BU_:  Airbag BAP_Tester ICAS1_Gateway ICAS1_KommunikationsServer LE1 LE2 Motor_BEV Schaltbetaetigung

BU_:  Airbag BAP_Tester ICAS1_Gateway ICAS1_KommunikationsServer LE1 LE2 Motor_BEV Schaltbetaetigung

BO_ 2463978663 VZE_04: 32 ICAS1_Gateway
 SG_ VZE_Anzeigemodus  : 0|2@1+ (1.000000,0.000000) [0.000000|3.000000] "" Vector__XXX
 SG_ VZE_Hinweistext  : 2|3@1+ (1.000000,0.000000) [1.000000|7.000000] "" Motor_BEV
 SG_ VZE_Verkehrszeichen_Einheit  : 8|1@1+ (1.000000,0.000000) [0.000000|1.000000] "" Vector__XXX
 SG_ VZE_Anzeigeunterdrueck_Zeichen_3  : 9|1@1+ (1.000000,0.000000) [0.000000|1.000000] "" Vector__XXX
 SG_ VZE_Anzeigeunterdrueck_Zeichen_2  : 10|1@1+ (1.000000,0.000000) [0.000000|1.000000] "" Vector__XXX
 SG_ VZE_Verkehrszeichen_1  : 11|8@1+ (1.000000,0.000000) [1.000000|255.000000] "" Motor_BEV
 SG_ VZE_Verkehrszeichen_2  : 19|8@1+ (1.000000,0.000000) [1.000000|255.000000] "" Vector__XXX
 SG_ VZE_Verkehrszeichen_3  : 27|8@1+ (1.000000,0.000000) [1.000000|255.000000] "" Vector__XXX
 SG_ VZE_Warnung_Verkehrszeichen_1  : 35|1@1+ (1.000000,0.000000) [0.000000|1.000000] "" Vector__XXX
 SG_ VZE_Warnung_Verkehrszeichen_2  : 36|1@1+ (1.000000,0.000000) [0.000000|1.000000] "" Vector__XXX
 SG_ VZE_Warnung_Verkehrszeichen_3  : 37|1@1+ (1.000000,0.000000) [0.000000|1.000000] "" Vector__XXX
 SG_ VZE_Zusatzschild_1  : 38|4@1+ (1.000000,0.000000) [1.000000|15.000000] "" Vector__XXX
 SG_ VZE_Zusatzschild_2  : 42|4@1+ (1.000000,0.000000) [1.000000|15.000000] "" Vector__XXX
 SG_ VZE_Zusatzschild_3  : 46|4@1+ (1.000000,0.000000) [1.000000|15.000000] "" Vector__XXX
 SG_ VZE_Anzeigeunterdrueck_Zeichen_1  : 50|1@1+ (1.000000,0.000000) [0.000000|1.000000] "" Vector__XXX
 SG_ VZE_Zeichen_01_KameraWied  : 51|1@1+ (1.000000,0.000000) [0.000000|1.000000] "" Motor_BEV
 SG_ VZE_Zeichen_02_KameraWied  : 52|1@1+ (1.000000,0.000000) [0.000000|1.000000] "" Vector__XXX
 SG_ VZE_Zeichen_03_KameraWied  : 53|1@1+ (1.000000,0.000000) [0.000000|1.000000] "" Vector__XXX
 SG_ VZE_Zeichen_01_Kamera  : 54|1@1+ (1.000000,0.000000) [0.000000|1.000000] "" Motor_BEV
 SG_ VZE_Zeichen_01_Karte  : 55|1@1+ (1.000000,0.000000) [0.000000|1.000000] "" Vector__XXX
 SG_ VZE_Zeichen_01_Gesetz  : 56|1@1+ (1.000000,0.000000) [0.000000|1.000000] "" Vector__XXX
 SG_ VZE_Zeichen_02_Kamera  : 57|1@1+ (1.000000,0.000000) [0.000000|1.000000] "" Vector__XXX
 SG_ VZE_Zeichen_02_Karte  : 58|1@1+ (1.000000,0.000000) [0.000000|1.000000] "" Vector__XXX
 SG_ VZE_Zeichen_02_Gesetz  : 59|1@1+ (1.000000,0.000000) [0.000000|1.000000] "" Vector__XXX
 SG_ VZE_Zeichen_03_Kamera  : 60|1@1+ (1.000000,0.000000) [0.000000|1.000000] "" Vector__XXX
 SG_ VZE_Zeichen_03_Karte  : 61|1@1+ (1.000000,0.000000) [0.000000|1.000000] "" Vector__XXX
 SG_ VZE_Zeichen_03_Gesetz  : 62|1@1+ (1.000000,0.000000) [0.000000|1.000000] "" Vector__XXX
 SG_ VZE_Gong  : 63|1@1+ (1.000000,0.000000) [0.000000|1.000000] "" Vector__XXX
 SG_ VZE_Anzeigeunterdrueck_Zeichen_5  : 72|1@1+ (1.000000,0.000000) [0.000000|1.000000] "" Vector__XXX
 SG_ VZE_Zeichen_05_KameraWied  : 73|1@1+ (1.000000,0.000000) [0.000000|1.000000] "" Vector__XXX
 SG_ VZE_Zeichen_05_Kamera  : 74|1@1+ (1.000000,0.000000) [0.000000|1.000000] "" Vector__XXX
 SG_ VZE_Verkehrszeichen_4  : 75|8@1+ (1.000000,0.000000) [1.000000|255.000000] "" Motor_BEV
 SG_ VZE_Verkehrszeichen_5  : 83|8@1+ (1.000000,0.000000) [1.000000|255.000000] "" Motor_BEV
 SG_ VZE_Anhaenger_Vmax  : 91|4@1+ (10.000000,10.000000) [10.000000|140.000000] "Unit_KiloMeterPerHour" Vector__XXX
 SG_ VZE_Zeichen_04_Gesetz  : 95|1@1+ (1.000000,0.000000) [0.000000|1.000000] "" Vector__XXX
 SG_ VZE_Zeichen_04_Kamera  : 96|1@1+ (1.000000,0.000000) [0.000000|1.000000] "" Vector__XXX
 SG_ VZE_Zeichen_04_KameraWied  : 97|1@1+ (1.000000,0.000000) [0.000000|1.000000] "" Vector__XXX
 SG_ VZE_Zeichen_04_Karte  : 98|1@1+ (1.000000,0.000000) [0.000000|1.000000] "" Vector__XXX
 SG_ VZE_Warnung_Verkehrszeichen_4  : 99|1@1+ (1.000000,0.000000) [0.000000|1.000000] "" Vector__XXX
 SG_ VZE_Warnung_Verkehrszeichen_5  : 100|1@1+ (1.000000,0.000000) [0.000000|1.000000] "" Vector__XXX
 SG_ VZE_Zeichen_05_Gesetz  : 101|1@1+ (1.000000,0.000000) [0.000000|1.000000] "" Vector__XXX
 SG_ VZE_Zusatzschild_4  : 102|4@1+ (1.000000,0.000000) [1.000000|15.000000] "" Vector__XXX
 SG_ VZE_Zusatzschild_5  : 106|4@1+ (1.000000,0.000000) [1.000000|15.000000] "" Vector__XXX
 SG_ VZE_Baustelle  : 110|2@1+ (1.000000,0.000000) [0.000000|3.000000] "" Vector__XXX
 SG_ VZE_Zeichen_05_Karte  : 112|1@1+ (1.000000,0.000000) [0.000000|1.000000] "" Vector__XXX
 SG_ VZE_Zeichen_05_Entfernung  : 113|7@1+ (1.000000,0.000000) [1.000000|127.000000] "Unit_Meter" Motor_BEV
 SG_ VZE_Zeichen_05_Entfernung_StdA  : 120|7@1+ (1.000000,0.000000) [1.000000|127.000000] "Unit_Meter" Motor_BEV
 SG_ VZE_Anzeigeunterdrueck_Zeichen_4  : 127|1@1+ (1.000000,0.000000) [0.000000|1.000000] "" Vector__XXX
 SG_ VZE_Verkehrszeichen_6  : 128|8@1+ (1.000000,0.000000) [1.000000|255.000000] "Unit_None" Motor_BEV
 SG_ VZE_Zusatzschild_6  : 136|4@1+ (1.000000,0.000000) [1.000000|15.000000] "" Vector__XXX
 SG_ VZE_Zeichen_06_Entfernung  : 140|7@1+ (1.000000,0.000000) [1.000000|127.000000] "Unit_Meter" Motor_BEV
 SG_ VZE_Zeichen_06_Entfernung_StdA  : 147|7@1+ (1.000000,0.000000) [1.000000|127.000000] "Unit_Meter" Motor_BEV
 SG_ VZE_Umweltinfo_Naesse  : 154|1@1+ (1.000000,0.000000) [0.000000|1.000000] "" Motor_BEV
 SG_ VZE_Umweltinfo_Nebel  : 155|1@1+ (1.000000,0.000000) [0.000000|1.000000] "" Motor_BEV
 SG_ VZE_Umweltinfo_Anhaengerbetrieb  : 156|1@1+ (1.000000,0.000000) [0.000000|1.000000] "" Vector__XXX
 SG_ VZE_Erweiterte_Information  : 157|8@1+ (1.000000,0.000000) [1.000000|255.000000] "Unit_None" Vector__XXX
 SG_ VZE_Tempowarnung_Status  : 165|1@1+ (1.000000,0.000000) [0.000000|1.000000] "" Vector__XXX
 SG_ VZE_Tempowarnung_Einheit  : 166|1@1+ (1.000000,0.000000) [0.000000|1.000000] "" Vector__XXX
 SG_ VZE_Tempowarnung_Offset  : 167|5@1+ (1.000000,0.000000) [1.000000|31.000000] "" Vector__XXX
 SG_ VZE_FoD_Status  : 206|2@1+ (1.000000,0.000000) [0.000000|3.000000] "" Vector__XXX
 SG_ VZE_Anzeige_ZS_1  : 208|4@1+ (1.000000,0.000000) [1.000000|15.000000] "Unit_None" Vector__XXX
 SG_ VZE_Anzeige_ZS_2  : 212|4@1+ (1.000000,0.000000) [1.000000|15.000000] "Unit_None" Vector__XXX
 SG_ VZE_Anzeige_ZS_3  : 216|4@1+ (1.000000,0.000000) [1.000000|15.000000] "Unit_None" Vector__XXX
 SG_ VZE_Hinweistext_03  : 220|4@1+ (1.000000,0.000000) [1.000000|15.000000] "" Vector__XXX
 SG_ VZE_Land  : 224|5@1+ (1.000000,0.000000) [1.000000|31.000000] "" Vector__XXX
 SG_ VZE_Warnung_VZ_1  : 229|1@1+ (1.000000,0.000000) [0.000000|1.000000] "" Vector__XXX
 SG_ VZE_Warnung_VZ_2  : 230|1@1+ (1.000000,0.000000) [0.000000|1.000000] "" Vector__XXX
 SG_ VZE_Warnung_VZ_3  : 231|1@1+ (1.000000,0.000000) [0.000000|1.000000] "" Vector__XXX
 SG_ VZE_Anzeige_VZ_1  : 232|8@1+ (1.000000,0.000000) [1.000000|255.000000] "" Vector__XXX
 SG_ VZE_Anzeige_VZ_2  : 240|8@1+ (1.000000,0.000000) [1.000000|255.000000] "Unit_None" Vector__XXX
 SG_ VZE_Anzeige_VZ_3  : 248|8@1+ (1.000000,0.000000) [1.000000|255.000000] "Unit_None" Vector__XXX

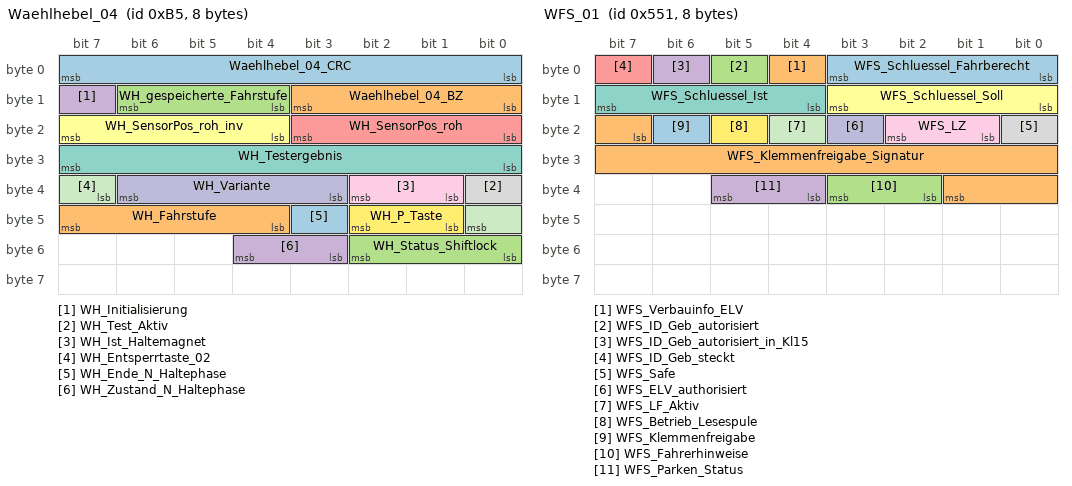
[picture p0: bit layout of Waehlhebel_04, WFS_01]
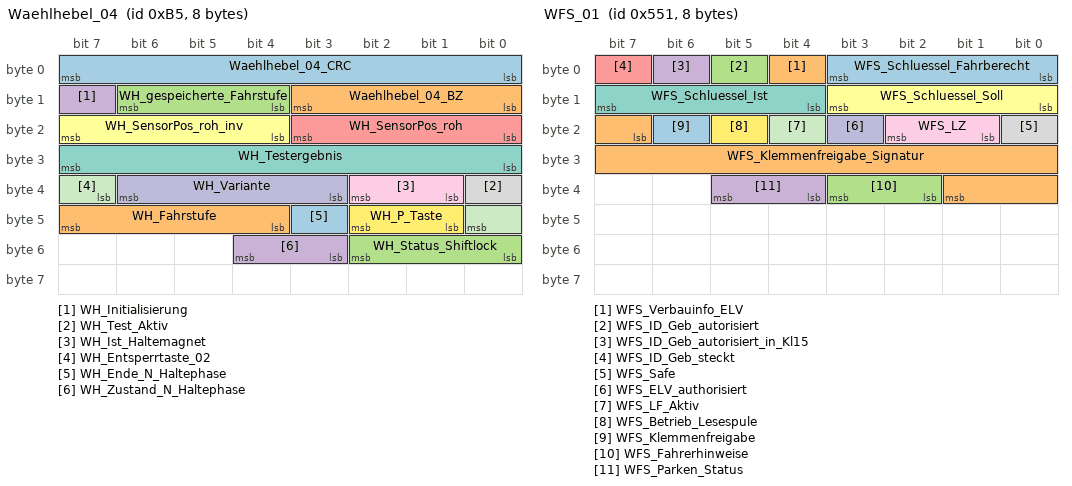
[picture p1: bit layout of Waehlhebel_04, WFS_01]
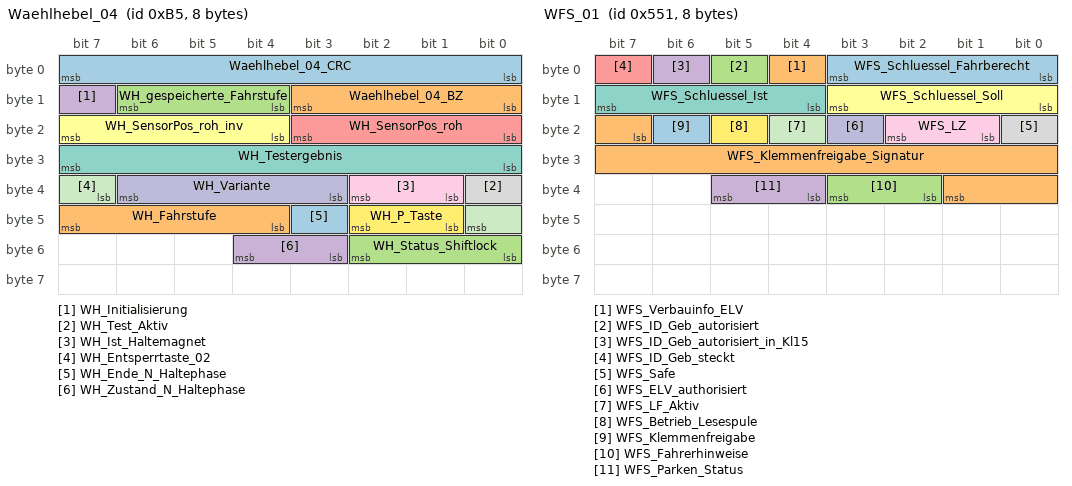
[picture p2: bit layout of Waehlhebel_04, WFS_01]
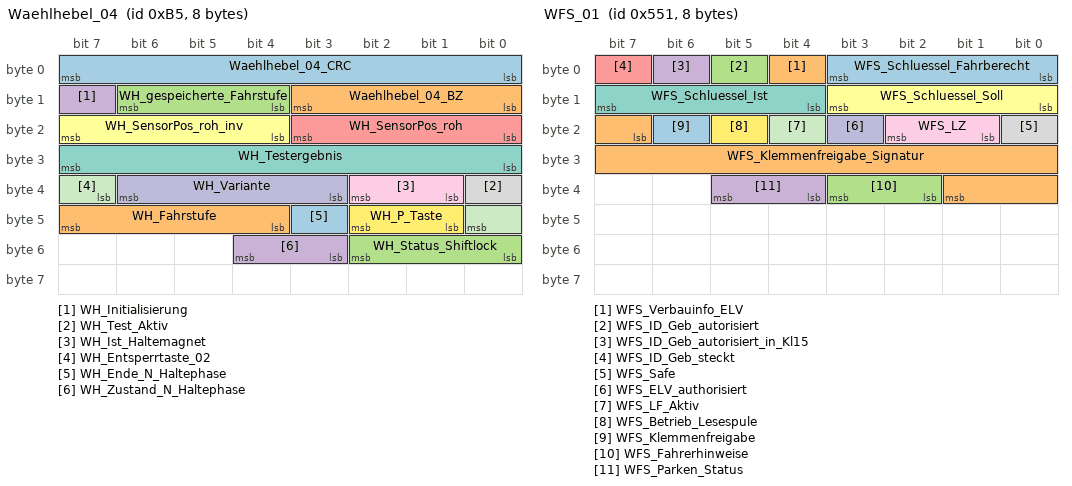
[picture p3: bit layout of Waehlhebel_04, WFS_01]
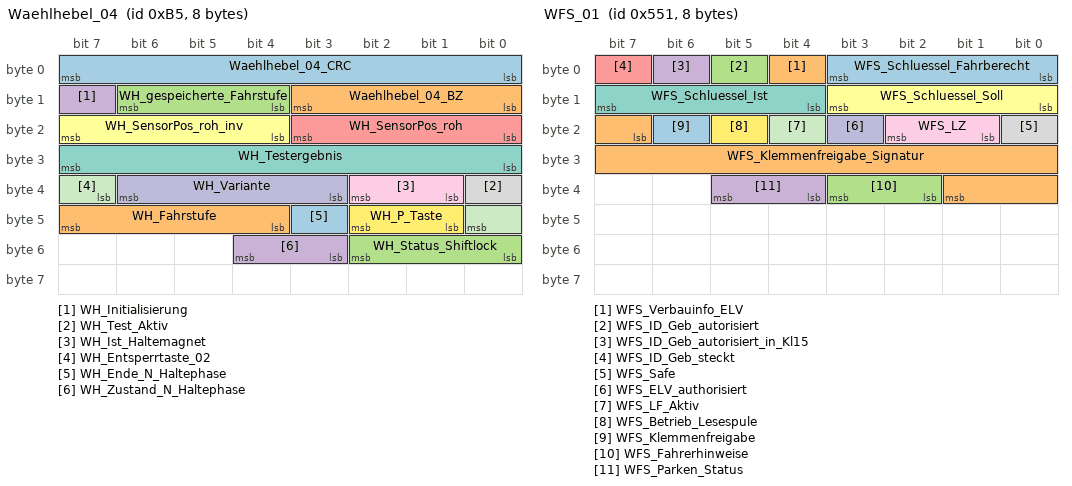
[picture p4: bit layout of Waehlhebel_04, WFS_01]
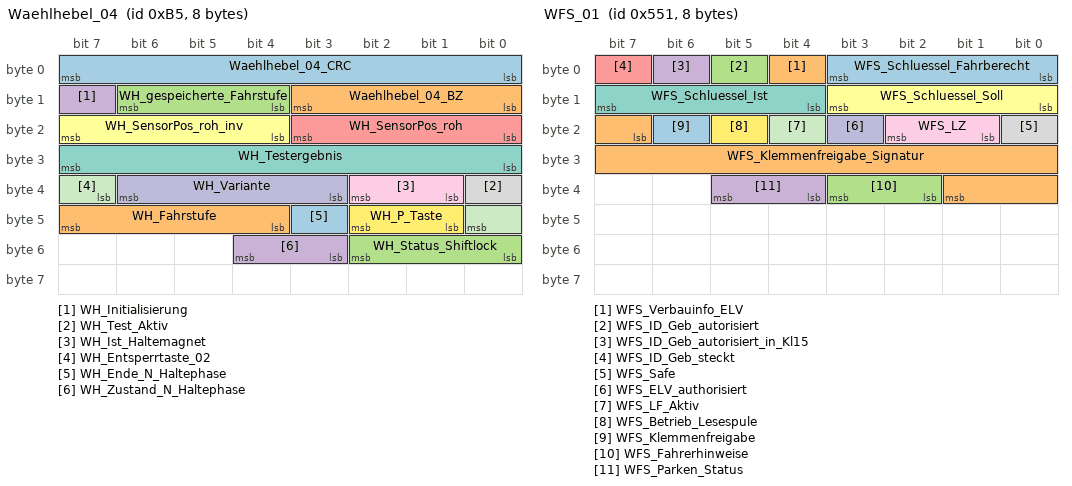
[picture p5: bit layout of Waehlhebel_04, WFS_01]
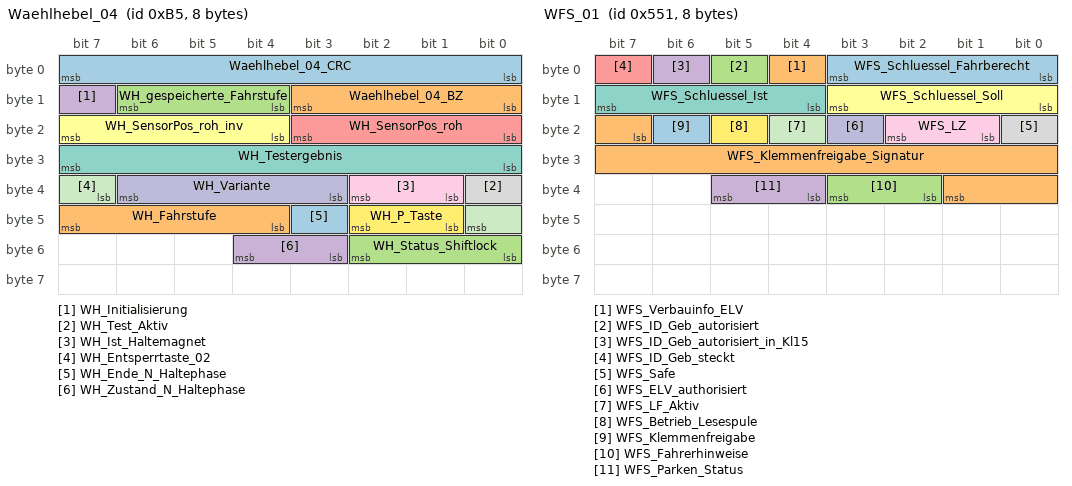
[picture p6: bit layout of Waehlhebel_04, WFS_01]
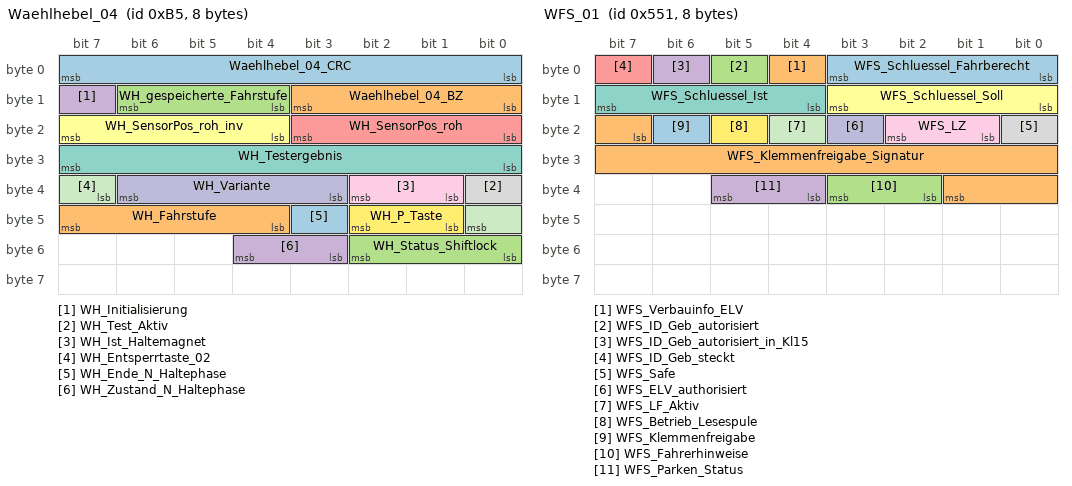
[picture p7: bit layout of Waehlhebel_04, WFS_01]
BO_ 181 Waehlhebel_04: 8 ICAS1_Gateway
 SG_ Waehlhebel_04_CRC  : 0|8@1+ (1.000000,0.000000) [0.000000|255.000000] "" Motor_BEV
 SG_ Waehlhebel_04_BZ  : 8|4@1+ (1.000000,0.000000) [0.000000|15.000000] "" Motor_BEV
 SG_ WH_gespeicherte_Fahrstufe  : 12|3@1+ (1.000000,0.000000) [0.000000|7.000000] "" Vector__XXX
 SG_ WH_Initialisierung  : 15|1@1+ (1.000000,0.000000) [0.000000|1.000000] "" Motor_BEV
 SG_ WH_SensorPos_roh  : 16|4@1+ (1.000000,0.000000) [0.000000|15.000000] "" Motor_BEV
 SG_ WH_SensorPos_roh_inv  : 20|4@1+ (1.000000,0.000000) [0.000000|15.000000] "" Motor_BEV
 SG_ WH_Testergebnis  : 24|8@1+ (1.000000,0.000000) [0.000000|255.000000] "" Vector__XXX
 SG_ WH_Test_Aktiv  : 32|1@1+ (1.000000,0.000000) [0.000000|1.000000] "" Vector__XXX
 SG_ WH_Ist_Haltemagnet  : 33|2@1+ (1.000000,0.000000) [0.000000|3.000000] "" Motor_BEV
 SG_ WH_Variante  : 35|4@1+ (1.000000,0.000000) [0.000000|15.000000] "" Motor_BEV
 SG_ WH_Entsperrtaste_02  : 39|2@1+ (1.000000,0.000000) [0.000000|3.000000] "" Motor_BEV
 SG_ WH_P_Taste  : 41|2@1+ (1.000000,0.000000) [0.000000|3.000000] "" Motor_BEV
 SG_ WH_Ende_N_Haltephase  : 43|1@1+ (1.000000,0.000000) [0.000000|1.000000] "" Vector__XXX
 SG_ WH_Fahrstufe  : 44|4@1+ (1.000000,0.000000) [0.000000|15.000000] "" Motor_BEV
 SG_ WH_Status_Shiftlock  : 48|3@1+ (1.000000,0.000000) [0.000000|7.000000] "" Motor_BEV
 SG_ WH_Zustand_N_Haltephase  : 51|2@1+ (1.000000,0.000000) [0.000000|3.000000] "" Vector__XXX

BO_ 2463978687 Waehlhebel_06: 8 ICAS1_Gateway
 SG_ WH_Fehler_Haltemagnet_Status  : 41|1@1+ (1.000000,0.000000) [0.000000|1.000000] "" Motor_BEV
 SG_ WH_Fehler_CRC_SBM  : 42|1@1+ (1.000000,0.000000) [0.000000|1.000000] "" Motor_BEV
 SG_ WH_Fehler_CRC_SBM_Status  : 43|1@1+ (1.000000,0.000000) [0.000000|1.000000] "" Motor_BEV
 SG_ WH_Fehler_Timeout_SBM  : 44|1@1+ (1.000000,0.000000) [0.000000|1.000000] "" Motor_BEV
 SG_ WH_Fehler_Timeout_SBM_Status  : 45|1@1+ (1.000000,0.000000) [0.000000|1.000000] "" Motor_BEV
 SG_ WH_Fehler_Ueberspannung  : 46|1@1+ (1.000000,0.000000) [0.000000|1.000000] "" Motor_BEV
 SG_ WH_Fehler_Ueberspannung_Status  : 47|1@1+ (1.000000,0.000000) [0.000000|1.000000] "" Motor_BEV
 SG_ WH_Fehler_BZ_SBM  : 48|1@1+ (1.000000,0.000000) [0.000000|1.000000] "" Motor_BEV
 SG_ WH_Fehler_BZ_SBM_Status  : 49|1@1+ (1.000000,0.000000) [0.000000|1.000000] "" Motor_BEV
 SG_ WH_Fehler_Unterspannung  : 50|1@1+ (1.000000,0.000000) [0.000000|1.000000] "" Motor_BEV
 SG_ WH_Fehler_Unterspannung_Status  : 51|1@1+ (1.000000,0.000000) [0.000000|1.000000] "" Motor_BEV
 SG_ WH_Fehler_Ausleuchtung  : 52|1@1+ (1.000000,0.000000) [0.000000|1.000000] "" Motor_BEV
 SG_ WH_Fehler_Ausleuchtung_Status  : 53|1@1+ (1.000000,0.000000) [0.000000|1.000000] "" Motor_BEV
 SG_ WH_Fehler_Entsperrtaste  : 54|1@1+ (1.000000,0.000000) [0.000000|1.000000] "" Motor_BEV
 SG_ WH_Fehler_Entsperrtaste_Status  : 55|1@1+ (1.000000,0.000000) [0.000000|1.000000] "" Motor_BEV
 SG_ WH_Fehler_P_Taste  : 56|1@1+ (1.000000,0.000000) [0.000000|1.000000] "" Motor_BEV
 SG_ WH_Fehler_P_Taste_Status  : 57|1@1+ (1.000000,0.000000) [0.000000|1.000000] "" Motor_BEV
 SG_ WH_Fehler_Sensor_einfach  : 58|1@1+ (1.000000,0.000000) [0.000000|1.000000] "" Motor_BEV
 SG_ WH_Fehler_Sensor_einfach_Status  : 59|1@1+ (1.000000,0.000000) [0.000000|1.000000] "" Motor_BEV
 SG_ WH_Fehler_Sensor_mehrfach  : 60|1@1+ (1.000000,0.000000) [0.000000|1.000000] "" Motor_BEV
 SG_ WH_Fehler_Sensor_mehrfach_Status  : 61|1@1+ (1.000000,0.000000) [0.000000|1.000000] "" Motor_BEV
 SG_ WH_Fehler_Shiftlock  : 62|1@1+ (1.000000,0.000000) [0.000000|1.000000] "" Motor_BEV
 SG_ WH_Fehler_Shiftlock_Status  : 63|1@1+ (1.000000,0.000000) [0.000000|1.000000] "" Motor_BEV

BO_ 916 WBA_03: 8 Motor_BEV
 SG_ WBA_03_CRC  : 0|8@1+ (1.000000,0.000000) [0.000000|255.000000] "" ICAS1_Gateway
 SG_ WBA_03_BZ  : 8|4@1+ (1.000000,0.000000) [0.000000|15.000000] "" ICAS1_Gateway
 SG_ WBA_Fahrstufe_02  : 12|4@1+ (1.000000,0.000000) [0.000000|15.000000] "" ICAS1_Gateway ICAS1_KommunikationsServer
 SG_ WBA_ZielFahrstufe  : 16|4@1+ (1.000000,0.000000) [0.000000|15.000000] "" ICAS1_Gateway
 SG_ WBA_GE_Warnung_02  : 20|4@1+ (1.000000,0.000000) [0.000000|15.000000] "" ICAS1_Gateway
 SG_ WBA_eing_Gang_02  : 24|4@1+ (1.000000,0.000000) [0.000000|15.000000] "" ICAS1_Gateway
 SG_ WBA_GE_Texte  : 28|3@1+ (1.000000,0.000000) [0.000000|7.000000] "" ICAS1_Gateway
 SG_ WBA_Segeln_aktiv  : 31|1@1+ (1.000000,0.000000) [0.000000|1.000000] "" ICAS1_Gateway
 SG_ WBA_Schaltschema_02  : 32|3@1+ (1.000000,0.000000) [0.000000|7.000000] "" ICAS1_Gateway
 SG_ WBA_Schaltschema_FS_inaktiv  : 35|2@1+ (1.000000,0.000000) [0.000000|3.000000] "" ICAS1_Gateway
 SG_ WBA_GE_Zusatzwarnungen  : 37|3@1+ (1.000000,0.000000) [0.000000|7.000000] "" ICAS1_Gateway
 SG_ GE_Sollgang  : 40|4@1+ (1.000000,0.000000) [0.000000|15.000000] "" ICAS1_Gateway
 SG_ GE_Tipschaltempf_verfuegbar  : 44|1@1+ (1.000000,0.000000) [0.000000|1.000000] "" ICAS1_Gateway
 SG_ WBA_GE_Texte_02  : 45|3@1+ (1.000000,0.000000) [0.000000|7.000000] "" ICAS1_Gateway
 SG_ WBA_Schaltschema_Tippgasse  : 48|1@1+ (1.000000,0.000000) [0.000000|1.000000] "" ICAS1_Gateway
 SG_ WBA_Schaltschema_Fahreraktion  : 49|1@1+ (1.000000,0.000000) [0.000000|1.000000] "" ICAS1_Gateway
 SG_ WBA_Schaltschema_FS_vorwaerts  : 50|2@1+ (1.000000,0.000000) [0.000000|3.000000] "" ICAS1_Gateway
 SG_ WBA_Shiftlock_Lampe  : 52|1@1+ (1.000000,0.000000) [0.000000|1.000000] "" ICAS1_Gateway
 SG_ WBA_Anforderung_Akustik  : 53|1@1+ (1.000000,0.000000) [0.000000|1.000000] "" ICAS1_Gateway
 SG_ WBA_Blinken  : 54|1@1+ (1.000000,0.000000) [0.000000|1.000000] "" ICAS1_Gateway
 SG_ GE_Wiederstart_Anz_Std  : 55|1@1+ (1.000000,0.000000) [0.000000|1.000000] "" ICAS1_Gateway
 SG_ GE_Stoppverbot_Anz_01  : 56|1@1+ (1.000000,0.000000) [0.000000|1.000000] "" ICAS1_Gateway
 SG_ GE_Stoppverbot_Anz_02  : 57|1@1+ (1.000000,0.000000) [0.000000|1.000000] "" ICAS1_Gateway
 SG_ GE_Stoppverbot_Anz_03  : 58|1@1+ (1.000000,0.000000) [0.000000|1.000000] "" ICAS1_Gateway
 SG_ GE_Stoppverbot_Anz_04  : 59|1@1+ (1.000000,0.000000) [0.000000|1.000000] "" ICAS1_Gateway
 SG_ GE_Stoppverbot_Anz_05  : 60|1@1+ (1.000000,0.000000) [0.000000|1.000000] "" ICAS1_Gateway
 SG_ GE_Stoppverbot_Anz_06  : 61|1@1+ (1.000000,0.000000) [0.000000|1.000000] "" ICAS1_Gateway
 SG_ GE_Stoppverbot_Anz_07  : 62|1@1+ (1.000000,0.000000) [0.000000|1.000000] "" ICAS1_Gateway
 SG_ GE_Stoppverbot_Anz_Std  : 63|1@1+ (1.000000,0.000000) [0.000000|1.000000] "" ICAS1_Gateway

BO_ 1361 WFS_01: 8 ICAS1_Gateway
 SG_ WFS_Schluessel_Fahrberecht  : 0|4@1+ (1.000000,0.000000) [0.000000|15.000000] "" Vector__XXX
 SG_ WFS_Verbauinfo_ELV  : 4|1@1+ (1.000000,0.000000) [0.000000|1.000000] "" Vector__XXX
 SG_ WFS_ID_Geb_autorisiert  : 5|1@1+ (1.000000,0.000000) [0.000000|1.000000] "" Vector__XXX
 SG_ WFS_ID_Geb_autorisiert_in_Kl15  : 6|1@1+ (1.000000,0.000000) [0.000000|1.000000] "" Vector__XXX
 SG_ WFS_ID_Geb_steckt  : 7|1@1+ (1.000000,0.000000) [0.000000|1.000000] "" Vector__XXX
 SG_ WFS_Schluessel_Soll  : 8|4@1+ (1.000000,0.000000) [0.000000|15.000000] "" Vector__XXX
 SG_ WFS_Schluessel_Ist  : 12|4@1+ (1.000000,0.000000) [0.000000|15.000000] "" Vector__XXX
 SG_ WFS_Safe  : 16|1@1+ (1.000000,0.000000) [0.000000|1.000000] "" Vector__XXX
 SG_ WFS_LZ  : 17|2@1+ (1.000000,0.000000) [0.000000|3.000000] "" Vector__XXX
 SG_ WFS_ELV_authorisiert  : 19|1@1+ (1.000000,0.000000) [0.000000|1.000000] "" Vector__XXX
 SG_ WFS_LF_Aktiv  : 20|1@1+ (1.000000,0.000000) [0.000000|1.000000] "" Vector__XXX
 SG_ WFS_Betrieb_Lesespule  : 21|1@1+ (1.000000,0.000000) [0.000000|1.000000] "" Vector__XXX
 SG_ WFS_Klemmenfreigabe  : 22|1@1+ (1.000000,0.000000) [0.000000|1.000000] "" Motor_BEV
 SG_ WFS_Klemmenfreigabe_Signatur  : 23|11@1+ (1.000000,0.000000) [0.000000|2047.000000] "" Vector__XXX
 SG_ WFS_Fahrerhinweise  : 34|2@1+ (1.000000,0.000000) [0.000000|3.000000] "" Vector__XXX
 SG_ WFS_Parken_Status  : 36|2@1+ (1.000000,0.000000) [0.000000|3.000000] "" Vector__XXX

BO_ 2617028096 XCP_Airbag_CRO_01: 64 Vector__XXX
 SG_ XCP_Airbag_CRO_01_Data  : 0|512@1+ (1.000000,0.000000) [0.000000|13407807929942597099574024998205846127479365820592393377723561443721764030073546976801874298166903427690031858186486050853753882811946569946433649006084096.000000] "" Airbag

BO_ 2617028097 XCP_Airbag_DTO_01: 64 Airbag
 SG_ XCP_Airbag_DTO_01_Data  : 0|512@1+ (1.000000,0.000000) [0.000000|13407807929942597099574024998205846127479365820592393377723561443721764030073546976801874298166903427690031858186486050853753882811946569946433649006084096.000000] "" Vector__XXX

BO_ 2617239040 XCP_EMotor_01_CRO_01: 64 Vector__XXX
 SG_ XCP_EMotor_01_CRO_01_Data  : 0|64@1+ (1.000000,0.000000) [0.000000|18446744073709551616.000000] "" LE1

BO_ 2617239041 XCP_EMotor_01_DTO_01: 64 LE1
 SG_ XCP_EMotor_01_DTO_01_Data  : 0|64@1+ (1.000000,0.000000) [0.000000|18446744073709551616.000000] "" Vector__XXX

BO_ 2617239042 XCP_EMotor_01_DTO_02: 64 LE1
 SG_ XCP_EMotor_01_DTO_02_Data  : 0|64@1+ (1.000000,0.000000) [0.000000|18446744073709551616.000000] "" Vector__XXX

BO_ 2617239043 XCP_EMotor_01_DTO_03: 64 LE1
 SG_ XCP_EMotor_01_DTO_03_Data  : 0|64@1+ (1.000000,0.000000) [0.000000|18446744073709551616.000000] "" Vector__XXX

BO_ 2617239044 XCP_EMotor_01_DTO_04: 64 LE1
 SG_ XCP_EMotor_01_DTO_04_Data  : 0|64@1+ (1.000000,0.000000) [0.000000|18446744073709551616.000000] "" Vector__XXX

BO_ 2617122304 XCP_EMotor_02_CRO_01: 64 Vector__XXX
 SG_ XCP_EMotor_02_CRO_01_Data  : 0|64@1+ (1.000000,0.000000) [0.000000|18446744073709551616.000000] "" LE2

BO_ 2617122305 XCP_EMotor_02_DTO_01: 64 LE2
 SG_ XCP_EMotor_02_DTO_01_Data  : 0|64@1+ (1.000000,0.000000) [0.000000|18446744073709551616.000000] "" Vector__XXX

BO_ 2617122306 XCP_EMotor_02_DTO_02: 64 LE2
 SG_ XCP_EMotor_02_DTO_02_Data  : 0|64@1+ (1.000000,0.000000) [0.000000|18446744073709551616.000000] "" Vector__XXX

BO_ 2617122307 XCP_EMotor_02_DTO_03: 64 LE2
 SG_ XCP_EMotor_02_DTO_03_Data  : 0|64@1+ (1.000000,0.000000) [0.000000|18446744073709551616.000000] "" Vector__XXX

BO_ 2617122308 XCP_EMotor_02_DTO_04: 64 LE2
 SG_ XCP_EMotor_02_DTO_04_Data  : 0|64@1+ (1.000000,0.000000) [0.000000|18446744073709551616.000000] "" Vector__XXX

BO_ 2617226768 XCP_Motor_CRO_01: 64 Vector__XXX
 SG_ XCP_Motor_CRO_01_Data  : 0|64@1+ (1.000000,0.000000) [0.000000|18446744073709551616.000000] "" Motor_BEV

BO_ 2617226769 XCP_Motor_DTO_01: 64 Motor_BEV
 SG_ XCP_Motor_DTO_01_Data  : 0|64@1+ (1.000000,0.000000) [0.000000|18446744073709551616.000000] "" Vector__XXX

BO_ 1411 ZV_02: 8 ICAS1_Gateway
 SG_ ZV_verriegeln_Anf  : 0|1@1+ (1.000000,0.000000) [0.000000|1.000000] "" Vector__XXX
 SG_ ZV_STSG_HFS_Anf  : 1|1@1+ (1.000000,0.000000) [0.000000|1.000000] "" Vector__XXX
 SG_ ZV_STSG_HBFS_Anf  : 2|1@1+ (1.000000,0.000000) [0.000000|1.000000] "" Vector__XXX
 SG_ ZV_Anf_Challenge_Auth  : 3|1@1+ (1.000000,0.000000) [0.000000|1.000000] "" Vector__XXX
 SG_ BCM_FH_Freigabe  : 12|1@1+ (1.000000,0.000000) [0.000000|1.000000] "" Vector__XXX
 SG_ BCM_Komfortfkt_Freigabe  : 13|1@1+ (1.000000,0.000000) [0.000000|1.000000] "" Vector__XXX
 SG_ BCM_HSK_Freigabe  : 14|1@1+ (1.000000,0.000000) [0.000000|1.000000] "" Vector__XXX
 SG_ BCM_Verdeck_Freigabe  : 15|1@1+ (1.000000,0.000000) [0.000000|1.000000] "" Vector__XXX
 SG_ ZV_verriegelt_intern_ist  : 16|1@1+ (1.000000,0.000000) [0.000000|1.000000] "" Vector__XXX
 SG_ ZV_verriegelt_extern_ist  : 17|1@1+ (1.000000,0.000000) [0.000000|1.000000] "" Airbag
 SG_ ZV_verriegelt_intern_soll  : 18|1@1+ (1.000000,0.000000) [0.000000|1.000000] "" Vector__XXX
 SG_ ZV_verriegelt_extern_soll  : 19|1@1+ (1.000000,0.000000) [0.000000|1.000000] "" Airbag
 SG_ ZV_gesafet_extern_ist  : 20|1@1+ (1.000000,0.000000) [0.000000|1.000000] "" Vector__XXX
 SG_ ZV_gesafet_extern_soll  : 21|1@1+ (1.000000,0.000000) [0.000000|1.000000] "" Vector__XXX
 SG_ ZV_Einzeltuerentriegelung  : 22|1@1+ (1.000000,0.000000) [0.000000|1.000000] "" Vector__XXX
 SG_ ZV_Heckeinzelentriegelung  : 23|1@1+ (1.000000,0.000000) [0.000000|1.000000] "" Vector__XXX
 SG_ ZV_FT_offen  : 24|1@1+ (1.000000,0.000000) [0.000000|1.000000] "" Motor_BEV
 SG_ ZV_BT_offen  : 25|1@1+ (1.000000,0.000000) [0.000000|1.000000] "" Motor_BEV
 SG_ ZV_HFS_offen  : 26|1@1+ (1.000000,0.000000) [0.000000|1.000000] "" Motor_BEV
 SG_ ZV_HBFS_offen  : 27|1@1+ (1.000000,0.000000) [0.000000|1.000000] "" Motor_BEV
 SG_ ZV_HD_offen  : 28|1@1+ (1.000000,0.000000) [0.000000|1.000000] "" Motor_BEV
 SG_ ZV_HS_offen  : 29|1@1+ (1.000000,0.000000) [0.000000|1.000000] "" Vector__XXX
 SG_ IRUE_aktiv  : 30|1@1+ (1.000000,0.000000) [0.000000|1.000000] "" Vector__XXX
 SG_ DWA_aktiv  : 31|1@1+ (1.000000,0.000000) [0.000000|1.000000] "" Vector__XXX
 SG_ FFB_HDF_Taste  : 34|1@1+ (1.000000,0.000000) [0.000000|1.000000] "" Vector__XXX
 SG_ FFB_Panik_Taste  : 35|1@1+ (1.000000,0.000000) [0.000000|1.000000] "" Vector__XXX
 SG_ FFB_Auf_Taste  : 36|1@1+ (1.000000,0.000000) [0.000000|1.000000] "" Vector__XXX
 SG_ FFB_Zu_Taste  : 37|1@1+ (1.000000,0.000000) [0.000000|1.000000] "" Vector__XXX
 SG_ FFB_CarFinder  : 38|1@1+ (1.000000,0.000000) [0.000000|1.000000] "" Vector__XXX
 SG_ FFB_Komfortoeffnen  : 39|1@1+ (1.000000,0.000000) [0.000000|1.000000] "" Vector__XXX
 SG_ FFB_Komfortschliessen  : 40|1@1+ (1.000000,0.000000) [0.000000|1.000000] "" Vector__XXX
 SG_ FBS_IDG_in_Reichweite  : 41|1@1+ (1.000000,0.000000) [0.000000|1.000000] "" Vector__XXX
 SG_ ZV_Schluessel_Zugang  : 42|4@1+ (1.000000,0.000000) [0.000000|15.000000] "" Vector__XXX
 SG_ ZV_SafeFunktion_aktiv  : 46|1@1+ (1.000000,0.000000) [0.000000|1.000000] "" Vector__XXX
 SG_ FBS_Warn_Schluessel_Batt  : 47|1@1+ (1.000000,0.000000) [0.000000|1.000000] "" Vector__XXX
 SG_ ZV_Oeffnungsmodus  : 48|2@1+ (1.000000,0.000000) [0.000000|3.000000] "" Vector__XXX
 SG_ ZV_ist_Zustand_verfuegbar  : 54|1@1+ (1.000000,0.000000) [0.000000|1.000000] "" Vector__XXX
 SG_ IRUE_Taster_Fkts_LED  : 55|1@1+ (1.000000,0.000000) [0.000000|1.000000] "" Vector__XXX
 SG_ ZV_Tankklappe_offen  : 56|1@1+ (1.000000,0.000000) [0.000000|1.000000] "" Vector__XXX
 SG_ ZV_Rollo_auf  : 57|1@1+ (1.000000,0.000000) [0.000000|1.000000] "" Vector__XXX
 SG_ ZV_Rollo_zu  : 58|1@1+ (1.000000,0.000000) [0.000000|1.000000] "" Vector__XXX
 SG_ ZV_SAD_auf  : 59|1@1+ (1.000000,0.000000) [0.000000|1.000000] "" Vector__XXX
 SG_ ZV_SAD_zu  : 60|1@1+ (1.000000,0.000000) [0.000000|1.000000] "" Vector__XXX
 SG_ ZV_verriegelt_soll  : 62|2@1+ (1.000000,0.000000) [0.000000|3.000000] "" Vector__XXX

BU_:  Airbag BAP_Tester ICAS1_Gateway ICAS1_KommunikationsServer LE1 LE2 Motor_BEV Schaltbetaetigung

BO_ 2463978663 VZE_04: 32 ICAS1_Gateway
 SG_ VZE_Anzeigemodus  : 0|2@1+ (1.000000,0.000000) [0.000000|3.000000] "" Vector__XXX
 SG_ VZE_Hinweistext  : 2|3@1+ (1.000000,0.000000) [1.000000|7.000000] "" Motor_BEV
 SG_ VZE_Verkehrszeichen_Einheit  : 8|1@1+ (1.000000,0.000000) [0.000000|1.000000] "" Vector__XXX
 SG_ VZE_Anzeigeunterdrueck_Zeichen_3  : 9|1@1+ (1.000000,0.000000) [0.000000|1.000000] "" Vector__XXX
 SG_ VZE_Anzeigeunterdrueck_Zeichen_2  : 10|1@1+ (1.000000,0.000000) [0.000000|1.000000] "" Vector__XXX
 SG_ VZE_Verkehrszeichen_1  : 11|8@1+ (1.000000,0.000000) [1.000000|255.000000] "" Motor_BEV
 SG_ VZE_Verkehrszeichen_2  : 19|8@1+ (1.000000,0.000000) [1.000000|255.000000] "" Vector__XXX
 SG_ VZE_Verkehrszeichen_3  : 27|8@1+ (1.000000,0.000000) [1.000000|255.000000] "" Vector__XXX
 SG_ VZE_Warnung_Verkehrszeichen_1  : 35|1@1+ (1.000000,0.000000) [0.000000|1.000000] "" Vector__XXX
 SG_ VZE_Warnung_Verkehrszeichen_2  : 36|1@1+ (1.000000,0.000000) [0.000000|1.000000] "" Vector__XXX
 SG_ VZE_Warnung_Verkehrszeichen_3  : 37|1@1+ (1.000000,0.000000) [0.000000|1.000000] "" Vector__XXX
 SG_ VZE_Zusatzschild_1  : 38|4@1+ (1.000000,0.000000) [1.000000|15.000000] "" Vector__XXX
 SG_ VZE_Zusatzschild_2  : 42|4@1+ (1.000000,0.000000) [1.000000|15.000000] "" Vector__XXX
 SG_ VZE_Zusatzschild_3  : 46|4@1+ (1.000000,0.000000) [1.000000|15.000000] "" Vector__XXX
 SG_ VZE_Anzeigeunterdrueck_Zeichen_1  : 50|1@1+ (1.000000,0.000000) [0.000000|1.000000] "" Vector__XXX
 SG_ VZE_Zeichen_01_KameraWied  : 51|1@1+ (1.000000,0.000000) [0.000000|1.000000] "" Motor_BEV
 SG_ VZE_Zeichen_02_KameraWied  : 52|1@1+ (1.000000,0.000000) [0.000000|1.000000] "" Vector__XXX
 SG_ VZE_Zeichen_03_KameraWied  : 53|1@1+ (1.000000,0.000000) [0.000000|1.000000] "" Vector__XXX
 SG_ VZE_Zeichen_01_Kamera  : 54|1@1+ (1.000000,0.000000) [0.000000|1.000000] "" Motor_BEV
 SG_ VZE_Zeichen_01_Karte  : 55|1@1+ (1.000000,0.000000) [0.000000|1.000000] "" Vector__XXX
 SG_ VZE_Zeichen_01_Gesetz  : 56|1@1+ (1.000000,0.000000) [0.000000|1.000000] "" Vector__XXX
 SG_ VZE_Zeichen_02_Kamera  : 57|1@1+ (1.000000,0.000000) [0.000000|1.000000] "" Vector__XXX
 SG_ VZE_Zeichen_02_Karte  : 58|1@1+ (1.000000,0.000000) [0.000000|1.000000] "" Vector__XXX
 SG_ VZE_Zeichen_02_Gesetz  : 59|1@1+ (1.000000,0.000000) [0.000000|1.000000] "" Vector__XXX
 SG_ VZE_Zeichen_03_Kamera  : 60|1@1+ (1.000000,0.000000) [0.000000|1.000000] "" Vector__XXX
 SG_ VZE_Zeichen_03_Karte  : 61|1@1+ (1.000000,0.000000) [0.000000|1.000000] "" Vector__XXX
 SG_ VZE_Zeichen_03_Gesetz  : 62|1@1+ (1.000000,0.000000) [0.000000|1.000000] "" Vector__XXX
 SG_ VZE_Gong  : 63|1@1+ (1.000000,0.000000) [0.000000|1.000000] "" Vector__XXX
 SG_ VZE_Anzeigeunterdrueck_Zeichen_5  : 72|1@1+ (1.000000,0.000000) [0.000000|1.000000] "" Vector__XXX
 SG_ VZE_Zeichen_05_KameraWied  : 73|1@1+ (1.000000,0.000000) [0.000000|1.000000] "" Vector__XXX
 SG_ VZE_Zeichen_05_Kamera  : 74|1@1+ (1.000000,0.000000) [0.000000|1.000000] "" Vector__XXX
 SG_ VZE_Verkehrszeichen_4  : 75|8@1+ (1.000000,0.000000) [1.000000|255.000000] "" Motor_BEV
 SG_ VZE_Verkehrszeichen_5  : 83|8@1+ (1.000000,0.000000) [1.000000|255.000000] "" Motor_BEV
 SG_ VZE_Anhaenger_Vmax  : 91|4@1+ (10.000000,10.000000) [10.000000|140.000000] "Unit_KiloMeterPerHour" Vector__XXX
 SG_ VZE_Zeichen_04_Gesetz  : 95|1@1+ (1.000000,0.000000) [0.000000|1.000000] "" Vector__XXX
 SG_ VZE_Zeichen_04_Kamera  : 96|1@1+ (1.000000,0.000000) [0.000000|1.000000] "" Vector__XXX
 SG_ VZE_Zeichen_04_KameraWied  : 97|1@1+ (1.000000,0.000000) [0.000000|1.000000] "" Vector__XXX
 SG_ VZE_Zeichen_04_Karte  : 98|1@1+ (1.000000,0.000000) [0.000000|1.000000] "" Vector__XXX
 SG_ VZE_Warnung_Verkehrszeichen_4  : 99|1@1+ (1.000000,0.000000) [0.000000|1.000000] "" Vector__XXX
 SG_ VZE_Warnung_Verkehrszeichen_5  : 100|1@1+ (1.000000,0.000000) [0.000000|1.000000] "" Vector__XXX
 SG_ VZE_Zeichen_05_Gesetz  : 101|1@1+ (1.000000,0.000000) [0.000000|1.000000] "" Vector__XXX
 SG_ VZE_Zusatzschild_4  : 102|4@1+ (1.000000,0.000000) [1.000000|15.000000] "" Vector__XXX
 SG_ VZE_Zusatzschild_5  : 106|4@1+ (1.000000,0.000000) [1.000000|15.000000] "" Vector__XXX
 SG_ VZE_Baustelle  : 110|2@1+ (1.000000,0.000000) [0.000000|3.000000] "" Vector__XXX
 SG_ VZE_Zeichen_05_Karte  : 112|1@1+ (1.000000,0.000000) [0.000000|1.000000] "" Vector__XXX
 SG_ VZE_Zeichen_05_Entfernung  : 113|7@1+ (1.000000,0.000000) [1.000000|127.000000] "Unit_Meter" Motor_BEV
 SG_ VZE_Zeichen_05_Entfernung_StdA  : 120|7@1+ (1.000000,0.000000) [1.000000|127.000000] "Unit_Meter" Motor_BEV
 SG_ VZE_Anzeigeunterdrueck_Zeichen_4  : 127|1@1+ (1.000000,0.000000) [0.000000|1.000000] "" Vector__XXX
 SG_ VZE_Verkehrszeichen_6  : 128|8@1+ (1.000000,0.000000) [1.000000|255.000000] "Unit_None" Motor_BEV
 SG_ VZE_Zusatzschild_6  : 136|4@1+ (1.000000,0.000000) [1.000000|15.000000] "" Vector__XXX
 SG_ VZE_Zeichen_06_Entfernung  : 140|7@1+ (1.000000,0.000000) [1.000000|127.000000] "Unit_Meter" Motor_BEV
 SG_ VZE_Zeichen_06_Entfernung_StdA  : 147|7@1+ (1.000000,0.000000) [1.000000|127.000000] "Unit_Meter" Motor_BEV
 SG_ VZE_Umweltinfo_Naesse  : 154|1@1+ (1.000000,0.000000) [0.000000|1.000000] "" Motor_BEV
 SG_ VZE_Umweltinfo_Nebel  : 155|1@1+ (1.000000,0.000000) [0.000000|1.000000] "" Motor_BEV
 SG_ VZE_Umweltinfo_Anhaengerbetrieb  : 156|1@1+ (1.000000,0.000000) [0.000000|1.000000] "" Vector__XXX
 SG_ VZE_Erweiterte_Information  : 157|8@1+ (1.000000,0.000000) [1.000000|255.000000] "Unit_None" Vector__XXX
 SG_ VZE_Tempowarnung_Status  : 165|1@1+ (1.000000,0.000000) [0.000000|1.000000] "" Vector__XXX
 SG_ VZE_Tempowarnung_Einheit  : 166|1@1+ (1.000000,0.000000) [0.000000|1.000000] "" Vector__XXX
 SG_ VZE_Tempowarnung_Offset  : 167|5@1+ (1.000000,0.000000) [1.000000|31.000000] "" Vector__XXX
 SG_ VZE_FoD_Status  : 206|2@1+ (1.000000,0.000000) [0.000000|3.000000] "" Vector__XXX
 SG_ VZE_Anzeige_ZS_1  : 208|4@1+ (1.000000,0.000000) [1.000000|15.000000] "Unit_None" Vector__XXX
 SG_ VZE_Anzeige_ZS_2  : 212|4@1+ (1.000000,0.000000) [1.000000|15.000000] "Unit_None" Vector__XXX
 SG_ VZE_Anzeige_ZS_3  : 216|4@1+ (1.000000,0.000000) [1.000000|15.000000] "Unit_None" Vector__XXX
 SG_ VZE_Hinweistext_03  : 220|4@1+ (1.000000,0.000000) [1.000000|15.000000] "" Vector__XXX
 SG_ VZE_Land  : 224|5@1+ (1.000000,0.000000) [1.000000|31.000000] "" Vector__XXX
 SG_ VZE_Warnung_VZ_1  : 229|1@1+ (1.000000,0.000000) [0.000000|1.000000] "" Vector__XXX
 SG_ VZE_Warnung_VZ_2  : 230|1@1+ (1.000000,0.000000) [0.000000|1.000000] "" Vector__XXX
 SG_ VZE_Warnung_VZ_3  : 231|1@1+ (1.000000,0.000000) [0.000000|1.000000] "" Vector__XXX
 SG_ VZE_Anzeige_VZ_1  : 232|8@1+ (1.000000,0.000000) [1.000000|255.000000] "" Vector__XXX
 SG_ VZE_Anzeige_VZ_2  : 240|8@1+ (1.000000,0.000000) [1.000000|255.000000] "Unit_None" Vector__XXX
 SG_ VZE_Anzeige_VZ_3  : 248|8@1+ (1.000000,0.000000) [1.000000|255.000000] "Unit_None" Vector__XXX

BO_ 181 Waehlhebel_04: 8 ICAS1_Gateway
 SG_ Waehlhebel_04_CRC  : 0|8@1+ (1.000000,0.000000) [0.000000|255.000000] "" Motor_BEV
 SG_ Waehlhebel_04_BZ  : 8|4@1+ (1.000000,0.000000) [0.000000|15.000000] "" Motor_BEV
 SG_ WH_gespeicherte_Fahrstufe  : 12|3@1+ (1.000000,0.000000) [0.000000|7.000000] "" Vector__XXX
 SG_ WH_Initialisierung  : 15|1@1+ (1.000000,0.000000) [0.000000|1.000000] "" Motor_BEV
 SG_ WH_SensorPos_roh  : 16|4@1+ (1.000000,0.000000) [0.000000|15.000000] "" Motor_BEV
 SG_ WH_SensorPos_roh_inv  : 20|4@1+ (1.000000,0.000000) [0.000000|15.000000] "" Motor_BEV
 SG_ WH_Testergebnis  : 24|8@1+ (1.000000,0.000000) [0.000000|255.000000] "" Vector__XXX
 SG_ WH_Test_Aktiv  : 32|1@1+ (1.000000,0.000000) [0.000000|1.000000] "" Vector__XXX
 SG_ WH_Ist_Haltemagnet  : 33|2@1+ (1.000000,0.000000) [0.000000|3.000000] "" Motor_BEV
 SG_ WH_Variante  : 35|4@1+ (1.000000,0.000000) [0.000000|15.000000] "" Motor_BEV
 SG_ WH_Entsperrtaste_02  : 39|2@1+ (1.000000,0.000000) [0.000000|3.000000] "" Motor_BEV
 SG_ WH_P_Taste  : 41|2@1+ (1.000000,0.000000) [0.000000|3.000000] "" Motor_BEV
 SG_ WH_Ende_N_Haltephase  : 43|1@1+ (1.000000,0.000000) [0.000000|1.000000] "" Vector__XXX
 SG_ WH_Fahrstufe  : 44|4@1+ (1.000000,0.000000) [0.000000|15.000000] "" Motor_BEV
 SG_ WH_Status_Shiftlock  : 48|3@1+ (1.000000,0.000000) [0.000000|7.000000] "" Motor_BEV
 SG_ WH_Zustand_N_Haltephase  : 51|2@1+ (1.000000,0.000000) [0.000000|3.000000] "" Vector__XXX

BO_ 2463978687 Waehlhebel_06: 8 ICAS1_Gateway
 SG_ WH_Fehler_Haltemagnet_Status  : 41|1@1+ (1.000000,0.000000) [0.000000|1.000000] "" Motor_BEV
 SG_ WH_Fehler_CRC_SBM  : 42|1@1+ (1.000000,0.000000) [0.000000|1.000000] "" Motor_BEV
 SG_ WH_Fehler_CRC_SBM_Status  : 43|1@1+ (1.000000,0.000000) [0.000000|1.000000] "" Motor_BEV
 SG_ WH_Fehler_Timeout_SBM  : 44|1@1+ (1.000000,0.000000) [0.000000|1.000000] "" Motor_BEV
 SG_ WH_Fehler_Timeout_SBM_Status  : 45|1@1+ (1.000000,0.000000) [0.000000|1.000000] "" Motor_BEV
 SG_ WH_Fehler_Ueberspannung  : 46|1@1+ (1.000000,0.000000) [0.000000|1.000000] "" Motor_BEV
 SG_ WH_Fehler_Ueberspannung_Status  : 47|1@1+ (1.000000,0.000000) [0.000000|1.000000] "" Motor_BEV
 SG_ WH_Fehler_BZ_SBM  : 48|1@1+ (1.000000,0.000000) [0.000000|1.000000] "" Motor_BEV
 SG_ WH_Fehler_BZ_SBM_Status  : 49|1@1+ (1.000000,0.000000) [0.000000|1.000000] "" Motor_BEV
 SG_ WH_Fehler_Unterspannung  : 50|1@1+ (1.000000,0.000000) [0.000000|1.000000] "" Motor_BEV
 SG_ WH_Fehler_Unterspannung_Status  : 51|1@1+ (1.000000,0.000000) [0.000000|1.000000] "" Motor_BEV
 SG_ WH_Fehler_Ausleuchtung  : 52|1@1+ (1.000000,0.000000) [0.000000|1.000000] "" Motor_BEV
 SG_ WH_Fehler_Ausleuchtung_Status  : 53|1@1+ (1.000000,0.000000) [0.000000|1.000000] "" Motor_BEV
 SG_ WH_Fehler_Entsperrtaste  : 54|1@1+ (1.000000,0.000000) [0.000000|1.000000] "" Motor_BEV
 SG_ WH_Fehler_Entsperrtaste_Status  : 55|1@1+ (1.000000,0.000000) [0.000000|1.000000] "" Motor_BEV
 SG_ WH_Fehler_P_Taste  : 56|1@1+ (1.000000,0.000000) [0.000000|1.000000] "" Motor_BEV
 SG_ WH_Fehler_P_Taste_Status  : 57|1@1+ (1.000000,0.000000) [0.000000|1.000000] "" Motor_BEV
 SG_ WH_Fehler_Sensor_einfach  : 58|1@1+ (1.000000,0.000000) [0.000000|1.000000] "" Motor_BEV
 SG_ WH_Fehler_Sensor_einfach_Status  : 59|1@1+ (1.000000,0.000000) [0.000000|1.000000] "" Motor_BEV
 SG_ WH_Fehler_Sensor_mehrfach  : 60|1@1+ (1.000000,0.000000) [0.000000|1.000000] "" Motor_BEV
 SG_ WH_Fehler_Sensor_mehrfach_Status  : 61|1@1+ (1.000000,0.000000) [0.000000|1.000000] "" Motor_BEV
 SG_ WH_Fehler_Shiftlock  : 62|1@1+ (1.000000,0.000000) [0.000000|1.000000] "" Motor_BEV
 SG_ WH_Fehler_Shiftlock_Status  : 63|1@1+ (1.000000,0.000000) [0.000000|1.000000] "" Motor_BEV

BO_ 916 WBA_03: 8 Motor_BEV
 SG_ WBA_03_CRC  : 0|8@1+ (1.000000,0.000000) [0.000000|255.000000] "" ICAS1_Gateway
 SG_ WBA_03_BZ  : 8|4@1+ (1.000000,0.000000) [0.000000|15.000000] "" ICAS1_Gateway
 SG_ WBA_Fahrstufe_02  : 12|4@1+ (1.000000,0.000000) [0.000000|15.000000] "" ICAS1_Gateway ICAS1_KommunikationsServer
 SG_ WBA_ZielFahrstufe  : 16|4@1+ (1.000000,0.000000) [0.000000|15.000000] "" ICAS1_Gateway
 SG_ WBA_GE_Warnung_02  : 20|4@1+ (1.000000,0.000000) [0.000000|15.000000] "" ICAS1_Gateway
 SG_ WBA_eing_Gang_02  : 24|4@1+ (1.000000,0.000000) [0.000000|15.000000] "" ICAS1_Gateway
 SG_ WBA_GE_Texte  : 28|3@1+ (1.000000,0.000000) [0.000000|7.000000] "" ICAS1_Gateway
 SG_ WBA_Segeln_aktiv  : 31|1@1+ (1.000000,0.000000) [0.000000|1.000000] "" ICAS1_Gateway
 SG_ WBA_Schaltschema_02  : 32|3@1+ (1.000000,0.000000) [0.000000|7.000000] "" ICAS1_Gateway
 SG_ WBA_Schaltschema_FS_inaktiv  : 35|2@1+ (1.000000,0.000000) [0.000000|3.000000] "" ICAS1_Gateway
 SG_ WBA_GE_Zusatzwarnungen  : 37|3@1+ (1.000000,0.000000) [0.000000|7.000000] "" ICAS1_Gateway
 SG_ GE_Sollgang  : 40|4@1+ (1.000000,0.000000) [0.000000|15.000000] "" ICAS1_Gateway
 SG_ GE_Tipschaltempf_verfuegbar  : 44|1@1+ (1.000000,0.000000) [0.000000|1.000000] "" ICAS1_Gateway
 SG_ WBA_GE_Texte_02  : 45|3@1+ (1.000000,0.000000) [0.000000|7.000000] "" ICAS1_Gateway
 SG_ WBA_Schaltschema_Tippgasse  : 48|1@1+ (1.000000,0.000000) [0.000000|1.000000] "" ICAS1_Gateway
 SG_ WBA_Schaltschema_Fahreraktion  : 49|1@1+ (1.000000,0.000000) [0.000000|1.000000] "" ICAS1_Gateway
 SG_ WBA_Schaltschema_FS_vorwaerts  : 50|2@1+ (1.000000,0.000000) [0.000000|3.000000] "" ICAS1_Gateway
 SG_ WBA_Shiftlock_Lampe  : 52|1@1+ (1.000000,0.000000) [0.000000|1.000000] "" ICAS1_Gateway
 SG_ WBA_Anforderung_Akustik  : 53|1@1+ (1.000000,0.000000) [0.000000|1.000000] "" ICAS1_Gateway
 SG_ WBA_Blinken  : 54|1@1+ (1.000000,0.000000) [0.000000|1.000000] "" ICAS1_Gateway
 SG_ GE_Wiederstart_Anz_Std  : 55|1@1+ (1.000000,0.000000) [0.000000|1.000000] "" ICAS1_Gateway
 SG_ GE_Stoppverbot_Anz_01  : 56|1@1+ (1.000000,0.000000) [0.000000|1.000000] "" ICAS1_Gateway
 SG_ GE_Stoppverbot_Anz_02  : 57|1@1+ (1.000000,0.000000) [0.000000|1.000000] "" ICAS1_Gateway
 SG_ GE_Stoppverbot_Anz_03  : 58|1@1+ (1.000000,0.000000) [0.000000|1.000000] "" ICAS1_Gateway
 SG_ GE_Stoppverbot_Anz_04  : 59|1@1+ (1.000000,0.000000) [0.000000|1.000000] "" ICAS1_Gateway
 SG_ GE_Stoppverbot_Anz_05  : 60|1@1+ (1.000000,0.000000) [0.000000|1.000000] "" ICAS1_Gateway
 SG_ GE_Stoppverbot_Anz_06  : 61|1@1+ (1.000000,0.000000) [0.000000|1.000000] "" ICAS1_Gateway
 SG_ GE_Stoppverbot_Anz_07  : 62|1@1+ (1.000000,0.000000) [0.000000|1.000000] "" ICAS1_Gateway
 SG_ GE_Stoppverbot_Anz_Std  : 63|1@1+ (1.000000,0.000000) [0.000000|1.000000] "" ICAS1_Gateway

BO_ 1361 WFS_01: 8 ICAS1_Gateway
 SG_ WFS_Schluessel_Fahrberecht  : 0|4@1+ (1.000000,0.000000) [0.000000|15.000000] "" Vector__XXX
 SG_ WFS_Verbauinfo_ELV  : 4|1@1+ (1.000000,0.000000) [0.000000|1.000000] "" Vector__XXX
 SG_ WFS_ID_Geb_autorisiert  : 5|1@1+ (1.000000,0.000000) [0.000000|1.000000] "" Vector__XXX
 SG_ WFS_ID_Geb_autorisiert_in_Kl15  : 6|1@1+ (1.000000,0.000000) [0.000000|1.000000] "" Vector__XXX
 SG_ WFS_ID_Geb_steckt  : 7|1@1+ (1.000000,0.000000) [0.000000|1.000000] "" Vector__XXX
 SG_ WFS_Schluessel_Soll  : 8|4@1+ (1.000000,0.000000) [0.000000|15.000000] "" Vector__XXX
 SG_ WFS_Schluessel_Ist  : 12|4@1+ (1.000000,0.000000) [0.000000|15.000000] "" Vector__XXX
 SG_ WFS_Safe  : 16|1@1+ (1.000000,0.000000) [0.000000|1.000000] "" Vector__XXX
 SG_ WFS_LZ  : 17|2@1+ (1.000000,0.000000) [0.000000|3.000000] "" Vector__XXX
 SG_ WFS_ELV_authorisiert  : 19|1@1+ (1.000000,0.000000) [0.000000|1.000000] "" Vector__XXX
 SG_ WFS_LF_Aktiv  : 20|1@1+ (1.000000,0.000000) [0.000000|1.000000] "" Vector__XXX
 SG_ WFS_Betrieb_Lesespule  : 21|1@1+ (1.000000,0.000000) [0.000000|1.000000] "" Vector__XXX
 SG_ WFS_Klemmenfreigabe  : 22|1@1+ (1.000000,0.000000) [0.000000|1.000000] "" Motor_BEV
 SG_ WFS_Klemmenfreigabe_Signatur  : 23|11@1+ (1.000000,0.000000) [0.000000|2047.000000] "" Vector__XXX
 SG_ WFS_Fahrerhinweise  : 34|2@1+ (1.000000,0.000000) [0.000000|3.000000] "" Vector__XXX
 SG_ WFS_Parken_Status  : 36|2@1+ (1.000000,0.000000) [0.000000|3.000000] "" Vector__XXX

BO_ 2617028096 XCP_Airbag_CRO_01: 64 Vector__XXX
 SG_ XCP_Airbag_CRO_01_Data  : 0|512@1+ (1.000000,0.000000) [0.000000|13407807929942597099574024998205846127479365820592393377723561443721764030073546976801874298166903427690031858186486050853753882811946569946433649006084096.000000] "" Airbag

BO_ 2617028097 XCP_Airbag_DTO_01: 64 Airbag
 SG_ XCP_Airbag_DTO_01_Data  : 0|512@1+ (1.000000,0.000000) [0.000000|13407807929942597099574024998205846127479365820592393377723561443721764030073546976801874298166903427690031858186486050853753882811946569946433649006084096.000000] "" Vector__XXX

BO_ 2617239040 XCP_EMotor_01_CRO_01: 64 Vector__XXX
 SG_ XCP_EMotor_01_CRO_01_Data  : 0|64@1+ (1.000000,0.000000) [0.000000|18446744073709551616.000000] "" LE1

BO_ 2617239041 XCP_EMotor_01_DTO_01: 64 LE1
 SG_ XCP_EMotor_01_DTO_01_Data  : 0|64@1+ (1.000000,0.000000) [0.000000|18446744073709551616.000000] "" Vector__XXX

BO_ 2617239042 XCP_EMotor_01_DTO_02: 64 LE1
 SG_ XCP_EMotor_01_DTO_02_Data  : 0|64@1+ (1.000000,0.000000) [0.000000|18446744073709551616.000000] "" Vector__XXX

BO_ 2617239043 XCP_EMotor_01_DTO_03: 64 LE1
 SG_ XCP_EMotor_01_DTO_03_Data  : 0|64@1+ (1.000000,0.000000) [0.000000|18446744073709551616.000000] "" Vector__XXX

BO_ 2617239044 XCP_EMotor_01_DTO_04: 64 LE1
 SG_ XCP_EMotor_01_DTO_04_Data  : 0|64@1+ (1.000000,0.000000) [0.000000|18446744073709551616.000000] "" Vector__XXX

BO_ 2617122304 XCP_EMotor_02_CRO_01: 64 Vector__XXX
 SG_ XCP_EMotor_02_CRO_01_Data  : 0|64@1+ (1.000000,0.000000) [0.000000|18446744073709551616.000000] "" LE2

BO_ 2617122305 XCP_EMotor_02_DTO_01: 64 LE2
 SG_ XCP_EMotor_02_DTO_01_Data  : 0|64@1+ (1.000000,0.000000) [0.000000|18446744073709551616.000000] "" Vector__XXX

BO_ 2617122306 XCP_EMotor_02_DTO_02: 64 LE2
 SG_ XCP_EMotor_02_DTO_02_Data  : 0|64@1+ (1.000000,0.000000) [0.000000|18446744073709551616.000000] "" Vector__XXX

BO_ 2617122307 XCP_EMotor_02_DTO_03: 64 LE2
 SG_ XCP_EMotor_02_DTO_03_Data  : 0|64@1+ (1.000000,0.000000) [0.000000|18446744073709551616.000000] "" Vector__XXX

BO_ 2617122308 XCP_EMotor_02_DTO_04: 64 LE2
 SG_ XCP_EMotor_02_DTO_04_Data  : 0|64@1+ (1.000000,0.000000) [0.000000|18446744073709551616.000000] "" Vector__XXX

BO_ 2617226768 XCP_Motor_CRO_01: 64 Vector__XXX
 SG_ XCP_Motor_CRO_01_Data  : 0|64@1+ (1.000000,0.000000) [0.000000|18446744073709551616.000000] "" Motor_BEV

BO_ 2617226769 XCP_Motor_DTO_01: 64 Motor_BEV
 SG_ XCP_Motor_DTO_01_Data  : 0|64@1+ (1.000000,0.000000) [0.000000|18446744073709551616.000000] "" Vector__XXX

BO_ 1411 ZV_02: 8 ICAS1_Gateway
 SG_ ZV_verriegeln_Anf  : 0|1@1+ (1.000000,0.000000) [0.000000|1.000000] "" Vector__XXX
 SG_ ZV_STSG_HFS_Anf  : 1|1@1+ (1.000000,0.000000) [0.000000|1.000000] "" Vector__XXX
 SG_ ZV_STSG_HBFS_Anf  : 2|1@1+ (1.000000,0.000000) [0.000000|1.000000] "" Vector__XXX
 SG_ ZV_Anf_Challenge_Auth  : 3|1@1+ (1.000000,0.000000) [0.000000|1.000000] "" Vector__XXX
 SG_ BCM_FH_Freigabe  : 12|1@1+ (1.000000,0.000000) [0.000000|1.000000] "" Vector__XXX
 SG_ BCM_Komfortfkt_Freigabe  : 13|1@1+ (1.000000,0.000000) [0.000000|1.000000] "" Vector__XXX
 SG_ BCM_HSK_Freigabe  : 14|1@1+ (1.000000,0.000000) [0.000000|1.000000] "" Vector__XXX
 SG_ BCM_Verdeck_Freigabe  : 15|1@1+ (1.000000,0.000000) [0.000000|1.000000] "" Vector__XXX
 SG_ ZV_verriegelt_intern_ist  : 16|1@1+ (1.000000,0.000000) [0.000000|1.000000] "" Vector__XXX
 SG_ ZV_verriegelt_extern_ist  : 17|1@1+ (1.000000,0.000000) [0.000000|1.000000] "" Airbag
 SG_ ZV_verriegelt_intern_soll  : 18|1@1+ (1.000000,0.000000) [0.000000|1.000000] "" Vector__XXX
 SG_ ZV_verriegelt_extern_soll  : 19|1@1+ (1.000000,0.000000) [0.000000|1.000000] "" Airbag
 SG_ ZV_gesafet_extern_ist  : 20|1@1+ (1.000000,0.000000) [0.000000|1.000000] "" Vector__XXX
 SG_ ZV_gesafet_extern_soll  : 21|1@1+ (1.000000,0.000000) [0.000000|1.000000] "" Vector__XXX
 SG_ ZV_Einzeltuerentriegelung  : 22|1@1+ (1.000000,0.000000) [0.000000|1.000000] "" Vector__XXX
 SG_ ZV_Heckeinzelentriegelung  : 23|1@1+ (1.000000,0.000000) [0.000000|1.000000] "" Vector__XXX
 SG_ ZV_FT_offen  : 24|1@1+ (1.000000,0.000000) [0.000000|1.000000] "" Motor_BEV
 SG_ ZV_BT_offen  : 25|1@1+ (1.000000,0.000000) [0.000000|1.000000] "" Motor_BEV
 SG_ ZV_HFS_offen  : 26|1@1+ (1.000000,0.000000) [0.000000|1.000000] "" Motor_BEV
 SG_ ZV_HBFS_offen  : 27|1@1+ (1.000000,0.000000) [0.000000|1.000000] "" Motor_BEV
 SG_ ZV_HD_offen  : 28|1@1+ (1.000000,0.000000) [0.000000|1.000000] "" Motor_BEV
 SG_ ZV_HS_offen  : 29|1@1+ (1.000000,0.000000) [0.000000|1.000000] "" Vector__XXX
 SG_ IRUE_aktiv  : 30|1@1+ (1.000000,0.000000) [0.000000|1.000000] "" Vector__XXX
 SG_ DWA_aktiv  : 31|1@1+ (1.000000,0.000000) [0.000000|1.000000] "" Vector__XXX
 SG_ FFB_HDF_Taste  : 34|1@1+ (1.000000,0.000000) [0.000000|1.000000] "" Vector__XXX
 SG_ FFB_Panik_Taste  : 35|1@1+ (1.000000,0.000000) [0.000000|1.000000] "" Vector__XXX
 SG_ FFB_Auf_Taste  : 36|1@1+ (1.000000,0.000000) [0.000000|1.000000] "" Vector__XXX
 SG_ FFB_Zu_Taste  : 37|1@1+ (1.000000,0.000000) [0.000000|1.000000] "" Vector__XXX
 SG_ FFB_CarFinder  : 38|1@1+ (1.000000,0.000000) [0.000000|1.000000] "" Vector__XXX
 SG_ FFB_Komfortoeffnen  : 39|1@1+ (1.000000,0.000000) [0.000000|1.000000] "" Vector__XXX
 SG_ FFB_Komfortschliessen  : 40|1@1+ (1.000000,0.000000) [0.000000|1.000000] "" Vector__XXX
 SG_ FBS_IDG_in_Reichweite  : 41|1@1+ (1.000000,0.000000) [0.000000|1.000000] "" Vector__XXX
 SG_ ZV_Schluessel_Zugang  : 42|4@1+ (1.000000,0.000000) [0.000000|15.000000] "" Vector__XXX
 SG_ ZV_SafeFunktion_aktiv  : 46|1@1+ (1.000000,0.000000) [0.000000|1.000000] "" Vector__XXX
 SG_ FBS_Warn_Schluessel_Batt  : 47|1@1+ (1.000000,0.000000) [0.000000|1.000000] "" Vector__XXX
 SG_ ZV_Oeffnungsmodus  : 48|2@1+ (1.000000,0.000000) [0.000000|3.000000] "" Vector__XXX
 SG_ ZV_ist_Zustand_verfuegbar  : 54|1@1+ (1.000000,0.000000) [0.000000|1.000000] "" Vector__XXX
 SG_ IRUE_Taster_Fkts_LED  : 55|1@1+ (1.000000,0.000000) [0.000000|1.000000] "" Vector__XXX
 SG_ ZV_Tankklappe_offen  : 56|1@1+ (1.000000,0.000000) [0.000000|1.000000] "" Vector__XXX
 SG_ ZV_Rollo_auf  : 57|1@1+ (1.000000,0.000000) [0.000000|1.000000] "" Vector__XXX
 SG_ ZV_Rollo_zu  : 58|1@1+ (1.000000,0.000000) [0.000000|1.000000] "" Vector__XXX
 SG_ ZV_SAD_auf  : 59|1@1+ (1.000000,0.000000) [0.000000|1.000000] "" Vector__XXX
 SG_ ZV_SAD_zu  : 60|1@1+ (1.000000,0.000000) [0.000000|1.000000] "" Vector__XXX
 SG_ ZV_verriegelt_soll  : 62|2@1+ (1.000000,0.000000) [0.000000|3.000000] "" Vector__XXX

BU_:  Airbag BAP_Tester ICAS1_Gateway ICAS1_KommunikationsServer LE1 LE2 Motor_BEV Schaltbetaetigung

BO_ 2463978663 VZE_04: 32 ICAS1_Gateway
 SG_ VZE_Anzeigemodus  : 0|2@1+ (1.000000,0.000000) [0.000000|3.000000] "" Vector__XXX
 SG_ VZE_Hinweistext  : 2|3@1+ (1.000000,0.000000) [1.000000|7.000000] "" Motor_BEV
 SG_ VZE_Verkehrszeichen_Einheit  : 8|1@1+ (1.000000,0.000000) [0.000000|1.000000] "" Vector__XXX
 SG_ VZE_Anzeigeunterdrueck_Zeichen_3  : 9|1@1+ (1.000000,0.000000) [0.000000|1.000000] "" Vector__XXX
 SG_ VZE_Anzeigeunterdrueck_Zeichen_2  : 10|1@1+ (1.000000,0.000000) [0.000000|1.000000] "" Vector__XXX
 SG_ VZE_Verkehrszeichen_1  : 11|8@1+ (1.000000,0.000000) [1.000000|255.000000] "" Motor_BEV
 SG_ VZE_Verkehrszeichen_2  : 19|8@1+ (1.000000,0.000000) [1.000000|255.000000] "" Vector__XXX
 SG_ VZE_Verkehrszeichen_3  : 27|8@1+ (1.000000,0.000000) [1.000000|255.000000] "" Vector__XXX
 SG_ VZE_Warnung_Verkehrszeichen_1  : 35|1@1+ (1.000000,0.000000) [0.000000|1.000000] "" Vector__XXX
 SG_ VZE_Warnung_Verkehrszeichen_2  : 36|1@1+ (1.000000,0.000000) [0.000000|1.000000] "" Vector__XXX
 SG_ VZE_Warnung_Verkehrszeichen_3  : 37|1@1+ (1.000000,0.000000) [0.000000|1.000000] "" Vector__XXX
 SG_ VZE_Zusatzschild_1  : 38|4@1+ (1.000000,0.000000) [1.000000|15.000000] "" Vector__XXX
 SG_ VZE_Zusatzschild_2  : 42|4@1+ (1.000000,0.000000) [1.000000|15.000000] "" Vector__XXX
 SG_ VZE_Zusatzschild_3  : 46|4@1+ (1.000000,0.000000) [1.000000|15.000000] "" Vector__XXX
 SG_ VZE_Anzeigeunterdrueck_Zeichen_1  : 50|1@1+ (1.000000,0.000000) [0.000000|1.000000] "" Vector__XXX
 SG_ VZE_Zeichen_01_KameraWied  : 51|1@1+ (1.000000,0.000000) [0.000000|1.000000] "" Motor_BEV
 SG_ VZE_Zeichen_02_KameraWied  : 52|1@1+ (1.000000,0.000000) [0.000000|1.000000] "" Vector__XXX
 SG_ VZE_Zeichen_03_KameraWied  : 53|1@1+ (1.000000,0.000000) [0.000000|1.000000] "" Vector__XXX
 SG_ VZE_Zeichen_01_Kamera  : 54|1@1+ (1.000000,0.000000) [0.000000|1.000000] "" Motor_BEV
 SG_ VZE_Zeichen_01_Karte  : 55|1@1+ (1.000000,0.000000) [0.000000|1.000000] "" Vector__XXX
 SG_ VZE_Zeichen_01_Gesetz  : 56|1@1+ (1.000000,0.000000) [0.000000|1.000000] "" Vector__XXX
 SG_ VZE_Zeichen_02_Kamera  : 57|1@1+ (1.000000,0.000000) [0.000000|1.000000] "" Vector__XXX
 SG_ VZE_Zeichen_02_Karte  : 58|1@1+ (1.000000,0.000000) [0.000000|1.000000] "" Vector__XXX
 SG_ VZE_Zeichen_02_Gesetz  : 59|1@1+ (1.000000,0.000000) [0.000000|1.000000] "" Vector__XXX
 SG_ VZE_Zeichen_03_Kamera  : 60|1@1+ (1.000000,0.000000) [0.000000|1.000000] "" Vector__XXX
 SG_ VZE_Zeichen_03_Karte  : 61|1@1+ (1.000000,0.000000) [0.000000|1.000000] "" Vector__XXX
 SG_ VZE_Zeichen_03_Gesetz  : 62|1@1+ (1.000000,0.000000) [0.000000|1.000000] "" Vector__XXX
 SG_ VZE_Gong  : 63|1@1+ (1.000000,0.000000) [0.000000|1.000000] "" Vector__XXX
 SG_ VZE_Anzeigeunterdrueck_Zeichen_5  : 72|1@1+ (1.000000,0.000000) [0.000000|1.000000] "" Vector__XXX
 SG_ VZE_Zeichen_05_KameraWied  : 73|1@1+ (1.000000,0.000000) [0.000000|1.000000] "" Vector__XXX
 SG_ VZE_Zeichen_05_Kamera  : 74|1@1+ (1.000000,0.000000) [0.000000|1.000000] "" Vector__XXX
 SG_ VZE_Verkehrszeichen_4  : 75|8@1+ (1.000000,0.000000) [1.000000|255.000000] "" Motor_BEV
 SG_ VZE_Verkehrszeichen_5  : 83|8@1+ (1.000000,0.000000) [1.000000|255.000000] "" Motor_BEV
 SG_ VZE_Anhaenger_Vmax  : 91|4@1+ (10.000000,10.000000) [10.000000|140.000000] "Unit_KiloMeterPerHour" Vector__XXX
 SG_ VZE_Zeichen_04_Gesetz  : 95|1@1+ (1.000000,0.000000) [0.000000|1.000000] "" Vector__XXX
 SG_ VZE_Zeichen_04_Kamera  : 96|1@1+ (1.000000,0.000000) [0.000000|1.000000] "" Vector__XXX
 SG_ VZE_Zeichen_04_KameraWied  : 97|1@1+ (1.000000,0.000000) [0.000000|1.000000] "" Vector__XXX
 SG_ VZE_Zeichen_04_Karte  : 98|1@1+ (1.000000,0.000000) [0.000000|1.000000] "" Vector__XXX
 SG_ VZE_Warnung_Verkehrszeichen_4  : 99|1@1+ (1.000000,0.000000) [0.000000|1.000000] "" Vector__XXX
 SG_ VZE_Warnung_Verkehrszeichen_5  : 100|1@1+ (1.000000,0.000000) [0.000000|1.000000] "" Vector__XXX
 SG_ VZE_Zeichen_05_Gesetz  : 101|1@1+ (1.000000,0.000000) [0.000000|1.000000] "" Vector__XXX
 SG_ VZE_Zusatzschild_4  : 102|4@1+ (1.000000,0.000000) [1.000000|15.000000] "" Vector__XXX
 SG_ VZE_Zusatzschild_5  : 106|4@1+ (1.000000,0.000000) [1.000000|15.000000] "" Vector__XXX
 SG_ VZE_Baustelle  : 110|2@1+ (1.000000,0.000000) [0.000000|3.000000] "" Vector__XXX
 SG_ VZE_Zeichen_05_Karte  : 112|1@1+ (1.000000,0.000000) [0.000000|1.000000] "" Vector__XXX
 SG_ VZE_Zeichen_05_Entfernung  : 113|7@1+ (1.000000,0.000000) [1.000000|127.000000] "Unit_Meter" Motor_BEV
 SG_ VZE_Zeichen_05_Entfernung_StdA  : 120|7@1+ (1.000000,0.000000) [1.000000|127.000000] "Unit_Meter" Motor_BEV
 SG_ VZE_Anzeigeunterdrueck_Zeichen_4  : 127|1@1+ (1.000000,0.000000) [0.000000|1.000000] "" Vector__XXX
 SG_ VZE_Verkehrszeichen_6  : 128|8@1+ (1.000000,0.000000) [1.000000|255.000000] "Unit_None" Motor_BEV
 SG_ VZE_Zusatzschild_6  : 136|4@1+ (1.000000,0.000000) [1.000000|15.000000] "" Vector__XXX
 SG_ VZE_Zeichen_06_Entfernung  : 140|7@1+ (1.000000,0.000000) [1.000000|127.000000] "Unit_Meter" Motor_BEV
 SG_ VZE_Zeichen_06_Entfernung_StdA  : 147|7@1+ (1.000000,0.000000) [1.000000|127.000000] "Unit_Meter" Motor_BEV
 SG_ VZE_Umweltinfo_Naesse  : 154|1@1+ (1.000000,0.000000) [0.000000|1.000000] "" Motor_BEV
 SG_ VZE_Umweltinfo_Nebel  : 155|1@1+ (1.000000,0.000000) [0.000000|1.000000] "" Motor_BEV
 SG_ VZE_Umweltinfo_Anhaengerbetrieb  : 156|1@1+ (1.000000,0.000000) [0.000000|1.000000] "" Vector__XXX
 SG_ VZE_Erweiterte_Information  : 157|8@1+ (1.000000,0.000000) [1.000000|255.000000] "Unit_None" Vector__XXX
 SG_ VZE_Tempowarnung_Status  : 165|1@1+ (1.000000,0.000000) [0.000000|1.000000] "" Vector__XXX
 SG_ VZE_Tempowarnung_Einheit  : 166|1@1+ (1.000000,0.000000) [0.000000|1.000000] "" Vector__XXX
 SG_ VZE_Tempowarnung_Offset  : 167|5@1+ (1.000000,0.000000) [1.000000|31.000000] "" Vector__XXX
 SG_ VZE_FoD_Status  : 206|2@1+ (1.000000,0.000000) [0.000000|3.000000] "" Vector__XXX
 SG_ VZE_Anzeige_ZS_1  : 208|4@1+ (1.000000,0.000000) [1.000000|15.000000] "Unit_None" Vector__XXX
 SG_ VZE_Anzeige_ZS_2  : 212|4@1+ (1.000000,0.000000) [1.000000|15.000000] "Unit_None" Vector__XXX
 SG_ VZE_Anzeige_ZS_3  : 216|4@1+ (1.000000,0.000000) [1.000000|15.000000] "Unit_None" Vector__XXX
 SG_ VZE_Hinweistext_03  : 220|4@1+ (1.000000,0.000000) [1.000000|15.000000] "" Vector__XXX
 SG_ VZE_Land  : 224|5@1+ (1.000000,0.000000) [1.000000|31.000000] "" Vector__XXX
 SG_ VZE_Warnung_VZ_1  : 229|1@1+ (1.000000,0.000000) [0.000000|1.000000] "" Vector__XXX
 SG_ VZE_Warnung_VZ_2  : 230|1@1+ (1.000000,0.000000) [0.000000|1.000000] "" Vector__XXX
 SG_ VZE_Warnung_VZ_3  : 231|1@1+ (1.000000,0.000000) [0.000000|1.000000] "" Vector__XXX
 SG_ VZE_Anzeige_VZ_1  : 232|8@1+ (1.000000,0.000000) [1.000000|255.000000] "" Vector__XXX
 SG_ VZE_Anzeige_VZ_2  : 240|8@1+ (1.000000,0.000000) [1.000000|255.000000] "Unit_None" Vector__XXX
 SG_ VZE_Anzeige_VZ_3  : 248|8@1+ (1.000000,0.000000) [1.000000|255.000000] "Unit_None" Vector__XXX

BO_ 181 Waehlhebel_04: 8 ICAS1_Gateway
 SG_ Waehlhebel_04_CRC  : 0|8@1+ (1.000000,0.000000) [0.000000|255.000000] "" Motor_BEV
 SG_ Waehlhebel_04_BZ  : 8|4@1+ (1.000000,0.000000) [0.000000|15.000000] "" Motor_BEV
 SG_ WH_gespeicherte_Fahrstufe  : 12|3@1+ (1.000000,0.000000) [0.000000|7.000000] "" Vector__XXX
 SG_ WH_Initialisierung  : 15|1@1+ (1.000000,0.000000) [0.000000|1.000000] "" Motor_BEV
 SG_ WH_SensorPos_roh  : 16|4@1+ (1.000000,0.000000) [0.000000|15.000000] "" Motor_BEV
 SG_ WH_SensorPos_roh_inv  : 20|4@1+ (1.000000,0.000000) [0.000000|15.000000] "" Motor_BEV
 SG_ WH_Testergebnis  : 24|8@1+ (1.000000,0.000000) [0.000000|255.000000] "" Vector__XXX
 SG_ WH_Test_Aktiv  : 32|1@1+ (1.000000,0.000000) [0.000000|1.000000] "" Vector__XXX
 SG_ WH_Ist_Haltemagnet  : 33|2@1+ (1.000000,0.000000) [0.000000|3.000000] "" Motor_BEV
 SG_ WH_Variante  : 35|4@1+ (1.000000,0.000000) [0.000000|15.000000] "" Motor_BEV
 SG_ WH_Entsperrtaste_02  : 39|2@1+ (1.000000,0.000000) [0.000000|3.000000] "" Motor_BEV
 SG_ WH_P_Taste  : 41|2@1+ (1.000000,0.000000) [0.000000|3.000000] "" Motor_BEV
 SG_ WH_Ende_N_Haltephase  : 43|1@1+ (1.000000,0.000000) [0.000000|1.000000] "" Vector__XXX
 SG_ WH_Fahrstufe  : 44|4@1+ (1.000000,0.000000) [0.000000|15.000000] "" Motor_BEV
 SG_ WH_Status_Shiftlock  : 48|3@1+ (1.000000,0.000000) [0.000000|7.000000] "" Motor_BEV
 SG_ WH_Zustand_N_Haltephase  : 51|2@1+ (1.000000,0.000000) [0.000000|3.000000] "" Vector__XXX

BO_ 2463978687 Waehlhebel_06: 8 ICAS1_Gateway
 SG_ WH_Fehler_Haltemagnet_Status  : 41|1@1+ (1.000000,0.000000) [0.000000|1.000000] "" Motor_BEV
 SG_ WH_Fehler_CRC_SBM  : 42|1@1+ (1.000000,0.000000) [0.000000|1.000000] "" Motor_BEV
 SG_ WH_Fehler_CRC_SBM_Status  : 43|1@1+ (1.000000,0.000000) [0.000000|1.000000] "" Motor_BEV
 SG_ WH_Fehler_Timeout_SBM  : 44|1@1+ (1.000000,0.000000) [0.000000|1.000000] "" Motor_BEV
 SG_ WH_Fehler_Timeout_SBM_Status  : 45|1@1+ (1.000000,0.000000) [0.000000|1.000000] "" Motor_BEV
 SG_ WH_Fehler_Ueberspannung  : 46|1@1+ (1.000000,0.000000) [0.000000|1.000000] "" Motor_BEV
 SG_ WH_Fehler_Ueberspannung_Status  : 47|1@1+ (1.000000,0.000000) [0.000000|1.000000] "" Motor_BEV
 SG_ WH_Fehler_BZ_SBM  : 48|1@1+ (1.000000,0.000000) [0.000000|1.000000] "" Motor_BEV
 SG_ WH_Fehler_BZ_SBM_Status  : 49|1@1+ (1.000000,0.000000) [0.000000|1.000000] "" Motor_BEV
 SG_ WH_Fehler_Unterspannung  : 50|1@1+ (1.000000,0.000000) [0.000000|1.000000] "" Motor_BEV
 SG_ WH_Fehler_Unterspannung_Status  : 51|1@1+ (1.000000,0.000000) [0.000000|1.000000] "" Motor_BEV
 SG_ WH_Fehler_Ausleuchtung  : 52|1@1+ (1.000000,0.000000) [0.000000|1.000000] "" Motor_BEV
 SG_ WH_Fehler_Ausleuchtung_Status  : 53|1@1+ (1.000000,0.000000) [0.000000|1.000000] "" Motor_BEV
 SG_ WH_Fehler_Entsperrtaste  : 54|1@1+ (1.000000,0.000000) [0.000000|1.000000] "" Motor_BEV
 SG_ WH_Fehler_Entsperrtaste_Status  : 55|1@1+ (1.000000,0.000000) [0.000000|1.000000] "" Motor_BEV
 SG_ WH_Fehler_P_Taste  : 56|1@1+ (1.000000,0.000000) [0.000000|1.000000] "" Motor_BEV
 SG_ WH_Fehler_P_Taste_Status  : 57|1@1+ (1.000000,0.000000) [0.000000|1.000000] "" Motor_BEV
 SG_ WH_Fehler_Sensor_einfach  : 58|1@1+ (1.000000,0.000000) [0.000000|1.000000] "" Motor_BEV
 SG_ WH_Fehler_Sensor_einfach_Status  : 59|1@1+ (1.000000,0.000000) [0.000000|1.000000] "" Motor_BEV
 SG_ WH_Fehler_Sensor_mehrfach  : 60|1@1+ (1.000000,0.000000) [0.000000|1.000000] "" Motor_BEV
 SG_ WH_Fehler_Sensor_mehrfach_Status  : 61|1@1+ (1.000000,0.000000) [0.000000|1.000000] "" Motor_BEV
 SG_ WH_Fehler_Shiftlock  : 62|1@1+ (1.000000,0.000000) [0.000000|1.000000] "" Motor_BEV
 SG_ WH_Fehler_Shiftlock_Status  : 63|1@1+ (1.000000,0.000000) [0.000000|1.000000] "" Motor_BEV

BO_ 916 WBA_03: 8 Motor_BEV
 SG_ WBA_03_CRC  : 0|8@1+ (1.000000,0.000000) [0.000000|255.000000] "" ICAS1_Gateway
 SG_ WBA_03_BZ  : 8|4@1+ (1.000000,0.000000) [0.000000|15.000000] "" ICAS1_Gateway
 SG_ WBA_Fahrstufe_02  : 12|4@1+ (1.000000,0.000000) [0.000000|15.000000] "" ICAS1_Gateway ICAS1_KommunikationsServer
 SG_ WBA_ZielFahrstufe  : 16|4@1+ (1.000000,0.000000) [0.000000|15.000000] "" ICAS1_Gateway
 SG_ WBA_GE_Warnung_02  : 20|4@1+ (1.000000,0.000000) [0.000000|15.000000] "" ICAS1_Gateway
 SG_ WBA_eing_Gang_02  : 24|4@1+ (1.000000,0.000000) [0.000000|15.000000] "" ICAS1_Gateway
 SG_ WBA_GE_Texte  : 28|3@1+ (1.000000,0.000000) [0.000000|7.000000] "" ICAS1_Gateway
 SG_ WBA_Segeln_aktiv  : 31|1@1+ (1.000000,0.000000) [0.000000|1.000000] "" ICAS1_Gateway
 SG_ WBA_Schaltschema_02  : 32|3@1+ (1.000000,0.000000) [0.000000|7.000000] "" ICAS1_Gateway
 SG_ WBA_Schaltschema_FS_inaktiv  : 35|2@1+ (1.000000,0.000000) [0.000000|3.000000] "" ICAS1_Gateway
 SG_ WBA_GE_Zusatzwarnungen  : 37|3@1+ (1.000000,0.000000) [0.000000|7.000000] "" ICAS1_Gateway
 SG_ GE_Sollgang  : 40|4@1+ (1.000000,0.000000) [0.000000|15.000000] "" ICAS1_Gateway
 SG_ GE_Tipschaltempf_verfuegbar  : 44|1@1+ (1.000000,0.000000) [0.000000|1.000000] "" ICAS1_Gateway
 SG_ WBA_GE_Texte_02  : 45|3@1+ (1.000000,0.000000) [0.000000|7.000000] "" ICAS1_Gateway
 SG_ WBA_Schaltschema_Tippgasse  : 48|1@1+ (1.000000,0.000000) [0.000000|1.000000] "" ICAS1_Gateway
 SG_ WBA_Schaltschema_Fahreraktion  : 49|1@1+ (1.000000,0.000000) [0.000000|1.000000] "" ICAS1_Gateway
 SG_ WBA_Schaltschema_FS_vorwaerts  : 50|2@1+ (1.000000,0.000000) [0.000000|3.000000] "" ICAS1_Gateway
 SG_ WBA_Shiftlock_Lampe  : 52|1@1+ (1.000000,0.000000) [0.000000|1.000000] "" ICAS1_Gateway
 SG_ WBA_Anforderung_Akustik  : 53|1@1+ (1.000000,0.000000) [0.000000|1.000000] "" ICAS1_Gateway
 SG_ WBA_Blinken  : 54|1@1+ (1.000000,0.000000) [0.000000|1.000000] "" ICAS1_Gateway
 SG_ GE_Wiederstart_Anz_Std  : 55|1@1+ (1.000000,0.000000) [0.000000|1.000000] "" ICAS1_Gateway
 SG_ GE_Stoppverbot_Anz_01  : 56|1@1+ (1.000000,0.000000) [0.000000|1.000000] "" ICAS1_Gateway
 SG_ GE_Stoppverbot_Anz_02  : 57|1@1+ (1.000000,0.000000) [0.000000|1.000000] "" ICAS1_Gateway
 SG_ GE_Stoppverbot_Anz_03  : 58|1@1+ (1.000000,0.000000) [0.000000|1.000000] "" ICAS1_Gateway
 SG_ GE_Stoppverbot_Anz_04  : 59|1@1+ (1.000000,0.000000) [0.000000|1.000000] "" ICAS1_Gateway
 SG_ GE_Stoppverbot_Anz_05  : 60|1@1+ (1.000000,0.000000) [0.000000|1.000000] "" ICAS1_Gateway
 SG_ GE_Stoppverbot_Anz_06  : 61|1@1+ (1.000000,0.000000) [0.000000|1.000000] "" ICAS1_Gateway
 SG_ GE_Stoppverbot_Anz_07  : 62|1@1+ (1.000000,0.000000) [0.000000|1.000000] "" ICAS1_Gateway
 SG_ GE_Stoppverbot_Anz_Std  : 63|1@1+ (1.000000,0.000000) [0.000000|1.000000] "" ICAS1_Gateway

BO_ 1361 WFS_01: 8 ICAS1_Gateway
 SG_ WFS_Schluessel_Fahrberecht  : 0|4@1+ (1.000000,0.000000) [0.000000|15.000000] "" Vector__XXX
 SG_ WFS_Verbauinfo_ELV  : 4|1@1+ (1.000000,0.000000) [0.000000|1.000000] "" Vector__XXX
 SG_ WFS_ID_Geb_autorisiert  : 5|1@1+ (1.000000,0.000000) [0.000000|1.000000] "" Vector__XXX
 SG_ WFS_ID_Geb_autorisiert_in_Kl15  : 6|1@1+ (1.000000,0.000000) [0.000000|1.000000] "" Vector__XXX
 SG_ WFS_ID_Geb_steckt  : 7|1@1+ (1.000000,0.000000) [0.000000|1.000000] "" Vector__XXX
 SG_ WFS_Schluessel_Soll  : 8|4@1+ (1.000000,0.000000) [0.000000|15.000000] "" Vector__XXX
 SG_ WFS_Schluessel_Ist  : 12|4@1+ (1.000000,0.000000) [0.000000|15.000000] "" Vector__XXX
 SG_ WFS_Safe  : 16|1@1+ (1.000000,0.000000) [0.000000|1.000000] "" Vector__XXX
 SG_ WFS_LZ  : 17|2@1+ (1.000000,0.000000) [0.000000|3.000000] "" Vector__XXX
 SG_ WFS_ELV_authorisiert  : 19|1@1+ (1.000000,0.000000) [0.000000|1.000000] "" Vector__XXX
 SG_ WFS_LF_Aktiv  : 20|1@1+ (1.000000,0.000000) [0.000000|1.000000] "" Vector__XXX
 SG_ WFS_Betrieb_Lesespule  : 21|1@1+ (1.000000,0.000000) [0.000000|1.000000] "" Vector__XXX
 SG_ WFS_Klemmenfreigabe  : 22|1@1+ (1.000000,0.000000) [0.000000|1.000000] "" Motor_BEV
 SG_ WFS_Klemmenfreigabe_Signatur  : 23|11@1+ (1.000000,0.000000) [0.000000|2047.000000] "" Vector__XXX
 SG_ WFS_Fahrerhinweise  : 34|2@1+ (1.000000,0.000000) [0.000000|3.000000] "" Vector__XXX
 SG_ WFS_Parken_Status  : 36|2@1+ (1.000000,0.000000) [0.000000|3.000000] "" Vector__XXX

BO_ 2617028096 XCP_Airbag_CRO_01: 64 Vector__XXX
 SG_ XCP_Airbag_CRO_01_Data  : 0|512@1+ (1.000000,0.000000) [0.000000|13407807929942597099574024998205846127479365820592393377723561443721764030073546976801874298166903427690031858186486050853753882811946569946433649006084096.000000] "" Airbag

BO_ 2617028097 XCP_Airbag_DTO_01: 64 Airbag
 SG_ XCP_Airbag_DTO_01_Data  : 0|512@1+ (1.000000,0.000000) [0.000000|13407807929942597099574024998205846127479365820592393377723561443721764030073546976801874298166903427690031858186486050853753882811946569946433649006084096.000000] "" Vector__XXX

BO_ 2617239040 XCP_EMotor_01_CRO_01: 64 Vector__XXX
 SG_ XCP_EMotor_01_CRO_01_Data  : 0|64@1+ (1.000000,0.000000) [0.000000|18446744073709551616.000000] "" LE1

BO_ 2617239041 XCP_EMotor_01_DTO_01: 64 LE1
 SG_ XCP_EMotor_01_DTO_01_Data  : 0|64@1+ (1.000000,0.000000) [0.000000|18446744073709551616.000000] "" Vector__XXX

BO_ 2617239042 XCP_EMotor_01_DTO_02: 64 LE1
 SG_ XCP_EMotor_01_DTO_02_Data  : 0|64@1+ (1.000000,0.000000) [0.000000|18446744073709551616.000000] "" Vector__XXX

BO_ 2617239043 XCP_EMotor_01_DTO_03: 64 LE1
 SG_ XCP_EMotor_01_DTO_03_Data  : 0|64@1+ (1.000000,0.000000) [0.000000|18446744073709551616.000000] "" Vector__XXX

BO_ 2617239044 XCP_EMotor_01_DTO_04: 64 LE1
 SG_ XCP_EMotor_01_DTO_04_Data  : 0|64@1+ (1.000000,0.000000) [0.000000|18446744073709551616.000000] "" Vector__XXX

BO_ 2617122304 XCP_EMotor_02_CRO_01: 64 Vector__XXX
 SG_ XCP_EMotor_02_CRO_01_Data  : 0|64@1+ (1.000000,0.000000) [0.000000|18446744073709551616.000000] "" LE2

BO_ 2617122305 XCP_EMotor_02_DTO_01: 64 LE2
 SG_ XCP_EMotor_02_DTO_01_Data  : 0|64@1+ (1.000000,0.000000) [0.000000|18446744073709551616.000000] "" Vector__XXX

BO_ 2617122306 XCP_EMotor_02_DTO_02: 64 LE2
 SG_ XCP_EMotor_02_DTO_02_Data  : 0|64@1+ (1.000000,0.000000) [0.000000|18446744073709551616.000000] "" Vector__XXX

BO_ 2617122307 XCP_EMotor_02_DTO_03: 64 LE2
 SG_ XCP_EMotor_02_DTO_03_Data  : 0|64@1+ (1.000000,0.000000) [0.000000|18446744073709551616.000000] "" Vector__XXX

BO_ 2617122308 XCP_EMotor_02_DTO_04: 64 LE2
 SG_ XCP_EMotor_02_DTO_04_Data  : 0|64@1+ (1.000000,0.000000) [0.000000|18446744073709551616.000000] "" Vector__XXX

BO_ 2617226768 XCP_Motor_CRO_01: 64 Vector__XXX
 SG_ XCP_Motor_CRO_01_Data  : 0|64@1+ (1.000000,0.000000) [0.000000|18446744073709551616.000000] "" Motor_BEV

BO_ 2617226769 XCP_Motor_DTO_01: 64 Motor_BEV
 SG_ XCP_Motor_DTO_01_Data  : 0|64@1+ (1.000000,0.000000) [0.000000|18446744073709551616.000000] "" Vector__XXX

BO_ 1411 ZV_02: 8 ICAS1_Gateway
 SG_ ZV_verriegeln_Anf  : 0|1@1+ (1.000000,0.000000) [0.000000|1.000000] "" Vector__XXX
 SG_ ZV_STSG_HFS_Anf  : 1|1@1+ (1.000000,0.000000) [0.000000|1.000000] "" Vector__XXX
 SG_ ZV_STSG_HBFS_Anf  : 2|1@1+ (1.000000,0.000000) [0.000000|1.000000] "" Vector__XXX
 SG_ ZV_Anf_Challenge_Auth  : 3|1@1+ (1.000000,0.000000) [0.000000|1.000000] "" Vector__XXX
 SG_ BCM_FH_Freigabe  : 12|1@1+ (1.000000,0.000000) [0.000000|1.000000] "" Vector__XXX
 SG_ BCM_Komfortfkt_Freigabe  : 13|1@1+ (1.000000,0.000000) [0.000000|1.000000] "" Vector__XXX
 SG_ BCM_HSK_Freigabe  : 14|1@1+ (1.000000,0.000000) [0.000000|1.000000] "" Vector__XXX
 SG_ BCM_Verdeck_Freigabe  : 15|1@1+ (1.000000,0.000000) [0.000000|1.000000] "" Vector__XXX
 SG_ ZV_verriegelt_intern_ist  : 16|1@1+ (1.000000,0.000000) [0.000000|1.000000] "" Vector__XXX
 SG_ ZV_verriegelt_extern_ist  : 17|1@1+ (1.000000,0.000000) [0.000000|1.000000] "" Airbag
 SG_ ZV_verriegelt_intern_soll  : 18|1@1+ (1.000000,0.000000) [0.000000|1.000000] "" Vector__XXX
 SG_ ZV_verriegelt_extern_soll  : 19|1@1+ (1.000000,0.000000) [0.000000|1.000000] "" Airbag
 SG_ ZV_gesafet_extern_ist  : 20|1@1+ (1.000000,0.000000) [0.000000|1.000000] "" Vector__XXX
 SG_ ZV_gesafet_extern_soll  : 21|1@1+ (1.000000,0.000000) [0.000000|1.000000] "" Vector__XXX
 SG_ ZV_Einzeltuerentriegelung  : 22|1@1+ (1.000000,0.000000) [0.000000|1.000000] "" Vector__XXX
 SG_ ZV_Heckeinzelentriegelung  : 23|1@1+ (1.000000,0.000000) [0.000000|1.000000] "" Vector__XXX
 SG_ ZV_FT_offen  : 24|1@1+ (1.000000,0.000000) [0.000000|1.000000] "" Motor_BEV
 SG_ ZV_BT_offen  : 25|1@1+ (1.000000,0.000000) [0.000000|1.000000] "" Motor_BEV
 SG_ ZV_HFS_offen  : 26|1@1+ (1.000000,0.000000) [0.000000|1.000000] "" Motor_BEV
 SG_ ZV_HBFS_offen  : 27|1@1+ (1.000000,0.000000) [0.000000|1.000000] "" Motor_BEV
 SG_ ZV_HD_offen  : 28|1@1+ (1.000000,0.000000) [0.000000|1.000000] "" Motor_BEV
 SG_ ZV_HS_offen  : 29|1@1+ (1.000000,0.000000) [0.000000|1.000000] "" Vector__XXX
 SG_ IRUE_aktiv  : 30|1@1+ (1.000000,0.000000) [0.000000|1.000000] "" Vector__XXX
 SG_ DWA_aktiv  : 31|1@1+ (1.000000,0.000000) [0.000000|1.000000] "" Vector__XXX
 SG_ FFB_HDF_Taste  : 34|1@1+ (1.000000,0.000000) [0.000000|1.000000] "" Vector__XXX
 SG_ FFB_Panik_Taste  : 35|1@1+ (1.000000,0.000000) [0.000000|1.000000] "" Vector__XXX
 SG_ FFB_Auf_Taste  : 36|1@1+ (1.000000,0.000000) [0.000000|1.000000] "" Vector__XXX
 SG_ FFB_Zu_Taste  : 37|1@1+ (1.000000,0.000000) [0.000000|1.000000] "" Vector__XXX
 SG_ FFB_CarFinder  : 38|1@1+ (1.000000,0.000000) [0.000000|1.000000] "" Vector__XXX
 SG_ FFB_Komfortoeffnen  : 39|1@1+ (1.000000,0.000000) [0.000000|1.000000] "" Vector__XXX
 SG_ FFB_Komfortschliessen  : 40|1@1+ (1.000000,0.000000) [0.000000|1.000000] "" Vector__XXX
 SG_ FBS_IDG_in_Reichweite  : 41|1@1+ (1.000000,0.000000) [0.000000|1.000000] "" Vector__XXX
 SG_ ZV_Schluessel_Zugang  : 42|4@1+ (1.000000,0.000000) [0.000000|15.000000] "" Vector__XXX
 SG_ ZV_SafeFunktion_aktiv  : 46|1@1+ (1.000000,0.000000) [0.000000|1.000000] "" Vector__XXX
 SG_ FBS_Warn_Schluessel_Batt  : 47|1@1+ (1.000000,0.000000) [0.000000|1.000000] "" Vector__XXX
 SG_ ZV_Oeffnungsmodus  : 48|2@1+ (1.000000,0.000000) [0.000000|3.000000] "" Vector__XXX
 SG_ ZV_ist_Zustand_verfuegbar  : 54|1@1+ (1.000000,0.000000) [0.000000|1.000000] "" Vector__XXX
 SG_ IRUE_Taster_Fkts_LED  : 55|1@1+ (1.000000,0.000000) [0.000000|1.000000] "" Vector__XXX
 SG_ ZV_Tankklappe_offen  : 56|1@1+ (1.000000,0.000000) [0.000000|1.000000] "" Vector__XXX
 SG_ ZV_Rollo_auf  : 57|1@1+ (1.000000,0.000000) [0.000000|1.000000] "" Vector__XXX
 SG_ ZV_Rollo_zu  : 58|1@1+ (1.000000,0.000000) [0.000000|1.000000] "" Vector__XXX
 SG_ ZV_SAD_auf  : 59|1@1+ (1.000000,0.000000) [0.000000|1.000000] "" Vector__XXX
 SG_ ZV_SAD_zu  : 60|1@1+ (1.000000,0.000000) [0.000000|1.000000] "" Vector__XXX
 SG_ ZV_verriegelt_soll  : 62|2@1+ (1.000000,0.000000) [0.000000|3.000000] "" Vector__XXX

BU_:  Airbag BAP_Tester ICAS1_Gateway ICAS1_KommunikationsServer LE1 LE2 Motor_BEV Schaltbetaetigung

BO_ 2463978663 VZE_04: 32 ICAS1_Gateway
 SG_ VZE_Anzeigemodus  : 0|2@1+ (1.000000,0.000000) [0.000000|3.000000] "" Vector__XXX
 SG_ VZE_Hinweistext  : 2|3@1+ (1.000000,0.000000) [1.000000|7.000000] "" Motor_BEV
 SG_ VZE_Verkehrszeichen_Einheit  : 8|1@1+ (1.000000,0.000000) [0.000000|1.000000] "" Vector__XXX
 SG_ VZE_Anzeigeunterdrueck_Zeichen_3  : 9|1@1+ (1.000000,0.000000) [0.000000|1.000000] "" Vector__XXX
 SG_ VZE_Anzeigeunterdrueck_Zeichen_2  : 10|1@1+ (1.000000,0.000000) [0.000000|1.000000] "" Vector__XXX
 SG_ VZE_Verkehrszeichen_1  : 11|8@1+ (1.000000,0.000000) [1.000000|255.000000] "" Motor_BEV
 SG_ VZE_Verkehrszeichen_2  : 19|8@1+ (1.000000,0.000000) [1.000000|255.000000] "" Vector__XXX
 SG_ VZE_Verkehrszeichen_3  : 27|8@1+ (1.000000,0.000000) [1.000000|255.000000] "" Vector__XXX
 SG_ VZE_Warnung_Verkehrszeichen_1  : 35|1@1+ (1.000000,0.000000) [0.000000|1.000000] "" Vector__XXX
 SG_ VZE_Warnung_Verkehrszeichen_2  : 36|1@1+ (1.000000,0.000000) [0.000000|1.000000] "" Vector__XXX
 SG_ VZE_Warnung_Verkehrszeichen_3  : 37|1@1+ (1.000000,0.000000) [0.000000|1.000000] "" Vector__XXX
 SG_ VZE_Zusatzschild_1  : 38|4@1+ (1.000000,0.000000) [1.000000|15.000000] "" Vector__XXX
 SG_ VZE_Zusatzschild_2  : 42|4@1+ (1.000000,0.000000) [1.000000|15.000000] "" Vector__XXX
 SG_ VZE_Zusatzschild_3  : 46|4@1+ (1.000000,0.000000) [1.000000|15.000000] "" Vector__XXX
 SG_ VZE_Anzeigeunterdrueck_Zeichen_1  : 50|1@1+ (1.000000,0.000000) [0.000000|1.000000] "" Vector__XXX
 SG_ VZE_Zeichen_01_KameraWied  : 51|1@1+ (1.000000,0.000000) [0.000000|1.000000] "" Motor_BEV
 SG_ VZE_Zeichen_02_KameraWied  : 52|1@1+ (1.000000,0.000000) [0.000000|1.000000] "" Vector__XXX
 SG_ VZE_Zeichen_03_KameraWied  : 53|1@1+ (1.000000,0.000000) [0.000000|1.000000] "" Vector__XXX
 SG_ VZE_Zeichen_01_Kamera  : 54|1@1+ (1.000000,0.000000) [0.000000|1.000000] "" Motor_BEV
 SG_ VZE_Zeichen_01_Karte  : 55|1@1+ (1.000000,0.000000) [0.000000|1.000000] "" Vector__XXX
 SG_ VZE_Zeichen_01_Gesetz  : 56|1@1+ (1.000000,0.000000) [0.000000|1.000000] "" Vector__XXX
 SG_ VZE_Zeichen_02_Kamera  : 57|1@1+ (1.000000,0.000000) [0.000000|1.000000] "" Vector__XXX
 SG_ VZE_Zeichen_02_Karte  : 58|1@1+ (1.000000,0.000000) [0.000000|1.000000] "" Vector__XXX
 SG_ VZE_Zeichen_02_Gesetz  : 59|1@1+ (1.000000,0.000000) [0.000000|1.000000] "" Vector__XXX
 SG_ VZE_Zeichen_03_Kamera  : 60|1@1+ (1.000000,0.000000) [0.000000|1.000000] "" Vector__XXX
 SG_ VZE_Zeichen_03_Karte  : 61|1@1+ (1.000000,0.000000) [0.000000|1.000000] "" Vector__XXX
 SG_ VZE_Zeichen_03_Gesetz  : 62|1@1+ (1.000000,0.000000) [0.000000|1.000000] "" Vector__XXX
 SG_ VZE_Gong  : 63|1@1+ (1.000000,0.000000) [0.000000|1.000000] "" Vector__XXX
 SG_ VZE_Anzeigeunterdrueck_Zeichen_5  : 72|1@1+ (1.000000,0.000000) [0.000000|1.000000] "" Vector__XXX
 SG_ VZE_Zeichen_05_KameraWied  : 73|1@1+ (1.000000,0.000000) [0.000000|1.000000] "" Vector__XXX
 SG_ VZE_Zeichen_05_Kamera  : 74|1@1+ (1.000000,0.000000) [0.000000|1.000000] "" Vector__XXX
 SG_ VZE_Verkehrszeichen_4  : 75|8@1+ (1.000000,0.000000) [1.000000|255.000000] "" Motor_BEV
 SG_ VZE_Verkehrszeichen_5  : 83|8@1+ (1.000000,0.000000) [1.000000|255.000000] "" Motor_BEV
 SG_ VZE_Anhaenger_Vmax  : 91|4@1+ (10.000000,10.000000) [10.000000|140.000000] "Unit_KiloMeterPerHour" Vector__XXX
 SG_ VZE_Zeichen_04_Gesetz  : 95|1@1+ (1.000000,0.000000) [0.000000|1.000000] "" Vector__XXX
 SG_ VZE_Zeichen_04_Kamera  : 96|1@1+ (1.000000,0.000000) [0.000000|1.000000] "" Vector__XXX
 SG_ VZE_Zeichen_04_KameraWied  : 97|1@1+ (1.000000,0.000000) [0.000000|1.000000] "" Vector__XXX
 SG_ VZE_Zeichen_04_Karte  : 98|1@1+ (1.000000,0.000000) [0.000000|1.000000] "" Vector__XXX
 SG_ VZE_Warnung_Verkehrszeichen_4  : 99|1@1+ (1.000000,0.000000) [0.000000|1.000000] "" Vector__XXX
 SG_ VZE_Warnung_Verkehrszeichen_5  : 100|1@1+ (1.000000,0.000000) [0.000000|1.000000] "" Vector__XXX
 SG_ VZE_Zeichen_05_Gesetz  : 101|1@1+ (1.000000,0.000000) [0.000000|1.000000] "" Vector__XXX
 SG_ VZE_Zusatzschild_4  : 102|4@1+ (1.000000,0.000000) [1.000000|15.000000] "" Vector__XXX
 SG_ VZE_Zusatzschild_5  : 106|4@1+ (1.000000,0.000000) [1.000000|15.000000] "" Vector__XXX
 SG_ VZE_Baustelle  : 110|2@1+ (1.000000,0.000000) [0.000000|3.000000] "" Vector__XXX
 SG_ VZE_Zeichen_05_Karte  : 112|1@1+ (1.000000,0.000000) [0.000000|1.000000] "" Vector__XXX
 SG_ VZE_Zeichen_05_Entfernung  : 113|7@1+ (1.000000,0.000000) [1.000000|127.000000] "Unit_Meter" Motor_BEV
 SG_ VZE_Zeichen_05_Entfernung_StdA  : 120|7@1+ (1.000000,0.000000) [1.000000|127.000000] "Unit_Meter" Motor_BEV
 SG_ VZE_Anzeigeunterdrueck_Zeichen_4  : 127|1@1+ (1.000000,0.000000) [0.000000|1.000000] "" Vector__XXX
 SG_ VZE_Verkehrszeichen_6  : 128|8@1+ (1.000000,0.000000) [1.000000|255.000000] "Unit_None" Motor_BEV
 SG_ VZE_Zusatzschild_6  : 136|4@1+ (1.000000,0.000000) [1.000000|15.000000] "" Vector__XXX
 SG_ VZE_Zeichen_06_Entfernung  : 140|7@1+ (1.000000,0.000000) [1.000000|127.000000] "Unit_Meter" Motor_BEV
 SG_ VZE_Zeichen_06_Entfernung_StdA  : 147|7@1+ (1.000000,0.000000) [1.000000|127.000000] "Unit_Meter" Motor_BEV
 SG_ VZE_Umweltinfo_Naesse  : 154|1@1+ (1.000000,0.000000) [0.000000|1.000000] "" Motor_BEV
 SG_ VZE_Umweltinfo_Nebel  : 155|1@1+ (1.000000,0.000000) [0.000000|1.000000] "" Motor_BEV
 SG_ VZE_Umweltinfo_Anhaengerbetrieb  : 156|1@1+ (1.000000,0.000000) [0.000000|1.000000] "" Vector__XXX
 SG_ VZE_Erweiterte_Information  : 157|8@1+ (1.000000,0.000000) [1.000000|255.000000] "Unit_None" Vector__XXX
 SG_ VZE_Tempowarnung_Status  : 165|1@1+ (1.000000,0.000000) [0.000000|1.000000] "" Vector__XXX
 SG_ VZE_Tempowarnung_Einheit  : 166|1@1+ (1.000000,0.000000) [0.000000|1.000000] "" Vector__XXX
 SG_ VZE_Tempowarnung_Offset  : 167|5@1+ (1.000000,0.000000) [1.000000|31.000000] "" Vector__XXX
 SG_ VZE_FoD_Status  : 206|2@1+ (1.000000,0.000000) [0.000000|3.000000] "" Vector__XXX
 SG_ VZE_Anzeige_ZS_1  : 208|4@1+ (1.000000,0.000000) [1.000000|15.000000] "Unit_None" Vector__XXX
 SG_ VZE_Anzeige_ZS_2  : 212|4@1+ (1.000000,0.000000) [1.000000|15.000000] "Unit_None" Vector__XXX
 SG_ VZE_Anzeige_ZS_3  : 216|4@1+ (1.000000,0.000000) [1.000000|15.000000] "Unit_None" Vector__XXX
 SG_ VZE_Hinweistext_03  : 220|4@1+ (1.000000,0.000000) [1.000000|15.000000] "" Vector__XXX
 SG_ VZE_Land  : 224|5@1+ (1.000000,0.000000) [1.000000|31.000000] "" Vector__XXX
 SG_ VZE_Warnung_VZ_1  : 229|1@1+ (1.000000,0.000000) [0.000000|1.000000] "" Vector__XXX
 SG_ VZE_Warnung_VZ_2  : 230|1@1+ (1.000000,0.000000) [0.000000|1.000000] "" Vector__XXX
 SG_ VZE_Warnung_VZ_3  : 231|1@1+ (1.000000,0.000000) [0.000000|1.000000] "" Vector__XXX
 SG_ VZE_Anzeige_VZ_1  : 232|8@1+ (1.000000,0.000000) [1.000000|255.000000] "" Vector__XXX
 SG_ VZE_Anzeige_VZ_2  : 240|8@1+ (1.000000,0.000000) [1.000000|255.000000] "Unit_None" Vector__XXX
 SG_ VZE_Anzeige_VZ_3  : 248|8@1+ (1.000000,0.000000) [1.000000|255.000000] "Unit_None" Vector__XXX

BO_ 181 Waehlhebel_04: 8 ICAS1_Gateway
 SG_ Waehlhebel_04_CRC  : 0|8@1+ (1.000000,0.000000) [0.000000|255.000000] "" Motor_BEV
 SG_ Waehlhebel_04_BZ  : 8|4@1+ (1.000000,0.000000) [0.000000|15.000000] "" Motor_BEV
 SG_ WH_gespeicherte_Fahrstufe  : 12|3@1+ (1.000000,0.000000) [0.000000|7.000000] "" Vector__XXX
 SG_ WH_Initialisierung  : 15|1@1+ (1.000000,0.000000) [0.000000|1.000000] "" Motor_BEV
 SG_ WH_SensorPos_roh  : 16|4@1+ (1.000000,0.000000) [0.000000|15.000000] "" Motor_BEV
 SG_ WH_SensorPos_roh_inv  : 20|4@1+ (1.000000,0.000000) [0.000000|15.000000] "" Motor_BEV
 SG_ WH_Testergebnis  : 24|8@1+ (1.000000,0.000000) [0.000000|255.000000] "" Vector__XXX
 SG_ WH_Test_Aktiv  : 32|1@1+ (1.000000,0.000000) [0.000000|1.000000] "" Vector__XXX
 SG_ WH_Ist_Haltemagnet  : 33|2@1+ (1.000000,0.000000) [0.000000|3.000000] "" Motor_BEV
 SG_ WH_Variante  : 35|4@1+ (1.000000,0.000000) [0.000000|15.000000] "" Motor_BEV
 SG_ WH_Entsperrtaste_02  : 39|2@1+ (1.000000,0.000000) [0.000000|3.000000] "" Motor_BEV
 SG_ WH_P_Taste  : 41|2@1+ (1.000000,0.000000) [0.000000|3.000000] "" Motor_BEV
 SG_ WH_Ende_N_Haltephase  : 43|1@1+ (1.000000,0.000000) [0.000000|1.000000] "" Vector__XXX
 SG_ WH_Fahrstufe  : 44|4@1+ (1.000000,0.000000) [0.000000|15.000000] "" Motor_BEV
 SG_ WH_Status_Shiftlock  : 48|3@1+ (1.000000,0.000000) [0.000000|7.000000] "" Motor_BEV
 SG_ WH_Zustand_N_Haltephase  : 51|2@1+ (1.000000,0.000000) [0.000000|3.000000] "" Vector__XXX

BO_ 2463978687 Waehlhebel_06: 8 ICAS1_Gateway
 SG_ WH_Fehler_Haltemagnet_Status  : 41|1@1+ (1.000000,0.000000) [0.000000|1.000000] "" Motor_BEV
 SG_ WH_Fehler_CRC_SBM  : 42|1@1+ (1.000000,0.000000) [0.000000|1.000000] "" Motor_BEV
 SG_ WH_Fehler_CRC_SBM_Status  : 43|1@1+ (1.000000,0.000000) [0.000000|1.000000] "" Motor_BEV
 SG_ WH_Fehler_Timeout_SBM  : 44|1@1+ (1.000000,0.000000) [0.000000|1.000000] "" Motor_BEV
 SG_ WH_Fehler_Timeout_SBM_Status  : 45|1@1+ (1.000000,0.000000) [0.000000|1.000000] "" Motor_BEV
 SG_ WH_Fehler_Ueberspannung  : 46|1@1+ (1.000000,0.000000) [0.000000|1.000000] "" Motor_BEV
 SG_ WH_Fehler_Ueberspannung_Status  : 47|1@1+ (1.000000,0.000000) [0.000000|1.000000] "" Motor_BEV
 SG_ WH_Fehler_BZ_SBM  : 48|1@1+ (1.000000,0.000000) [0.000000|1.000000] "" Motor_BEV
 SG_ WH_Fehler_BZ_SBM_Status  : 49|1@1+ (1.000000,0.000000) [0.000000|1.000000] "" Motor_BEV
 SG_ WH_Fehler_Unterspannung  : 50|1@1+ (1.000000,0.000000) [0.000000|1.000000] "" Motor_BEV
 SG_ WH_Fehler_Unterspannung_Status  : 51|1@1+ (1.000000,0.000000) [0.000000|1.000000] "" Motor_BEV
 SG_ WH_Fehler_Ausleuchtung  : 52|1@1+ (1.000000,0.000000) [0.000000|1.000000] "" Motor_BEV
 SG_ WH_Fehler_Ausleuchtung_Status  : 53|1@1+ (1.000000,0.000000) [0.000000|1.000000] "" Motor_BEV
 SG_ WH_Fehler_Entsperrtaste  : 54|1@1+ (1.000000,0.000000) [0.000000|1.000000] "" Motor_BEV
 SG_ WH_Fehler_Entsperrtaste_Status  : 55|1@1+ (1.000000,0.000000) [0.000000|1.000000] "" Motor_BEV
 SG_ WH_Fehler_P_Taste  : 56|1@1+ (1.000000,0.000000) [0.000000|1.000000] "" Motor_BEV
 SG_ WH_Fehler_P_Taste_Status  : 57|1@1+ (1.000000,0.000000) [0.000000|1.000000] "" Motor_BEV
 SG_ WH_Fehler_Sensor_einfach  : 58|1@1+ (1.000000,0.000000) [0.000000|1.000000] "" Motor_BEV
 SG_ WH_Fehler_Sensor_einfach_Status  : 59|1@1+ (1.000000,0.000000) [0.000000|1.000000] "" Motor_BEV
 SG_ WH_Fehler_Sensor_mehrfach  : 60|1@1+ (1.000000,0.000000) [0.000000|1.000000] "" Motor_BEV
 SG_ WH_Fehler_Sensor_mehrfach_Status  : 61|1@1+ (1.000000,0.000000) [0.000000|1.000000] "" Motor_BEV
 SG_ WH_Fehler_Shiftlock  : 62|1@1+ (1.000000,0.000000) [0.000000|1.000000] "" Motor_BEV
 SG_ WH_Fehler_Shiftlock_Status  : 63|1@1+ (1.000000,0.000000) [0.000000|1.000000] "" Motor_BEV

BO_ 916 WBA_03: 8 Motor_BEV
 SG_ WBA_03_CRC  : 0|8@1+ (1.000000,0.000000) [0.000000|255.000000] "" ICAS1_Gateway
 SG_ WBA_03_BZ  : 8|4@1+ (1.000000,0.000000) [0.000000|15.000000] "" ICAS1_Gateway
 SG_ WBA_Fahrstufe_02  : 12|4@1+ (1.000000,0.000000) [0.000000|15.000000] "" ICAS1_Gateway ICAS1_KommunikationsServer
 SG_ WBA_ZielFahrstufe  : 16|4@1+ (1.000000,0.000000) [0.000000|15.000000] "" ICAS1_Gateway
 SG_ WBA_GE_Warnung_02  : 20|4@1+ (1.000000,0.000000) [0.000000|15.000000] "" ICAS1_Gateway
 SG_ WBA_eing_Gang_02  : 24|4@1+ (1.000000,0.000000) [0.000000|15.000000] "" ICAS1_Gateway
 SG_ WBA_GE_Texte  : 28|3@1+ (1.000000,0.000000) [0.000000|7.000000] "" ICAS1_Gateway
 SG_ WBA_Segeln_aktiv  : 31|1@1+ (1.000000,0.000000) [0.000000|1.000000] "" ICAS1_Gateway
 SG_ WBA_Schaltschema_02  : 32|3@1+ (1.000000,0.000000) [0.000000|7.000000] "" ICAS1_Gateway
 SG_ WBA_Schaltschema_FS_inaktiv  : 35|2@1+ (1.000000,0.000000) [0.000000|3.000000] "" ICAS1_Gateway
 SG_ WBA_GE_Zusatzwarnungen  : 37|3@1+ (1.000000,0.000000) [0.000000|7.000000] "" ICAS1_Gateway
 SG_ GE_Sollgang  : 40|4@1+ (1.000000,0.000000) [0.000000|15.000000] "" ICAS1_Gateway
 SG_ GE_Tipschaltempf_verfuegbar  : 44|1@1+ (1.000000,0.000000) [0.000000|1.000000] "" ICAS1_Gateway
 SG_ WBA_GE_Texte_02  : 45|3@1+ (1.000000,0.000000) [0.000000|7.000000] "" ICAS1_Gateway
 SG_ WBA_Schaltschema_Tippgasse  : 48|1@1+ (1.000000,0.000000) [0.000000|1.000000] "" ICAS1_Gateway
 SG_ WBA_Schaltschema_Fahreraktion  : 49|1@1+ (1.000000,0.000000) [0.000000|1.000000] "" ICAS1_Gateway
 SG_ WBA_Schaltschema_FS_vorwaerts  : 50|2@1+ (1.000000,0.000000) [0.000000|3.000000] "" ICAS1_Gateway
 SG_ WBA_Shiftlock_Lampe  : 52|1@1+ (1.000000,0.000000) [0.000000|1.000000] "" ICAS1_Gateway
 SG_ WBA_Anforderung_Akustik  : 53|1@1+ (1.000000,0.000000) [0.000000|1.000000] "" ICAS1_Gateway
 SG_ WBA_Blinken  : 54|1@1+ (1.000000,0.000000) [0.000000|1.000000] "" ICAS1_Gateway
 SG_ GE_Wiederstart_Anz_Std  : 55|1@1+ (1.000000,0.000000) [0.000000|1.000000] "" ICAS1_Gateway
 SG_ GE_Stoppverbot_Anz_01  : 56|1@1+ (1.000000,0.000000) [0.000000|1.000000] "" ICAS1_Gateway
 SG_ GE_Stoppverbot_Anz_02  : 57|1@1+ (1.000000,0.000000) [0.000000|1.000000] "" ICAS1_Gateway
 SG_ GE_Stoppverbot_Anz_03  : 58|1@1+ (1.000000,0.000000) [0.000000|1.000000] "" ICAS1_Gateway
 SG_ GE_Stoppverbot_Anz_04  : 59|1@1+ (1.000000,0.000000) [0.000000|1.000000] "" ICAS1_Gateway
 SG_ GE_Stoppverbot_Anz_05  : 60|1@1+ (1.000000,0.000000) [0.000000|1.000000] "" ICAS1_Gateway
 SG_ GE_Stoppverbot_Anz_06  : 61|1@1+ (1.000000,0.000000) [0.000000|1.000000] "" ICAS1_Gateway
 SG_ GE_Stoppverbot_Anz_07  : 62|1@1+ (1.000000,0.000000) [0.000000|1.000000] "" ICAS1_Gateway
 SG_ GE_Stoppverbot_Anz_Std  : 63|1@1+ (1.000000,0.000000) [0.000000|1.000000] "" ICAS1_Gateway

BO_ 1361 WFS_01: 8 ICAS1_Gateway
 SG_ WFS_Schluessel_Fahrberecht  : 0|4@1+ (1.000000,0.000000) [0.000000|15.000000] "" Vector__XXX
 SG_ WFS_Verbauinfo_ELV  : 4|1@1+ (1.000000,0.000000) [0.000000|1.000000] "" Vector__XXX
 SG_ WFS_ID_Geb_autorisiert  : 5|1@1+ (1.000000,0.000000) [0.000000|1.000000] "" Vector__XXX
 SG_ WFS_ID_Geb_autorisiert_in_Kl15  : 6|1@1+ (1.000000,0.000000) [0.000000|1.000000] "" Vector__XXX
 SG_ WFS_ID_Geb_steckt  : 7|1@1+ (1.000000,0.000000) [0.000000|1.000000] "" Vector__XXX
 SG_ WFS_Schluessel_Soll  : 8|4@1+ (1.000000,0.000000) [0.000000|15.000000] "" Vector__XXX
 SG_ WFS_Schluessel_Ist  : 12|4@1+ (1.000000,0.000000) [0.000000|15.000000] "" Vector__XXX
 SG_ WFS_Safe  : 16|1@1+ (1.000000,0.000000) [0.000000|1.000000] "" Vector__XXX
 SG_ WFS_LZ  : 17|2@1+ (1.000000,0.000000) [0.000000|3.000000] "" Vector__XXX
 SG_ WFS_ELV_authorisiert  : 19|1@1+ (1.000000,0.000000) [0.000000|1.000000] "" Vector__XXX
 SG_ WFS_LF_Aktiv  : 20|1@1+ (1.000000,0.000000) [0.000000|1.000000] "" Vector__XXX
 SG_ WFS_Betrieb_Lesespule  : 21|1@1+ (1.000000,0.000000) [0.000000|1.000000] "" Vector__XXX
 SG_ WFS_Klemmenfreigabe  : 22|1@1+ (1.000000,0.000000) [0.000000|1.000000] "" Motor_BEV
 SG_ WFS_Klemmenfreigabe_Signatur  : 23|11@1+ (1.000000,0.000000) [0.000000|2047.000000] "" Vector__XXX
 SG_ WFS_Fahrerhinweise  : 34|2@1+ (1.000000,0.000000) [0.000000|3.000000] "" Vector__XXX
 SG_ WFS_Parken_Status  : 36|2@1+ (1.000000,0.000000) [0.000000|3.000000] "" Vector__XXX

BO_ 2617028096 XCP_Airbag_CRO_01: 64 Vector__XXX
 SG_ XCP_Airbag_CRO_01_Data  : 0|512@1+ (1.000000,0.000000) [0.000000|13407807929942597099574024998205846127479365820592393377723561443721764030073546976801874298166903427690031858186486050853753882811946569946433649006084096.000000] "" Airbag

BO_ 2617028097 XCP_Airbag_DTO_01: 64 Airbag
 SG_ XCP_Airbag_DTO_01_Data  : 0|512@1+ (1.000000,0.000000) [0.000000|13407807929942597099574024998205846127479365820592393377723561443721764030073546976801874298166903427690031858186486050853753882811946569946433649006084096.000000] "" Vector__XXX

BO_ 2617239040 XCP_EMotor_01_CRO_01: 64 Vector__XXX
 SG_ XCP_EMotor_01_CRO_01_Data  : 0|64@1+ (1.000000,0.000000) [0.000000|18446744073709551616.000000] "" LE1

BO_ 2617239041 XCP_EMotor_01_DTO_01: 64 LE1
 SG_ XCP_EMotor_01_DTO_01_Data  : 0|64@1+ (1.000000,0.000000) [0.000000|18446744073709551616.000000] "" Vector__XXX

BO_ 2617239042 XCP_EMotor_01_DTO_02: 64 LE1
 SG_ XCP_EMotor_01_DTO_02_Data  : 0|64@1+ (1.000000,0.000000) [0.000000|18446744073709551616.000000] "" Vector__XXX

BO_ 2617239043 XCP_EMotor_01_DTO_03: 64 LE1
 SG_ XCP_EMotor_01_DTO_03_Data  : 0|64@1+ (1.000000,0.000000) [0.000000|18446744073709551616.000000] "" Vector__XXX

BO_ 2617239044 XCP_EMotor_01_DTO_04: 64 LE1
 SG_ XCP_EMotor_01_DTO_04_Data  : 0|64@1+ (1.000000,0.000000) [0.000000|18446744073709551616.000000] "" Vector__XXX

BO_ 2617122304 XCP_EMotor_02_CRO_01: 64 Vector__XXX
 SG_ XCP_EMotor_02_CRO_01_Data  : 0|64@1+ (1.000000,0.000000) [0.000000|18446744073709551616.000000] "" LE2

BO_ 2617122305 XCP_EMotor_02_DTO_01: 64 LE2
 SG_ XCP_EMotor_02_DTO_01_Data  : 0|64@1+ (1.000000,0.000000) [0.000000|18446744073709551616.000000] "" Vector__XXX

BO_ 2617122306 XCP_EMotor_02_DTO_02: 64 LE2
 SG_ XCP_EMotor_02_DTO_02_Data  : 0|64@1+ (1.000000,0.000000) [0.000000|18446744073709551616.000000] "" Vector__XXX

BO_ 2617122307 XCP_EMotor_02_DTO_03: 64 LE2
 SG_ XCP_EMotor_02_DTO_03_Data  : 0|64@1+ (1.000000,0.000000) [0.000000|18446744073709551616.000000] "" Vector__XXX

BO_ 2617122308 XCP_EMotor_02_DTO_04: 64 LE2
 SG_ XCP_EMotor_02_DTO_04_Data  : 0|64@1+ (1.000000,0.000000) [0.000000|18446744073709551616.000000] "" Vector__XXX

BO_ 2617226768 XCP_Motor_CRO_01: 64 Vector__XXX
 SG_ XCP_Motor_CRO_01_Data  : 0|64@1+ (1.000000,0.000000) [0.000000|18446744073709551616.000000] "" Motor_BEV

BO_ 2617226769 XCP_Motor_DTO_01: 64 Motor_BEV
 SG_ XCP_Motor_DTO_01_Data  : 0|64@1+ (1.000000,0.000000) [0.000000|18446744073709551616.000000] "" Vector__XXX

BO_ 1411 ZV_02: 8 ICAS1_Gateway
 SG_ ZV_verriegeln_Anf  : 0|1@1+ (1.000000,0.000000) [0.000000|1.000000] "" Vector__XXX
 SG_ ZV_STSG_HFS_Anf  : 1|1@1+ (1.000000,0.000000) [0.000000|1.000000] "" Vector__XXX
 SG_ ZV_STSG_HBFS_Anf  : 2|1@1+ (1.000000,0.000000) [0.000000|1.000000] "" Vector__XXX
 SG_ ZV_Anf_Challenge_Auth  : 3|1@1+ (1.000000,0.000000) [0.000000|1.000000] "" Vector__XXX
 SG_ BCM_FH_Freigabe  : 12|1@1+ (1.000000,0.000000) [0.000000|1.000000] "" Vector__XXX
 SG_ BCM_Komfortfkt_Freigabe  : 13|1@1+ (1.000000,0.000000) [0.000000|1.000000] "" Vector__XXX
 SG_ BCM_HSK_Freigabe  : 14|1@1+ (1.000000,0.000000) [0.000000|1.000000] "" Vector__XXX
 SG_ BCM_Verdeck_Freigabe  : 15|1@1+ (1.000000,0.000000) [0.000000|1.000000] "" Vector__XXX
 SG_ ZV_verriegelt_intern_ist  : 16|1@1+ (1.000000,0.000000) [0.000000|1.000000] "" Vector__XXX
 SG_ ZV_verriegelt_extern_ist  : 17|1@1+ (1.000000,0.000000) [0.000000|1.000000] "" Airbag
 SG_ ZV_verriegelt_intern_soll  : 18|1@1+ (1.000000,0.000000) [0.000000|1.000000] "" Vector__XXX
 SG_ ZV_verriegelt_extern_soll  : 19|1@1+ (1.000000,0.000000) [0.000000|1.000000] "" Airbag
 SG_ ZV_gesafet_extern_ist  : 20|1@1+ (1.000000,0.000000) [0.000000|1.000000] "" Vector__XXX
 SG_ ZV_gesafet_extern_soll  : 21|1@1+ (1.000000,0.000000) [0.000000|1.000000] "" Vector__XXX
 SG_ ZV_Einzeltuerentriegelung  : 22|1@1+ (1.000000,0.000000) [0.000000|1.000000] "" Vector__XXX
 SG_ ZV_Heckeinzelentriegelung  : 23|1@1+ (1.000000,0.000000) [0.000000|1.000000] "" Vector__XXX
 SG_ ZV_FT_offen  : 24|1@1+ (1.000000,0.000000) [0.000000|1.000000] "" Motor_BEV
 SG_ ZV_BT_offen  : 25|1@1+ (1.000000,0.000000) [0.000000|1.000000] "" Motor_BEV
 SG_ ZV_HFS_offen  : 26|1@1+ (1.000000,0.000000) [0.000000|1.000000] "" Motor_BEV
 SG_ ZV_HBFS_offen  : 27|1@1+ (1.000000,0.000000) [0.000000|1.000000] "" Motor_BEV
 SG_ ZV_HD_offen  : 28|1@1+ (1.000000,0.000000) [0.000000|1.000000] "" Motor_BEV
 SG_ ZV_HS_offen  : 29|1@1+ (1.000000,0.000000) [0.000000|1.000000] "" Vector__XXX
 SG_ IRUE_aktiv  : 30|1@1+ (1.000000,0.000000) [0.000000|1.000000] "" Vector__XXX
 SG_ DWA_aktiv  : 31|1@1+ (1.000000,0.000000) [0.000000|1.000000] "" Vector__XXX
 SG_ FFB_HDF_Taste  : 34|1@1+ (1.000000,0.000000) [0.000000|1.000000] "" Vector__XXX
 SG_ FFB_Panik_Taste  : 35|1@1+ (1.000000,0.000000) [0.000000|1.000000] "" Vector__XXX
 SG_ FFB_Auf_Taste  : 36|1@1+ (1.000000,0.000000) [0.000000|1.000000] "" Vector__XXX
 SG_ FFB_Zu_Taste  : 37|1@1+ (1.000000,0.000000) [0.000000|1.000000] "" Vector__XXX
 SG_ FFB_CarFinder  : 38|1@1+ (1.000000,0.000000) [0.000000|1.000000] "" Vector__XXX
 SG_ FFB_Komfortoeffnen  : 39|1@1+ (1.000000,0.000000) [0.000000|1.000000] "" Vector__XXX
 SG_ FFB_Komfortschliessen  : 40|1@1+ (1.000000,0.000000) [0.000000|1.000000] "" Vector__XXX
 SG_ FBS_IDG_in_Reichweite  : 41|1@1+ (1.000000,0.000000) [0.000000|1.000000] "" Vector__XXX
 SG_ ZV_Schluessel_Zugang  : 42|4@1+ (1.000000,0.000000) [0.000000|15.000000] "" Vector__XXX
 SG_ ZV_SafeFunktion_aktiv  : 46|1@1+ (1.000000,0.000000) [0.000000|1.000000] "" Vector__XXX
 SG_ FBS_Warn_Schluessel_Batt  : 47|1@1+ (1.000000,0.000000) [0.000000|1.000000] "" Vector__XXX
 SG_ ZV_Oeffnungsmodus  : 48|2@1+ (1.000000,0.000000) [0.000000|3.000000] "" Vector__XXX
 SG_ ZV_ist_Zustand_verfuegbar  : 54|1@1+ (1.000000,0.000000) [0.000000|1.000000] "" Vector__XXX
 SG_ IRUE_Taster_Fkts_LED  : 55|1@1+ (1.000000,0.000000) [0.000000|1.000000] "" Vector__XXX
 SG_ ZV_Tankklappe_offen  : 56|1@1+ (1.000000,0.000000) [0.000000|1.000000] "" Vector__XXX
 SG_ ZV_Rollo_auf  : 57|1@1+ (1.000000,0.000000) [0.000000|1.000000] "" Vector__XXX
 SG_ ZV_Rollo_zu  : 58|1@1+ (1.000000,0.000000) [0.000000|1.000000] "" Vector__XXX
 SG_ ZV_SAD_auf  : 59|1@1+ (1.000000,0.000000) [0.000000|1.000000] "" Vector__XXX
 SG_ ZV_SAD_zu  : 60|1@1+ (1.000000,0.000000) [0.000000|1.000000] "" Vector__XXX
 SG_ ZV_verriegelt_soll  : 62|2@1+ (1.000000,0.000000) [0.000000|3.000000] "" Vector__XXX

BU_:  Airbag BAP_Tester ICAS1_Gateway ICAS1_KommunikationsServer LE1 LE2 Motor_BEV Schaltbetaetigung

BO_ 2463978663 VZE_04: 32 ICAS1_Gateway
 SG_ VZE_Anzeigemodus  : 0|2@1+ (1.000000,0.000000) [0.000000|3.000000] "" Vector__XXX
 SG_ VZE_Hinweistext  : 2|3@1+ (1.000000,0.000000) [1.000000|7.000000] "" Motor_BEV
 SG_ VZE_Verkehrszeichen_Einheit  : 8|1@1+ (1.000000,0.000000) [0.000000|1.000000] "" Vector__XXX
 SG_ VZE_Anzeigeunterdrueck_Zeichen_3  : 9|1@1+ (1.000000,0.000000) [0.000000|1.000000] "" Vector__XXX
 SG_ VZE_Anzeigeunterdrueck_Zeichen_2  : 10|1@1+ (1.000000,0.000000) [0.000000|1.000000] "" Vector__XXX
 SG_ VZE_Verkehrszeichen_1  : 11|8@1+ (1.000000,0.000000) [1.000000|255.000000] "" Motor_BEV
 SG_ VZE_Verkehrszeichen_2  : 19|8@1+ (1.000000,0.000000) [1.000000|255.000000] "" Vector__XXX
 SG_ VZE_Verkehrszeichen_3  : 27|8@1+ (1.000000,0.000000) [1.000000|255.000000] "" Vector__XXX
 SG_ VZE_Warnung_Verkehrszeichen_1  : 35|1@1+ (1.000000,0.000000) [0.000000|1.000000] "" Vector__XXX
 SG_ VZE_Warnung_Verkehrszeichen_2  : 36|1@1+ (1.000000,0.000000) [0.000000|1.000000] "" Vector__XXX
 SG_ VZE_Warnung_Verkehrszeichen_3  : 37|1@1+ (1.000000,0.000000) [0.000000|1.000000] "" Vector__XXX
 SG_ VZE_Zusatzschild_1  : 38|4@1+ (1.000000,0.000000) [1.000000|15.000000] "" Vector__XXX
 SG_ VZE_Zusatzschild_2  : 42|4@1+ (1.000000,0.000000) [1.000000|15.000000] "" Vector__XXX
 SG_ VZE_Zusatzschild_3  : 46|4@1+ (1.000000,0.000000) [1.000000|15.000000] "" Vector__XXX
 SG_ VZE_Anzeigeunterdrueck_Zeichen_1  : 50|1@1+ (1.000000,0.000000) [0.000000|1.000000] "" Vector__XXX
 SG_ VZE_Zeichen_01_KameraWied  : 51|1@1+ (1.000000,0.000000) [0.000000|1.000000] "" Motor_BEV
 SG_ VZE_Zeichen_02_KameraWied  : 52|1@1+ (1.000000,0.000000) [0.000000|1.000000] "" Vector__XXX
 SG_ VZE_Zeichen_03_KameraWied  : 53|1@1+ (1.000000,0.000000) [0.000000|1.000000] "" Vector__XXX
 SG_ VZE_Zeichen_01_Kamera  : 54|1@1+ (1.000000,0.000000) [0.000000|1.000000] "" Motor_BEV
 SG_ VZE_Zeichen_01_Karte  : 55|1@1+ (1.000000,0.000000) [0.000000|1.000000] "" Vector__XXX
 SG_ VZE_Zeichen_01_Gesetz  : 56|1@1+ (1.000000,0.000000) [0.000000|1.000000] "" Vector__XXX
 SG_ VZE_Zeichen_02_Kamera  : 57|1@1+ (1.000000,0.000000) [0.000000|1.000000] "" Vector__XXX
 SG_ VZE_Zeichen_02_Karte  : 58|1@1+ (1.000000,0.000000) [0.000000|1.000000] "" Vector__XXX
 SG_ VZE_Zeichen_02_Gesetz  : 59|1@1+ (1.000000,0.000000) [0.000000|1.000000] "" Vector__XXX
 SG_ VZE_Zeichen_03_Kamera  : 60|1@1+ (1.000000,0.000000) [0.000000|1.000000] "" Vector__XXX
 SG_ VZE_Zeichen_03_Karte  : 61|1@1+ (1.000000,0.000000) [0.000000|1.000000] "" Vector__XXX
 SG_ VZE_Zeichen_03_Gesetz  : 62|1@1+ (1.000000,0.000000) [0.000000|1.000000] "" Vector__XXX
 SG_ VZE_Gong  : 63|1@1+ (1.000000,0.000000) [0.000000|1.000000] "" Vector__XXX
 SG_ VZE_Anzeigeunterdrueck_Zeichen_5  : 72|1@1+ (1.000000,0.000000) [0.000000|1.000000] "" Vector__XXX
 SG_ VZE_Zeichen_05_KameraWied  : 73|1@1+ (1.000000,0.000000) [0.000000|1.000000] "" Vector__XXX
 SG_ VZE_Zeichen_05_Kamera  : 74|1@1+ (1.000000,0.000000) [0.000000|1.000000] "" Vector__XXX
 SG_ VZE_Verkehrszeichen_4  : 75|8@1+ (1.000000,0.000000) [1.000000|255.000000] "" Motor_BEV
 SG_ VZE_Verkehrszeichen_5  : 83|8@1+ (1.000000,0.000000) [1.000000|255.000000] "" Motor_BEV
 SG_ VZE_Anhaenger_Vmax  : 91|4@1+ (10.000000,10.000000) [10.000000|140.000000] "Unit_KiloMeterPerHour" Vector__XXX
 SG_ VZE_Zeichen_04_Gesetz  : 95|1@1+ (1.000000,0.000000) [0.000000|1.000000] "" Vector__XXX
 SG_ VZE_Zeichen_04_Kamera  : 96|1@1+ (1.000000,0.000000) [0.000000|1.000000] "" Vector__XXX
 SG_ VZE_Zeichen_04_KameraWied  : 97|1@1+ (1.000000,0.000000) [0.000000|1.000000] "" Vector__XXX
 SG_ VZE_Zeichen_04_Karte  : 98|1@1+ (1.000000,0.000000) [0.000000|1.000000] "" Vector__XXX
 SG_ VZE_Warnung_Verkehrszeichen_4  : 99|1@1+ (1.000000,0.000000) [0.000000|1.000000] "" Vector__XXX
 SG_ VZE_Warnung_Verkehrszeichen_5  : 100|1@1+ (1.000000,0.000000) [0.000000|1.000000] "" Vector__XXX
 SG_ VZE_Zeichen_05_Gesetz  : 101|1@1+ (1.000000,0.000000) [0.000000|1.000000] "" Vector__XXX
 SG_ VZE_Zusatzschild_4  : 102|4@1+ (1.000000,0.000000) [1.000000|15.000000] "" Vector__XXX
 SG_ VZE_Zusatzschild_5  : 106|4@1+ (1.000000,0.000000) [1.000000|15.000000] "" Vector__XXX
 SG_ VZE_Baustelle  : 110|2@1+ (1.000000,0.000000) [0.000000|3.000000] "" Vector__XXX
 SG_ VZE_Zeichen_05_Karte  : 112|1@1+ (1.000000,0.000000) [0.000000|1.000000] "" Vector__XXX
 SG_ VZE_Zeichen_05_Entfernung  : 113|7@1+ (1.000000,0.000000) [1.000000|127.000000] "Unit_Meter" Motor_BEV
 SG_ VZE_Zeichen_05_Entfernung_StdA  : 120|7@1+ (1.000000,0.000000) [1.000000|127.000000] "Unit_Meter" Motor_BEV
 SG_ VZE_Anzeigeunterdrueck_Zeichen_4  : 127|1@1+ (1.000000,0.000000) [0.000000|1.000000] "" Vector__XXX
 SG_ VZE_Verkehrszeichen_6  : 128|8@1+ (1.000000,0.000000) [1.000000|255.000000] "Unit_None" Motor_BEV
 SG_ VZE_Zusatzschild_6  : 136|4@1+ (1.000000,0.000000) [1.000000|15.000000] "" Vector__XXX
 SG_ VZE_Zeichen_06_Entfernung  : 140|7@1+ (1.000000,0.000000) [1.000000|127.000000] "Unit_Meter" Motor_BEV
 SG_ VZE_Zeichen_06_Entfernung_StdA  : 147|7@1+ (1.000000,0.000000) [1.000000|127.000000] "Unit_Meter" Motor_BEV
 SG_ VZE_Umweltinfo_Naesse  : 154|1@1+ (1.000000,0.000000) [0.000000|1.000000] "" Motor_BEV
 SG_ VZE_Umweltinfo_Nebel  : 155|1@1+ (1.000000,0.000000) [0.000000|1.000000] "" Motor_BEV
 SG_ VZE_Umweltinfo_Anhaengerbetrieb  : 156|1@1+ (1.000000,0.000000) [0.000000|1.000000] "" Vector__XXX
 SG_ VZE_Erweiterte_Information  : 157|8@1+ (1.000000,0.000000) [1.000000|255.000000] "Unit_None" Vector__XXX
 SG_ VZE_Tempowarnung_Status  : 165|1@1+ (1.000000,0.000000) [0.000000|1.000000] "" Vector__XXX
 SG_ VZE_Tempowarnung_Einheit  : 166|1@1+ (1.000000,0.000000) [0.000000|1.000000] "" Vector__XXX
 SG_ VZE_Tempowarnung_Offset  : 167|5@1+ (1.000000,0.000000) [1.000000|31.000000] "" Vector__XXX
 SG_ VZE_FoD_Status  : 206|2@1+ (1.000000,0.000000) [0.000000|3.000000] "" Vector__XXX
 SG_ VZE_Anzeige_ZS_1  : 208|4@1+ (1.000000,0.000000) [1.000000|15.000000] "Unit_None" Vector__XXX
 SG_ VZE_Anzeige_ZS_2  : 212|4@1+ (1.000000,0.000000) [1.000000|15.000000] "Unit_None" Vector__XXX
 SG_ VZE_Anzeige_ZS_3  : 216|4@1+ (1.000000,0.000000) [1.000000|15.000000] "Unit_None" Vector__XXX
 SG_ VZE_Hinweistext_03  : 220|4@1+ (1.000000,0.000000) [1.000000|15.000000] "" Vector__XXX
 SG_ VZE_Land  : 224|5@1+ (1.000000,0.000000) [1.000000|31.000000] "" Vector__XXX
 SG_ VZE_Warnung_VZ_1  : 229|1@1+ (1.000000,0.000000) [0.000000|1.000000] "" Vector__XXX
 SG_ VZE_Warnung_VZ_2  : 230|1@1+ (1.000000,0.000000) [0.000000|1.000000] "" Vector__XXX
 SG_ VZE_Warnung_VZ_3  : 231|1@1+ (1.000000,0.000000) [0.000000|1.000000] "" Vector__XXX
 SG_ VZE_Anzeige_VZ_1  : 232|8@1+ (1.000000,0.000000) [1.000000|255.000000] "" Vector__XXX
 SG_ VZE_Anzeige_VZ_2  : 240|8@1+ (1.000000,0.000000) [1.000000|255.000000] "Unit_None" Vector__XXX
 SG_ VZE_Anzeige_VZ_3  : 248|8@1+ (1.000000,0.000000) [1.000000|255.000000] "Unit_None" Vector__XXX

BO_ 181 Waehlhebel_04: 8 ICAS1_Gateway
 SG_ Waehlhebel_04_CRC  : 0|8@1+ (1.000000,0.000000) [0.000000|255.000000] "" Motor_BEV
 SG_ Waehlhebel_04_BZ  : 8|4@1+ (1.000000,0.000000) [0.000000|15.000000] "" Motor_BEV
 SG_ WH_gespeicherte_Fahrstufe  : 12|3@1+ (1.000000,0.000000) [0.000000|7.000000] "" Vector__XXX
 SG_ WH_Initialisierung  : 15|1@1+ (1.000000,0.000000) [0.000000|1.000000] "" Motor_BEV
 SG_ WH_SensorPos_roh  : 16|4@1+ (1.000000,0.000000) [0.000000|15.000000] "" Motor_BEV
 SG_ WH_SensorPos_roh_inv  : 20|4@1+ (1.000000,0.000000) [0.000000|15.000000] "" Motor_BEV
 SG_ WH_Testergebnis  : 24|8@1+ (1.000000,0.000000) [0.000000|255.000000] "" Vector__XXX
 SG_ WH_Test_Aktiv  : 32|1@1+ (1.000000,0.000000) [0.000000|1.000000] "" Vector__XXX
 SG_ WH_Ist_Haltemagnet  : 33|2@1+ (1.000000,0.000000) [0.000000|3.000000] "" Motor_BEV
 SG_ WH_Variante  : 35|4@1+ (1.000000,0.000000) [0.000000|15.000000] "" Motor_BEV
 SG_ WH_Entsperrtaste_02  : 39|2@1+ (1.000000,0.000000) [0.000000|3.000000] "" Motor_BEV
 SG_ WH_P_Taste  : 41|2@1+ (1.000000,0.000000) [0.000000|3.000000] "" Motor_BEV
 SG_ WH_Ende_N_Haltephase  : 43|1@1+ (1.000000,0.000000) [0.000000|1.000000] "" Vector__XXX
 SG_ WH_Fahrstufe  : 44|4@1+ (1.000000,0.000000) [0.000000|15.000000] "" Motor_BEV
 SG_ WH_Status_Shiftlock  : 48|3@1+ (1.000000,0.000000) [0.000000|7.000000] "" Motor_BEV
 SG_ WH_Zustand_N_Haltephase  : 51|2@1+ (1.000000,0.000000) [0.000000|3.000000] "" Vector__XXX

BO_ 2463978687 Waehlhebel_06: 8 ICAS1_Gateway
 SG_ WH_Fehler_Haltemagnet_Status  : 41|1@1+ (1.000000,0.000000) [0.000000|1.000000] "" Motor_BEV
 SG_ WH_Fehler_CRC_SBM  : 42|1@1+ (1.000000,0.000000) [0.000000|1.000000] "" Motor_BEV
 SG_ WH_Fehler_CRC_SBM_Status  : 43|1@1+ (1.000000,0.000000) [0.000000|1.000000] "" Motor_BEV
 SG_ WH_Fehler_Timeout_SBM  : 44|1@1+ (1.000000,0.000000) [0.000000|1.000000] "" Motor_BEV
 SG_ WH_Fehler_Timeout_SBM_Status  : 45|1@1+ (1.000000,0.000000) [0.000000|1.000000] "" Motor_BEV
 SG_ WH_Fehler_Ueberspannung  : 46|1@1+ (1.000000,0.000000) [0.000000|1.000000] "" Motor_BEV
 SG_ WH_Fehler_Ueberspannung_Status  : 47|1@1+ (1.000000,0.000000) [0.000000|1.000000] "" Motor_BEV
 SG_ WH_Fehler_BZ_SBM  : 48|1@1+ (1.000000,0.000000) [0.000000|1.000000] "" Motor_BEV
 SG_ WH_Fehler_BZ_SBM_Status  : 49|1@1+ (1.000000,0.000000) [0.000000|1.000000] "" Motor_BEV
 SG_ WH_Fehler_Unterspannung  : 50|1@1+ (1.000000,0.000000) [0.000000|1.000000] "" Motor_BEV
 SG_ WH_Fehler_Unterspannung_Status  : 51|1@1+ (1.000000,0.000000) [0.000000|1.000000] "" Motor_BEV
 SG_ WH_Fehler_Ausleuchtung  : 52|1@1+ (1.000000,0.000000) [0.000000|1.000000] "" Motor_BEV
 SG_ WH_Fehler_Ausleuchtung_Status  : 53|1@1+ (1.000000,0.000000) [0.000000|1.000000] "" Motor_BEV
 SG_ WH_Fehler_Entsperrtaste  : 54|1@1+ (1.000000,0.000000) [0.000000|1.000000] "" Motor_BEV
 SG_ WH_Fehler_Entsperrtaste_Status  : 55|1@1+ (1.000000,0.000000) [0.000000|1.000000] "" Motor_BEV
 SG_ WH_Fehler_P_Taste  : 56|1@1+ (1.000000,0.000000) [0.000000|1.000000] "" Motor_BEV
 SG_ WH_Fehler_P_Taste_Status  : 57|1@1+ (1.000000,0.000000) [0.000000|1.000000] "" Motor_BEV
 SG_ WH_Fehler_Sensor_einfach  : 58|1@1+ (1.000000,0.000000) [0.000000|1.000000] "" Motor_BEV
 SG_ WH_Fehler_Sensor_einfach_Status  : 59|1@1+ (1.000000,0.000000) [0.000000|1.000000] "" Motor_BEV
 SG_ WH_Fehler_Sensor_mehrfach  : 60|1@1+ (1.000000,0.000000) [0.000000|1.000000] "" Motor_BEV
 SG_ WH_Fehler_Sensor_mehrfach_Status  : 61|1@1+ (1.000000,0.000000) [0.000000|1.000000] "" Motor_BEV
 SG_ WH_Fehler_Shiftlock  : 62|1@1+ (1.000000,0.000000) [0.000000|1.000000] "" Motor_BEV
 SG_ WH_Fehler_Shiftlock_Status  : 63|1@1+ (1.000000,0.000000) [0.000000|1.000000] "" Motor_BEV

BO_ 916 WBA_03: 8 Motor_BEV
 SG_ WBA_03_CRC  : 0|8@1+ (1.000000,0.000000) [0.000000|255.000000] "" ICAS1_Gateway
 SG_ WBA_03_BZ  : 8|4@1+ (1.000000,0.000000) [0.000000|15.000000] "" ICAS1_Gateway
 SG_ WBA_Fahrstufe_02  : 12|4@1+ (1.000000,0.000000) [0.000000|15.000000] "" ICAS1_Gateway ICAS1_KommunikationsServer
 SG_ WBA_ZielFahrstufe  : 16|4@1+ (1.000000,0.000000) [0.000000|15.000000] "" ICAS1_Gateway
 SG_ WBA_GE_Warnung_02  : 20|4@1+ (1.000000,0.000000) [0.000000|15.000000] "" ICAS1_Gateway
 SG_ WBA_eing_Gang_02  : 24|4@1+ (1.000000,0.000000) [0.000000|15.000000] "" ICAS1_Gateway
 SG_ WBA_GE_Texte  : 28|3@1+ (1.000000,0.000000) [0.000000|7.000000] "" ICAS1_Gateway
 SG_ WBA_Segeln_aktiv  : 31|1@1+ (1.000000,0.000000) [0.000000|1.000000] "" ICAS1_Gateway
 SG_ WBA_Schaltschema_02  : 32|3@1+ (1.000000,0.000000) [0.000000|7.000000] "" ICAS1_Gateway
 SG_ WBA_Schaltschema_FS_inaktiv  : 35|2@1+ (1.000000,0.000000) [0.000000|3.000000] "" ICAS1_Gateway
 SG_ WBA_GE_Zusatzwarnungen  : 37|3@1+ (1.000000,0.000000) [0.000000|7.000000] "" ICAS1_Gateway
 SG_ GE_Sollgang  : 40|4@1+ (1.000000,0.000000) [0.000000|15.000000] "" ICAS1_Gateway
 SG_ GE_Tipschaltempf_verfuegbar  : 44|1@1+ (1.000000,0.000000) [0.000000|1.000000] "" ICAS1_Gateway
 SG_ WBA_GE_Texte_02  : 45|3@1+ (1.000000,0.000000) [0.000000|7.000000] "" ICAS1_Gateway
 SG_ WBA_Schaltschema_Tippgasse  : 48|1@1+ (1.000000,0.000000) [0.000000|1.000000] "" ICAS1_Gateway
 SG_ WBA_Schaltschema_Fahreraktion  : 49|1@1+ (1.000000,0.000000) [0.000000|1.000000] "" ICAS1_Gateway
 SG_ WBA_Schaltschema_FS_vorwaerts  : 50|2@1+ (1.000000,0.000000) [0.000000|3.000000] "" ICAS1_Gateway
 SG_ WBA_Shiftlock_Lampe  : 52|1@1+ (1.000000,0.000000) [0.000000|1.000000] "" ICAS1_Gateway
 SG_ WBA_Anforderung_Akustik  : 53|1@1+ (1.000000,0.000000) [0.000000|1.000000] "" ICAS1_Gateway
 SG_ WBA_Blinken  : 54|1@1+ (1.000000,0.000000) [0.000000|1.000000] "" ICAS1_Gateway
 SG_ GE_Wiederstart_Anz_Std  : 55|1@1+ (1.000000,0.000000) [0.000000|1.000000] "" ICAS1_Gateway
 SG_ GE_Stoppverbot_Anz_01  : 56|1@1+ (1.000000,0.000000) [0.000000|1.000000] "" ICAS1_Gateway
 SG_ GE_Stoppverbot_Anz_02  : 57|1@1+ (1.000000,0.000000) [0.000000|1.000000] "" ICAS1_Gateway
 SG_ GE_Stoppverbot_Anz_03  : 58|1@1+ (1.000000,0.000000) [0.000000|1.000000] "" ICAS1_Gateway
 SG_ GE_Stoppverbot_Anz_04  : 59|1@1+ (1.000000,0.000000) [0.000000|1.000000] "" ICAS1_Gateway
 SG_ GE_Stoppverbot_Anz_05  : 60|1@1+ (1.000000,0.000000) [0.000000|1.000000] "" ICAS1_Gateway
 SG_ GE_Stoppverbot_Anz_06  : 61|1@1+ (1.000000,0.000000) [0.000000|1.000000] "" ICAS1_Gateway
 SG_ GE_Stoppverbot_Anz_07  : 62|1@1+ (1.000000,0.000000) [0.000000|1.000000] "" ICAS1_Gateway
 SG_ GE_Stoppverbot_Anz_Std  : 63|1@1+ (1.000000,0.000000) [0.000000|1.000000] "" ICAS1_Gateway

BO_ 1361 WFS_01: 8 ICAS1_Gateway
 SG_ WFS_Schluessel_Fahrberecht  : 0|4@1+ (1.000000,0.000000) [0.000000|15.000000] "" Vector__XXX
 SG_ WFS_Verbauinfo_ELV  : 4|1@1+ (1.000000,0.000000) [0.000000|1.000000] "" Vector__XXX
 SG_ WFS_ID_Geb_autorisiert  : 5|1@1+ (1.000000,0.000000) [0.000000|1.000000] "" Vector__XXX
 SG_ WFS_ID_Geb_autorisiert_in_Kl15  : 6|1@1+ (1.000000,0.000000) [0.000000|1.000000] "" Vector__XXX
 SG_ WFS_ID_Geb_steckt  : 7|1@1+ (1.000000,0.000000) [0.000000|1.000000] "" Vector__XXX
 SG_ WFS_Schluessel_Soll  : 8|4@1+ (1.000000,0.000000) [0.000000|15.000000] "" Vector__XXX
 SG_ WFS_Schluessel_Ist  : 12|4@1+ (1.000000,0.000000) [0.000000|15.000000] "" Vector__XXX
 SG_ WFS_Safe  : 16|1@1+ (1.000000,0.000000) [0.000000|1.000000] "" Vector__XXX
 SG_ WFS_LZ  : 17|2@1+ (1.000000,0.000000) [0.000000|3.000000] "" Vector__XXX
 SG_ WFS_ELV_authorisiert  : 19|1@1+ (1.000000,0.000000) [0.000000|1.000000] "" Vector__XXX
 SG_ WFS_LF_Aktiv  : 20|1@1+ (1.000000,0.000000) [0.000000|1.000000] "" Vector__XXX
 SG_ WFS_Betrieb_Lesespule  : 21|1@1+ (1.000000,0.000000) [0.000000|1.000000] "" Vector__XXX
 SG_ WFS_Klemmenfreigabe  : 22|1@1+ (1.000000,0.000000) [0.000000|1.000000] "" Motor_BEV
 SG_ WFS_Klemmenfreigabe_Signatur  : 23|11@1+ (1.000000,0.000000) [0.000000|2047.000000] "" Vector__XXX
 SG_ WFS_Fahrerhinweise  : 34|2@1+ (1.000000,0.000000) [0.000000|3.000000] "" Vector__XXX
 SG_ WFS_Parken_Status  : 36|2@1+ (1.000000,0.000000) [0.000000|3.000000] "" Vector__XXX

BO_ 2617028096 XCP_Airbag_CRO_01: 64 Vector__XXX
 SG_ XCP_Airbag_CRO_01_Data  : 0|512@1+ (1.000000,0.000000) [0.000000|13407807929942597099574024998205846127479365820592393377723561443721764030073546976801874298166903427690031858186486050853753882811946569946433649006084096.000000] "" Airbag

BO_ 2617028097 XCP_Airbag_DTO_01: 64 Airbag
 SG_ XCP_Airbag_DTO_01_Data  : 0|512@1+ (1.000000,0.000000) [0.000000|13407807929942597099574024998205846127479365820592393377723561443721764030073546976801874298166903427690031858186486050853753882811946569946433649006084096.000000] "" Vector__XXX

BO_ 2617239040 XCP_EMotor_01_CRO_01: 64 Vector__XXX
 SG_ XCP_EMotor_01_CRO_01_Data  : 0|64@1+ (1.000000,0.000000) [0.000000|18446744073709551616.000000] "" LE1

BO_ 2617239041 XCP_EMotor_01_DTO_01: 64 LE1
 SG_ XCP_EMotor_01_DTO_01_Data  : 0|64@1+ (1.000000,0.000000) [0.000000|18446744073709551616.000000] "" Vector__XXX

BO_ 2617239042 XCP_EMotor_01_DTO_02: 64 LE1
 SG_ XCP_EMotor_01_DTO_02_Data  : 0|64@1+ (1.000000,0.000000) [0.000000|18446744073709551616.000000] "" Vector__XXX

BO_ 2617239043 XCP_EMotor_01_DTO_03: 64 LE1
 SG_ XCP_EMotor_01_DTO_03_Data  : 0|64@1+ (1.000000,0.000000) [0.000000|18446744073709551616.000000] "" Vector__XXX

BO_ 2617239044 XCP_EMotor_01_DTO_04: 64 LE1
 SG_ XCP_EMotor_01_DTO_04_Data  : 0|64@1+ (1.000000,0.000000) [0.000000|18446744073709551616.000000] "" Vector__XXX

BO_ 2617122304 XCP_EMotor_02_CRO_01: 64 Vector__XXX
 SG_ XCP_EMotor_02_CRO_01_Data  : 0|64@1+ (1.000000,0.000000) [0.000000|18446744073709551616.000000] "" LE2

BO_ 2617122305 XCP_EMotor_02_DTO_01: 64 LE2
 SG_ XCP_EMotor_02_DTO_01_Data  : 0|64@1+ (1.000000,0.000000) [0.000000|18446744073709551616.000000] "" Vector__XXX

BO_ 2617122306 XCP_EMotor_02_DTO_02: 64 LE2
 SG_ XCP_EMotor_02_DTO_02_Data  : 0|64@1+ (1.000000,0.000000) [0.000000|18446744073709551616.000000] "" Vector__XXX

BO_ 2617122307 XCP_EMotor_02_DTO_03: 64 LE2
 SG_ XCP_EMotor_02_DTO_03_Data  : 0|64@1+ (1.000000,0.000000) [0.000000|18446744073709551616.000000] "" Vector__XXX

BO_ 2617122308 XCP_EMotor_02_DTO_04: 64 LE2
 SG_ XCP_EMotor_02_DTO_04_Data  : 0|64@1+ (1.000000,0.000000) [0.000000|18446744073709551616.000000] "" Vector__XXX

BO_ 2617226768 XCP_Motor_CRO_01: 64 Vector__XXX
 SG_ XCP_Motor_CRO_01_Data  : 0|64@1+ (1.000000,0.000000) [0.000000|18446744073709551616.000000] "" Motor_BEV

BO_ 2617226769 XCP_Motor_DTO_01: 64 Motor_BEV
 SG_ XCP_Motor_DTO_01_Data  : 0|64@1+ (1.000000,0.000000) [0.000000|18446744073709551616.000000] "" Vector__XXX

BO_ 1411 ZV_02: 8 ICAS1_Gateway
 SG_ ZV_verriegeln_Anf  : 0|1@1+ (1.000000,0.000000) [0.000000|1.000000] "" Vector__XXX
 SG_ ZV_STSG_HFS_Anf  : 1|1@1+ (1.000000,0.000000) [0.000000|1.000000] "" Vector__XXX
 SG_ ZV_STSG_HBFS_Anf  : 2|1@1+ (1.000000,0.000000) [0.000000|1.000000] "" Vector__XXX
 SG_ ZV_Anf_Challenge_Auth  : 3|1@1+ (1.000000,0.000000) [0.000000|1.000000] "" Vector__XXX
 SG_ BCM_FH_Freigabe  : 12|1@1+ (1.000000,0.000000) [0.000000|1.000000] "" Vector__XXX
 SG_ BCM_Komfortfkt_Freigabe  : 13|1@1+ (1.000000,0.000000) [0.000000|1.000000] "" Vector__XXX
 SG_ BCM_HSK_Freigabe  : 14|1@1+ (1.000000,0.000000) [0.000000|1.000000] "" Vector__XXX
 SG_ BCM_Verdeck_Freigabe  : 15|1@1+ (1.000000,0.000000) [0.000000|1.000000] "" Vector__XXX
 SG_ ZV_verriegelt_intern_ist  : 16|1@1+ (1.000000,0.000000) [0.000000|1.000000] "" Vector__XXX
 SG_ ZV_verriegelt_extern_ist  : 17|1@1+ (1.000000,0.000000) [0.000000|1.000000] "" Airbag
 SG_ ZV_verriegelt_intern_soll  : 18|1@1+ (1.000000,0.000000) [0.000000|1.000000] "" Vector__XXX
 SG_ ZV_verriegelt_extern_soll  : 19|1@1+ (1.000000,0.000000) [0.000000|1.000000] "" Airbag
 SG_ ZV_gesafet_extern_ist  : 20|1@1+ (1.000000,0.000000) [0.000000|1.000000] "" Vector__XXX
 SG_ ZV_gesafet_extern_soll  : 21|1@1+ (1.000000,0.000000) [0.000000|1.000000] "" Vector__XXX
 SG_ ZV_Einzeltuerentriegelung  : 22|1@1+ (1.000000,0.000000) [0.000000|1.000000] "" Vector__XXX
 SG_ ZV_Heckeinzelentriegelung  : 23|1@1+ (1.000000,0.000000) [0.000000|1.000000] "" Vector__XXX
 SG_ ZV_FT_offen  : 24|1@1+ (1.000000,0.000000) [0.000000|1.000000] "" Motor_BEV
 SG_ ZV_BT_offen  : 25|1@1+ (1.000000,0.000000) [0.000000|1.000000] "" Motor_BEV
 SG_ ZV_HFS_offen  : 26|1@1+ (1.000000,0.000000) [0.000000|1.000000] "" Motor_BEV
 SG_ ZV_HBFS_offen  : 27|1@1+ (1.000000,0.000000) [0.000000|1.000000] "" Motor_BEV
 SG_ ZV_HD_offen  : 28|1@1+ (1.000000,0.000000) [0.000000|1.000000] "" Motor_BEV
 SG_ ZV_HS_offen  : 29|1@1+ (1.000000,0.000000) [0.000000|1.000000] "" Vector__XXX
 SG_ IRUE_aktiv  : 30|1@1+ (1.000000,0.000000) [0.000000|1.000000] "" Vector__XXX
 SG_ DWA_aktiv  : 31|1@1+ (1.000000,0.000000) [0.000000|1.000000] "" Vector__XXX
 SG_ FFB_HDF_Taste  : 34|1@1+ (1.000000,0.000000) [0.000000|1.000000] "" Vector__XXX
 SG_ FFB_Panik_Taste  : 35|1@1+ (1.000000,0.000000) [0.000000|1.000000] "" Vector__XXX
 SG_ FFB_Auf_Taste  : 36|1@1+ (1.000000,0.000000) [0.000000|1.000000] "" Vector__XXX
 SG_ FFB_Zu_Taste  : 37|1@1+ (1.000000,0.000000) [0.000000|1.000000] "" Vector__XXX
 SG_ FFB_CarFinder  : 38|1@1+ (1.000000,0.000000) [0.000000|1.000000] "" Vector__XXX
 SG_ FFB_Komfortoeffnen  : 39|1@1+ (1.000000,0.000000) [0.000000|1.000000] "" Vector__XXX
 SG_ FFB_Komfortschliessen  : 40|1@1+ (1.000000,0.000000) [0.000000|1.000000] "" Vector__XXX
 SG_ FBS_IDG_in_Reichweite  : 41|1@1+ (1.000000,0.000000) [0.000000|1.000000] "" Vector__XXX
 SG_ ZV_Schluessel_Zugang  : 42|4@1+ (1.000000,0.000000) [0.000000|15.000000] "" Vector__XXX
 SG_ ZV_SafeFunktion_aktiv  : 46|1@1+ (1.000000,0.000000) [0.000000|1.000000] "" Vector__XXX
 SG_ FBS_Warn_Schluessel_Batt  : 47|1@1+ (1.000000,0.000000) [0.000000|1.000000] "" Vector__XXX
 SG_ ZV_Oeffnungsmodus  : 48|2@1+ (1.000000,0.000000) [0.000000|3.000000] "" Vector__XXX
 SG_ ZV_ist_Zustand_verfuegbar  : 54|1@1+ (1.000000,0.000000) [0.000000|1.000000] "" Vector__XXX
 SG_ IRUE_Taster_Fkts_LED  : 55|1@1+ (1.000000,0.000000) [0.000000|1.000000] "" Vector__XXX
 SG_ ZV_Tankklappe_offen  : 56|1@1+ (1.000000,0.000000) [0.000000|1.000000] "" Vector__XXX
 SG_ ZV_Rollo_auf  : 57|1@1+ (1.000000,0.000000) [0.000000|1.000000] "" Vector__XXX
 SG_ ZV_Rollo_zu  : 58|1@1+ (1.000000,0.000000) [0.000000|1.000000] "" Vector__XXX
 SG_ ZV_SAD_auf  : 59|1@1+ (1.000000,0.000000) [0.000000|1.000000] "" Vector__XXX
 SG_ ZV_SAD_zu  : 60|1@1+ (1.000000,0.000000) [0.000000|1.000000] "" Vector__XXX
 SG_ ZV_verriegelt_soll  : 62|2@1+ (1.000000,0.000000) [0.000000|3.000000] "" Vector__XXX

BU_:  Airbag BAP_Tester ICAS1_Gateway ICAS1_KommunikationsServer LE1 LE2 Motor_BEV Schaltbetaetigung

BO_ 2463978663 VZE_04: 32 ICAS1_Gateway
 SG_ VZE_Anzeigemodus  : 0|2@1+ (1.000000,0.000000) [0.000000|3.000000] "" Vector__XXX
 SG_ VZE_Hinweistext  : 2|3@1+ (1.000000,0.000000) [1.000000|7.000000] "" Motor_BEV
 SG_ VZE_Verkehrszeichen_Einheit  : 8|1@1+ (1.000000,0.000000) [0.000000|1.000000] "" Vector__XXX
 SG_ VZE_Anzeigeunterdrueck_Zeichen_3  : 9|1@1+ (1.000000,0.000000) [0.000000|1.000000] "" Vector__XXX
 SG_ VZE_Anzeigeunterdrueck_Zeichen_2  : 10|1@1+ (1.000000,0.000000) [0.000000|1.000000] "" Vector__XXX
 SG_ VZE_Verkehrszeichen_1  : 11|8@1+ (1.000000,0.000000) [1.000000|255.000000] "" Motor_BEV
 SG_ VZE_Verkehrszeichen_2  : 19|8@1+ (1.000000,0.000000) [1.000000|255.000000] "" Vector__XXX
 SG_ VZE_Verkehrszeichen_3  : 27|8@1+ (1.000000,0.000000) [1.000000|255.000000] "" Vector__XXX
 SG_ VZE_Warnung_Verkehrszeichen_1  : 35|1@1+ (1.000000,0.000000) [0.000000|1.000000] "" Vector__XXX
 SG_ VZE_Warnung_Verkehrszeichen_2  : 36|1@1+ (1.000000,0.000000) [0.000000|1.000000] "" Vector__XXX
 SG_ VZE_Warnung_Verkehrszeichen_3  : 37|1@1+ (1.000000,0.000000) [0.000000|1.000000] "" Vector__XXX
 SG_ VZE_Zusatzschild_1  : 38|4@1+ (1.000000,0.000000) [1.000000|15.000000] "" Vector__XXX
 SG_ VZE_Zusatzschild_2  : 42|4@1+ (1.000000,0.000000) [1.000000|15.000000] "" Vector__XXX
 SG_ VZE_Zusatzschild_3  : 46|4@1+ (1.000000,0.000000) [1.000000|15.000000] "" Vector__XXX
 SG_ VZE_Anzeigeunterdrueck_Zeichen_1  : 50|1@1+ (1.000000,0.000000) [0.000000|1.000000] "" Vector__XXX
 SG_ VZE_Zeichen_01_KameraWied  : 51|1@1+ (1.000000,0.000000) [0.000000|1.000000] "" Motor_BEV
 SG_ VZE_Zeichen_02_KameraWied  : 52|1@1+ (1.000000,0.000000) [0.000000|1.000000] "" Vector__XXX
 SG_ VZE_Zeichen_03_KameraWied  : 53|1@1+ (1.000000,0.000000) [0.000000|1.000000] "" Vector__XXX
 SG_ VZE_Zeichen_01_Kamera  : 54|1@1+ (1.000000,0.000000) [0.000000|1.000000] "" Motor_BEV
 SG_ VZE_Zeichen_01_Karte  : 55|1@1+ (1.000000,0.000000) [0.000000|1.000000] "" Vector__XXX
 SG_ VZE_Zeichen_01_Gesetz  : 56|1@1+ (1.000000,0.000000) [0.000000|1.000000] "" Vector__XXX
 SG_ VZE_Zeichen_02_Kamera  : 57|1@1+ (1.000000,0.000000) [0.000000|1.000000] "" Vector__XXX
 SG_ VZE_Zeichen_02_Karte  : 58|1@1+ (1.000000,0.000000) [0.000000|1.000000] "" Vector__XXX
 SG_ VZE_Zeichen_02_Gesetz  : 59|1@1+ (1.000000,0.000000) [0.000000|1.000000] "" Vector__XXX
 SG_ VZE_Zeichen_03_Kamera  : 60|1@1+ (1.000000,0.000000) [0.000000|1.000000] "" Vector__XXX
 SG_ VZE_Zeichen_03_Karte  : 61|1@1+ (1.000000,0.000000) [0.000000|1.000000] "" Vector__XXX
 SG_ VZE_Zeichen_03_Gesetz  : 62|1@1+ (1.000000,0.000000) [0.000000|1.000000] "" Vector__XXX
 SG_ VZE_Gong  : 63|1@1+ (1.000000,0.000000) [0.000000|1.000000] "" Vector__XXX
 SG_ VZE_Anzeigeunterdrueck_Zeichen_5  : 72|1@1+ (1.000000,0.000000) [0.000000|1.000000] "" Vector__XXX
 SG_ VZE_Zeichen_05_KameraWied  : 73|1@1+ (1.000000,0.000000) [0.000000|1.000000] "" Vector__XXX
 SG_ VZE_Zeichen_05_Kamera  : 74|1@1+ (1.000000,0.000000) [0.000000|1.000000] "" Vector__XXX
 SG_ VZE_Verkehrszeichen_4  : 75|8@1+ (1.000000,0.000000) [1.000000|255.000000] "" Motor_BEV
 SG_ VZE_Verkehrszeichen_5  : 83|8@1+ (1.000000,0.000000) [1.000000|255.000000] "" Motor_BEV
 SG_ VZE_Anhaenger_Vmax  : 91|4@1+ (10.000000,10.000000) [10.000000|140.000000] "Unit_KiloMeterPerHour" Vector__XXX
 SG_ VZE_Zeichen_04_Gesetz  : 95|1@1+ (1.000000,0.000000) [0.000000|1.000000] "" Vector__XXX
 SG_ VZE_Zeichen_04_Kamera  : 96|1@1+ (1.000000,0.000000) [0.000000|1.000000] "" Vector__XXX
 SG_ VZE_Zeichen_04_KameraWied  : 97|1@1+ (1.000000,0.000000) [0.000000|1.000000] "" Vector__XXX
 SG_ VZE_Zeichen_04_Karte  : 98|1@1+ (1.000000,0.000000) [0.000000|1.000000] "" Vector__XXX
 SG_ VZE_Warnung_Verkehrszeichen_4  : 99|1@1+ (1.000000,0.000000) [0.000000|1.000000] "" Vector__XXX
 SG_ VZE_Warnung_Verkehrszeichen_5  : 100|1@1+ (1.000000,0.000000) [0.000000|1.000000] "" Vector__XXX
 SG_ VZE_Zeichen_05_Gesetz  : 101|1@1+ (1.000000,0.000000) [0.000000|1.000000] "" Vector__XXX
 SG_ VZE_Zusatzschild_4  : 102|4@1+ (1.000000,0.000000) [1.000000|15.000000] "" Vector__XXX
 SG_ VZE_Zusatzschild_5  : 106|4@1+ (1.000000,0.000000) [1.000000|15.000000] "" Vector__XXX
 SG_ VZE_Baustelle  : 110|2@1+ (1.000000,0.000000) [0.000000|3.000000] "" Vector__XXX
 SG_ VZE_Zeichen_05_Karte  : 112|1@1+ (1.000000,0.000000) [0.000000|1.000000] "" Vector__XXX
 SG_ VZE_Zeichen_05_Entfernung  : 113|7@1+ (1.000000,0.000000) [1.000000|127.000000] "Unit_Meter" Motor_BEV
 SG_ VZE_Zeichen_05_Entfernung_StdA  : 120|7@1+ (1.000000,0.000000) [1.000000|127.000000] "Unit_Meter" Motor_BEV
 SG_ VZE_Anzeigeunterdrueck_Zeichen_4  : 127|1@1+ (1.000000,0.000000) [0.000000|1.000000] "" Vector__XXX
 SG_ VZE_Verkehrszeichen_6  : 128|8@1+ (1.000000,0.000000) [1.000000|255.000000] "Unit_None" Motor_BEV
 SG_ VZE_Zusatzschild_6  : 136|4@1+ (1.000000,0.000000) [1.000000|15.000000] "" Vector__XXX
 SG_ VZE_Zeichen_06_Entfernung  : 140|7@1+ (1.000000,0.000000) [1.000000|127.000000] "Unit_Meter" Motor_BEV
 SG_ VZE_Zeichen_06_Entfernung_StdA  : 147|7@1+ (1.000000,0.000000) [1.000000|127.000000] "Unit_Meter" Motor_BEV
 SG_ VZE_Umweltinfo_Naesse  : 154|1@1+ (1.000000,0.000000) [0.000000|1.000000] "" Motor_BEV
 SG_ VZE_Umweltinfo_Nebel  : 155|1@1+ (1.000000,0.000000) [0.000000|1.000000] "" Motor_BEV
 SG_ VZE_Umweltinfo_Anhaengerbetrieb  : 156|1@1+ (1.000000,0.000000) [0.000000|1.000000] "" Vector__XXX
 SG_ VZE_Erweiterte_Information  : 157|8@1+ (1.000000,0.000000) [1.000000|255.000000] "Unit_None" Vector__XXX
 SG_ VZE_Tempowarnung_Status  : 165|1@1+ (1.000000,0.000000) [0.000000|1.000000] "" Vector__XXX
 SG_ VZE_Tempowarnung_Einheit  : 166|1@1+ (1.000000,0.000000) [0.000000|1.000000] "" Vector__XXX
 SG_ VZE_Tempowarnung_Offset  : 167|5@1+ (1.000000,0.000000) [1.000000|31.000000] "" Vector__XXX
 SG_ VZE_FoD_Status  : 206|2@1+ (1.000000,0.000000) [0.000000|3.000000] "" Vector__XXX
 SG_ VZE_Anzeige_ZS_1  : 208|4@1+ (1.000000,0.000000) [1.000000|15.000000] "Unit_None" Vector__XXX
 SG_ VZE_Anzeige_ZS_2  : 212|4@1+ (1.000000,0.000000) [1.000000|15.000000] "Unit_None" Vector__XXX
 SG_ VZE_Anzeige_ZS_3  : 216|4@1+ (1.000000,0.000000) [1.000000|15.000000] "Unit_None" Vector__XXX
 SG_ VZE_Hinweistext_03  : 220|4@1+ (1.000000,0.000000) [1.000000|15.000000] "" Vector__XXX
 SG_ VZE_Land  : 224|5@1+ (1.000000,0.000000) [1.000000|31.000000] "" Vector__XXX
 SG_ VZE_Warnung_VZ_1  : 229|1@1+ (1.000000,0.000000) [0.000000|1.000000] "" Vector__XXX
 SG_ VZE_Warnung_VZ_2  : 230|1@1+ (1.000000,0.000000) [0.000000|1.000000] "" Vector__XXX
 SG_ VZE_Warnung_VZ_3  : 231|1@1+ (1.000000,0.000000) [0.000000|1.000000] "" Vector__XXX
 SG_ VZE_Anzeige_VZ_1  : 232|8@1+ (1.000000,0.000000) [1.000000|255.000000] "" Vector__XXX
 SG_ VZE_Anzeige_VZ_2  : 240|8@1+ (1.000000,0.000000) [1.000000|255.000000] "Unit_None" Vector__XXX
 SG_ VZE_Anzeige_VZ_3  : 248|8@1+ (1.000000,0.000000) [1.000000|255.000000] "Unit_None" Vector__XXX

BO_ 181 Waehlhebel_04: 8 ICAS1_Gateway
 SG_ Waehlhebel_04_CRC  : 0|8@1+ (1.000000,0.000000) [0.000000|255.000000] "" Motor_BEV
 SG_ Waehlhebel_04_BZ  : 8|4@1+ (1.000000,0.000000) [0.000000|15.000000] "" Motor_BEV
 SG_ WH_gespeicherte_Fahrstufe  : 12|3@1+ (1.000000,0.000000) [0.000000|7.000000] "" Vector__XXX
 SG_ WH_Initialisierung  : 15|1@1+ (1.000000,0.000000) [0.000000|1.000000] "" Motor_BEV
 SG_ WH_SensorPos_roh  : 16|4@1+ (1.000000,0.000000) [0.000000|15.000000] "" Motor_BEV
 SG_ WH_SensorPos_roh_inv  : 20|4@1+ (1.000000,0.000000) [0.000000|15.000000] "" Motor_BEV
 SG_ WH_Testergebnis  : 24|8@1+ (1.000000,0.000000) [0.000000|255.000000] "" Vector__XXX
 SG_ WH_Test_Aktiv  : 32|1@1+ (1.000000,0.000000) [0.000000|1.000000] "" Vector__XXX
 SG_ WH_Ist_Haltemagnet  : 33|2@1+ (1.000000,0.000000) [0.000000|3.000000] "" Motor_BEV
 SG_ WH_Variante  : 35|4@1+ (1.000000,0.000000) [0.000000|15.000000] "" Motor_BEV
 SG_ WH_Entsperrtaste_02  : 39|2@1+ (1.000000,0.000000) [0.000000|3.000000] "" Motor_BEV
 SG_ WH_P_Taste  : 41|2@1+ (1.000000,0.000000) [0.000000|3.000000] "" Motor_BEV
 SG_ WH_Ende_N_Haltephase  : 43|1@1+ (1.000000,0.000000) [0.000000|1.000000] "" Vector__XXX
 SG_ WH_Fahrstufe  : 44|4@1+ (1.000000,0.000000) [0.000000|15.000000] "" Motor_BEV
 SG_ WH_Status_Shiftlock  : 48|3@1+ (1.000000,0.000000) [0.000000|7.000000] "" Motor_BEV
 SG_ WH_Zustand_N_Haltephase  : 51|2@1+ (1.000000,0.000000) [0.000000|3.000000] "" Vector__XXX

BO_ 2463978687 Waehlhebel_06: 8 ICAS1_Gateway
 SG_ WH_Fehler_Haltemagnet_Status  : 41|1@1+ (1.000000,0.000000) [0.000000|1.000000] "" Motor_BEV
 SG_ WH_Fehler_CRC_SBM  : 42|1@1+ (1.000000,0.000000) [0.000000|1.000000] "" Motor_BEV
 SG_ WH_Fehler_CRC_SBM_Status  : 43|1@1+ (1.000000,0.000000) [0.000000|1.000000] "" Motor_BEV
 SG_ WH_Fehler_Timeout_SBM  : 44|1@1+ (1.000000,0.000000) [0.000000|1.000000] "" Motor_BEV
 SG_ WH_Fehler_Timeout_SBM_Status  : 45|1@1+ (1.000000,0.000000) [0.000000|1.000000] "" Motor_BEV
 SG_ WH_Fehler_Ueberspannung  : 46|1@1+ (1.000000,0.000000) [0.000000|1.000000] "" Motor_BEV
 SG_ WH_Fehler_Ueberspannung_Status  : 47|1@1+ (1.000000,0.000000) [0.000000|1.000000] "" Motor_BEV
 SG_ WH_Fehler_BZ_SBM  : 48|1@1+ (1.000000,0.000000) [0.000000|1.000000] "" Motor_BEV
 SG_ WH_Fehler_BZ_SBM_Status  : 49|1@1+ (1.000000,0.000000) [0.000000|1.000000] "" Motor_BEV
 SG_ WH_Fehler_Unterspannung  : 50|1@1+ (1.000000,0.000000) [0.000000|1.000000] "" Motor_BEV
 SG_ WH_Fehler_Unterspannung_Status  : 51|1@1+ (1.000000,0.000000) [0.000000|1.000000] "" Motor_BEV
 SG_ WH_Fehler_Ausleuchtung  : 52|1@1+ (1.000000,0.000000) [0.000000|1.000000] "" Motor_BEV
 SG_ WH_Fehler_Ausleuchtung_Status  : 53|1@1+ (1.000000,0.000000) [0.000000|1.000000] "" Motor_BEV
 SG_ WH_Fehler_Entsperrtaste  : 54|1@1+ (1.000000,0.000000) [0.000000|1.000000] "" Motor_BEV
 SG_ WH_Fehler_Entsperrtaste_Status  : 55|1@1+ (1.000000,0.000000) [0.000000|1.000000] "" Motor_BEV
 SG_ WH_Fehler_P_Taste  : 56|1@1+ (1.000000,0.000000) [0.000000|1.000000] "" Motor_BEV
 SG_ WH_Fehler_P_Taste_Status  : 57|1@1+ (1.000000,0.000000) [0.000000|1.000000] "" Motor_BEV
 SG_ WH_Fehler_Sensor_einfach  : 58|1@1+ (1.000000,0.000000) [0.000000|1.000000] "" Motor_BEV
 SG_ WH_Fehler_Sensor_einfach_Status  : 59|1@1+ (1.000000,0.000000) [0.000000|1.000000] "" Motor_BEV
 SG_ WH_Fehler_Sensor_mehrfach  : 60|1@1+ (1.000000,0.000000) [0.000000|1.000000] "" Motor_BEV
 SG_ WH_Fehler_Sensor_mehrfach_Status  : 61|1@1+ (1.000000,0.000000) [0.000000|1.000000] "" Motor_BEV
 SG_ WH_Fehler_Shiftlock  : 62|1@1+ (1.000000,0.000000) [0.000000|1.000000] "" Motor_BEV
 SG_ WH_Fehler_Shiftlock_Status  : 63|1@1+ (1.000000,0.000000) [0.000000|1.000000] "" Motor_BEV

BO_ 916 WBA_03: 8 Motor_BEV
 SG_ WBA_03_CRC  : 0|8@1+ (1.000000,0.000000) [0.000000|255.000000] "" ICAS1_Gateway
 SG_ WBA_03_BZ  : 8|4@1+ (1.000000,0.000000) [0.000000|15.000000] "" ICAS1_Gateway
 SG_ WBA_Fahrstufe_02  : 12|4@1+ (1.000000,0.000000) [0.000000|15.000000] "" ICAS1_Gateway ICAS1_KommunikationsServer
 SG_ WBA_ZielFahrstufe  : 16|4@1+ (1.000000,0.000000) [0.000000|15.000000] "" ICAS1_Gateway
 SG_ WBA_GE_Warnung_02  : 20|4@1+ (1.000000,0.000000) [0.000000|15.000000] "" ICAS1_Gateway
 SG_ WBA_eing_Gang_02  : 24|4@1+ (1.000000,0.000000) [0.000000|15.000000] "" ICAS1_Gateway
 SG_ WBA_GE_Texte  : 28|3@1+ (1.000000,0.000000) [0.000000|7.000000] "" ICAS1_Gateway
 SG_ WBA_Segeln_aktiv  : 31|1@1+ (1.000000,0.000000) [0.000000|1.000000] "" ICAS1_Gateway
 SG_ WBA_Schaltschema_02  : 32|3@1+ (1.000000,0.000000) [0.000000|7.000000] "" ICAS1_Gateway
 SG_ WBA_Schaltschema_FS_inaktiv  : 35|2@1+ (1.000000,0.000000) [0.000000|3.000000] "" ICAS1_Gateway
 SG_ WBA_GE_Zusatzwarnungen  : 37|3@1+ (1.000000,0.000000) [0.000000|7.000000] "" ICAS1_Gateway
 SG_ GE_Sollgang  : 40|4@1+ (1.000000,0.000000) [0.000000|15.000000] "" ICAS1_Gateway
 SG_ GE_Tipschaltempf_verfuegbar  : 44|1@1+ (1.000000,0.000000) [0.000000|1.000000] "" ICAS1_Gateway
 SG_ WBA_GE_Texte_02  : 45|3@1+ (1.000000,0.000000) [0.000000|7.000000] "" ICAS1_Gateway
 SG_ WBA_Schaltschema_Tippgasse  : 48|1@1+ (1.000000,0.000000) [0.000000|1.000000] "" ICAS1_Gateway
 SG_ WBA_Schaltschema_Fahreraktion  : 49|1@1+ (1.000000,0.000000) [0.000000|1.000000] "" ICAS1_Gateway
 SG_ WBA_Schaltschema_FS_vorwaerts  : 50|2@1+ (1.000000,0.000000) [0.000000|3.000000] "" ICAS1_Gateway
 SG_ WBA_Shiftlock_Lampe  : 52|1@1+ (1.000000,0.000000) [0.000000|1.000000] "" ICAS1_Gateway
 SG_ WBA_Anforderung_Akustik  : 53|1@1+ (1.000000,0.000000) [0.000000|1.000000] "" ICAS1_Gateway
 SG_ WBA_Blinken  : 54|1@1+ (1.000000,0.000000) [0.000000|1.000000] "" ICAS1_Gateway
 SG_ GE_Wiederstart_Anz_Std  : 55|1@1+ (1.000000,0.000000) [0.000000|1.000000] "" ICAS1_Gateway
 SG_ GE_Stoppverbot_Anz_01  : 56|1@1+ (1.000000,0.000000) [0.000000|1.000000] "" ICAS1_Gateway
 SG_ GE_Stoppverbot_Anz_02  : 57|1@1+ (1.000000,0.000000) [0.000000|1.000000] "" ICAS1_Gateway
 SG_ GE_Stoppverbot_Anz_03  : 58|1@1+ (1.000000,0.000000) [0.000000|1.000000] "" ICAS1_Gateway
 SG_ GE_Stoppverbot_Anz_04  : 59|1@1+ (1.000000,0.000000) [0.000000|1.000000] "" ICAS1_Gateway
 SG_ GE_Stoppverbot_Anz_05  : 60|1@1+ (1.000000,0.000000) [0.000000|1.000000] "" ICAS1_Gateway
 SG_ GE_Stoppverbot_Anz_06  : 61|1@1+ (1.000000,0.000000) [0.000000|1.000000] "" ICAS1_Gateway
 SG_ GE_Stoppverbot_Anz_07  : 62|1@1+ (1.000000,0.000000) [0.000000|1.000000] "" ICAS1_Gateway
 SG_ GE_Stoppverbot_Anz_Std  : 63|1@1+ (1.000000,0.000000) [0.000000|1.000000] "" ICAS1_Gateway

BO_ 1361 WFS_01: 8 ICAS1_Gateway
 SG_ WFS_Schluessel_Fahrberecht  : 0|4@1+ (1.000000,0.000000) [0.000000|15.000000] "" Vector__XXX
 SG_ WFS_Verbauinfo_ELV  : 4|1@1+ (1.000000,0.000000) [0.000000|1.000000] "" Vector__XXX
 SG_ WFS_ID_Geb_autorisiert  : 5|1@1+ (1.000000,0.000000) [0.000000|1.000000] "" Vector__XXX
 SG_ WFS_ID_Geb_autorisiert_in_Kl15  : 6|1@1+ (1.000000,0.000000) [0.000000|1.000000] "" Vector__XXX
 SG_ WFS_ID_Geb_steckt  : 7|1@1+ (1.000000,0.000000) [0.000000|1.000000] "" Vector__XXX
 SG_ WFS_Schluessel_Soll  : 8|4@1+ (1.000000,0.000000) [0.000000|15.000000] "" Vector__XXX
 SG_ WFS_Schluessel_Ist  : 12|4@1+ (1.000000,0.000000) [0.000000|15.000000] "" Vector__XXX
 SG_ WFS_Safe  : 16|1@1+ (1.000000,0.000000) [0.000000|1.000000] "" Vector__XXX
 SG_ WFS_LZ  : 17|2@1+ (1.000000,0.000000) [0.000000|3.000000] "" Vector__XXX
 SG_ WFS_ELV_authorisiert  : 19|1@1+ (1.000000,0.000000) [0.000000|1.000000] "" Vector__XXX
 SG_ WFS_LF_Aktiv  : 20|1@1+ (1.000000,0.000000) [0.000000|1.000000] "" Vector__XXX
 SG_ WFS_Betrieb_Lesespule  : 21|1@1+ (1.000000,0.000000) [0.000000|1.000000] "" Vector__XXX
 SG_ WFS_Klemmenfreigabe  : 22|1@1+ (1.000000,0.000000) [0.000000|1.000000] "" Motor_BEV
 SG_ WFS_Klemmenfreigabe_Signatur  : 23|11@1+ (1.000000,0.000000) [0.000000|2047.000000] "" Vector__XXX
 SG_ WFS_Fahrerhinweise  : 34|2@1+ (1.000000,0.000000) [0.000000|3.000000] "" Vector__XXX
 SG_ WFS_Parken_Status  : 36|2@1+ (1.000000,0.000000) [0.000000|3.000000] "" Vector__XXX

BO_ 2617028096 XCP_Airbag_CRO_01: 64 Vector__XXX
 SG_ XCP_Airbag_CRO_01_Data  : 0|512@1+ (1.000000,0.000000) [0.000000|13407807929942597099574024998205846127479365820592393377723561443721764030073546976801874298166903427690031858186486050853753882811946569946433649006084096.000000] "" Airbag

BO_ 2617028097 XCP_Airbag_DTO_01: 64 Airbag
 SG_ XCP_Airbag_DTO_01_Data  : 0|512@1+ (1.000000,0.000000) [0.000000|13407807929942597099574024998205846127479365820592393377723561443721764030073546976801874298166903427690031858186486050853753882811946569946433649006084096.000000] "" Vector__XXX

BO_ 2617239040 XCP_EMotor_01_CRO_01: 64 Vector__XXX
 SG_ XCP_EMotor_01_CRO_01_Data  : 0|64@1+ (1.000000,0.000000) [0.000000|18446744073709551616.000000] "" LE1

BO_ 2617239041 XCP_EMotor_01_DTO_01: 64 LE1
 SG_ XCP_EMotor_01_DTO_01_Data  : 0|64@1+ (1.000000,0.000000) [0.000000|18446744073709551616.000000] "" Vector__XXX

BO_ 2617239042 XCP_EMotor_01_DTO_02: 64 LE1
 SG_ XCP_EMotor_01_DTO_02_Data  : 0|64@1+ (1.000000,0.000000) [0.000000|18446744073709551616.000000] "" Vector__XXX

BO_ 2617239043 XCP_EMotor_01_DTO_03: 64 LE1
 SG_ XCP_EMotor_01_DTO_03_Data  : 0|64@1+ (1.000000,0.000000) [0.000000|18446744073709551616.000000] "" Vector__XXX

BO_ 2617239044 XCP_EMotor_01_DTO_04: 64 LE1
 SG_ XCP_EMotor_01_DTO_04_Data  : 0|64@1+ (1.000000,0.000000) [0.000000|18446744073709551616.000000] "" Vector__XXX

BO_ 2617122304 XCP_EMotor_02_CRO_01: 64 Vector__XXX
 SG_ XCP_EMotor_02_CRO_01_Data  : 0|64@1+ (1.000000,0.000000) [0.000000|18446744073709551616.000000] "" LE2

BO_ 2617122305 XCP_EMotor_02_DTO_01: 64 LE2
 SG_ XCP_EMotor_02_DTO_01_Data  : 0|64@1+ (1.000000,0.000000) [0.000000|18446744073709551616.000000] "" Vector__XXX

BO_ 2617122306 XCP_EMotor_02_DTO_02: 64 LE2
 SG_ XCP_EMotor_02_DTO_02_Data  : 0|64@1+ (1.000000,0.000000) [0.000000|18446744073709551616.000000] "" Vector__XXX

BO_ 2617122307 XCP_EMotor_02_DTO_03: 64 LE2
 SG_ XCP_EMotor_02_DTO_03_Data  : 0|64@1+ (1.000000,0.000000) [0.000000|18446744073709551616.000000] "" Vector__XXX

BO_ 2617122308 XCP_EMotor_02_DTO_04: 64 LE2
 SG_ XCP_EMotor_02_DTO_04_Data  : 0|64@1+ (1.000000,0.000000) [0.000000|18446744073709551616.000000] "" Vector__XXX

BO_ 2617226768 XCP_Motor_CRO_01: 64 Vector__XXX
 SG_ XCP_Motor_CRO_01_Data  : 0|64@1+ (1.000000,0.000000) [0.000000|18446744073709551616.000000] "" Motor_BEV

BO_ 2617226769 XCP_Motor_DTO_01: 64 Motor_BEV
 SG_ XCP_Motor_DTO_01_Data  : 0|64@1+ (1.000000,0.000000) [0.000000|18446744073709551616.000000] "" Vector__XXX

BO_ 1411 ZV_02: 8 ICAS1_Gateway
 SG_ ZV_verriegeln_Anf  : 0|1@1+ (1.000000,0.000000) [0.000000|1.000000] "" Vector__XXX
 SG_ ZV_STSG_HFS_Anf  : 1|1@1+ (1.000000,0.000000) [0.000000|1.000000] "" Vector__XXX
 SG_ ZV_STSG_HBFS_Anf  : 2|1@1+ (1.000000,0.000000) [0.000000|1.000000] "" Vector__XXX
 SG_ ZV_Anf_Challenge_Auth  : 3|1@1+ (1.000000,0.000000) [0.000000|1.000000] "" Vector__XXX
 SG_ BCM_FH_Freigabe  : 12|1@1+ (1.000000,0.000000) [0.000000|1.000000] "" Vector__XXX
 SG_ BCM_Komfortfkt_Freigabe  : 13|1@1+ (1.000000,0.000000) [0.000000|1.000000] "" Vector__XXX
 SG_ BCM_HSK_Freigabe  : 14|1@1+ (1.000000,0.000000) [0.000000|1.000000] "" Vector__XXX
 SG_ BCM_Verdeck_Freigabe  : 15|1@1+ (1.000000,0.000000) [0.000000|1.000000] "" Vector__XXX
 SG_ ZV_verriegelt_intern_ist  : 16|1@1+ (1.000000,0.000000) [0.000000|1.000000] "" Vector__XXX
 SG_ ZV_verriegelt_extern_ist  : 17|1@1+ (1.000000,0.000000) [0.000000|1.000000] "" Airbag
 SG_ ZV_verriegelt_intern_soll  : 18|1@1+ (1.000000,0.000000) [0.000000|1.000000] "" Vector__XXX
 SG_ ZV_verriegelt_extern_soll  : 19|1@1+ (1.000000,0.000000) [0.000000|1.000000] "" Airbag
 SG_ ZV_gesafet_extern_ist  : 20|1@1+ (1.000000,0.000000) [0.000000|1.000000] "" Vector__XXX
 SG_ ZV_gesafet_extern_soll  : 21|1@1+ (1.000000,0.000000) [0.000000|1.000000] "" Vector__XXX
 SG_ ZV_Einzeltuerentriegelung  : 22|1@1+ (1.000000,0.000000) [0.000000|1.000000] "" Vector__XXX
 SG_ ZV_Heckeinzelentriegelung  : 23|1@1+ (1.000000,0.000000) [0.000000|1.000000] "" Vector__XXX
 SG_ ZV_FT_offen  : 24|1@1+ (1.000000,0.000000) [0.000000|1.000000] "" Motor_BEV
 SG_ ZV_BT_offen  : 25|1@1+ (1.000000,0.000000) [0.000000|1.000000] "" Motor_BEV
 SG_ ZV_HFS_offen  : 26|1@1+ (1.000000,0.000000) [0.000000|1.000000] "" Motor_BEV
 SG_ ZV_HBFS_offen  : 27|1@1+ (1.000000,0.000000) [0.000000|1.000000] "" Motor_BEV
 SG_ ZV_HD_offen  : 28|1@1+ (1.000000,0.000000) [0.000000|1.000000] "" Motor_BEV
 SG_ ZV_HS_offen  : 29|1@1+ (1.000000,0.000000) [0.000000|1.000000] "" Vector__XXX
 SG_ IRUE_aktiv  : 30|1@1+ (1.000000,0.000000) [0.000000|1.000000] "" Vector__XXX
 SG_ DWA_aktiv  : 31|1@1+ (1.000000,0.000000) [0.000000|1.000000] "" Vector__XXX
 SG_ FFB_HDF_Taste  : 34|1@1+ (1.000000,0.000000) [0.000000|1.000000] "" Vector__XXX
 SG_ FFB_Panik_Taste  : 35|1@1+ (1.000000,0.000000) [0.000000|1.000000] "" Vector__XXX
 SG_ FFB_Auf_Taste  : 36|1@1+ (1.000000,0.000000) [0.000000|1.000000] "" Vector__XXX
 SG_ FFB_Zu_Taste  : 37|1@1+ (1.000000,0.000000) [0.000000|1.000000] "" Vector__XXX
 SG_ FFB_CarFinder  : 38|1@1+ (1.000000,0.000000) [0.000000|1.000000] "" Vector__XXX
 SG_ FFB_Komfortoeffnen  : 39|1@1+ (1.000000,0.000000) [0.000000|1.000000] "" Vector__XXX
 SG_ FFB_Komfortschliessen  : 40|1@1+ (1.000000,0.000000) [0.000000|1.000000] "" Vector__XXX
 SG_ FBS_IDG_in_Reichweite  : 41|1@1+ (1.000000,0.000000) [0.000000|1.000000] "" Vector__XXX
 SG_ ZV_Schluessel_Zugang  : 42|4@1+ (1.000000,0.000000) [0.000000|15.000000] "" Vector__XXX
 SG_ ZV_SafeFunktion_aktiv  : 46|1@1+ (1.000000,0.000000) [0.000000|1.000000] "" Vector__XXX
 SG_ FBS_Warn_Schluessel_Batt  : 47|1@1+ (1.000000,0.000000) [0.000000|1.000000] "" Vector__XXX
 SG_ ZV_Oeffnungsmodus  : 48|2@1+ (1.000000,0.000000) [0.000000|3.000000] "" Vector__XXX
 SG_ ZV_ist_Zustand_verfuegbar  : 54|1@1+ (1.000000,0.000000) [0.000000|1.000000] "" Vector__XXX
 SG_ IRUE_Taster_Fkts_LED  : 55|1@1+ (1.000000,0.000000) [0.000000|1.000000] "" Vector__XXX
 SG_ ZV_Tankklappe_offen  : 56|1@1+ (1.000000,0.000000) [0.000000|1.000000] "" Vector__XXX
 SG_ ZV_Rollo_auf  : 57|1@1+ (1.000000,0.000000) [0.000000|1.000000] "" Vector__XXX
 SG_ ZV_Rollo_zu  : 58|1@1+ (1.000000,0.000000) [0.000000|1.000000] "" Vector__XXX
 SG_ ZV_SAD_auf  : 59|1@1+ (1.000000,0.000000) [0.000000|1.000000] "" Vector__XXX
 SG_ ZV_SAD_zu  : 60|1@1+ (1.000000,0.000000) [0.000000|1.000000] "" Vector__XXX
 SG_ ZV_verriegelt_soll  : 62|2@1+ (1.000000,0.000000) [0.000000|3.000000] "" Vector__XXX

BU_:  Airbag BAP_Tester ICAS1_Gateway ICAS1_KommunikationsServer LE1 LE2 Motor_BEV Schaltbetaetigung

BO_ 2463978663 VZE_04: 32 ICAS1_Gateway
 SG_ VZE_Anzeigemodus  : 0|2@1+ (1.000000,0.000000) [0.000000|3.000000] "" Vector__XXX
 SG_ VZE_Hinweistext  : 2|3@1+ (1.000000,0.000000) [1.000000|7.000000] "" Motor_BEV
 SG_ VZE_Verkehrszeichen_Einheit  : 8|1@1+ (1.000000,0.000000) [0.000000|1.000000] "" Vector__XXX
 SG_ VZE_Anzeigeunterdrueck_Zeichen_3  : 9|1@1+ (1.000000,0.000000) [0.000000|1.000000] "" Vector__XXX
 SG_ VZE_Anzeigeunterdrueck_Zeichen_2  : 10|1@1+ (1.000000,0.000000) [0.000000|1.000000] "" Vector__XXX
 SG_ VZE_Verkehrszeichen_1  : 11|8@1+ (1.000000,0.000000) [1.000000|255.000000] "" Motor_BEV
 SG_ VZE_Verkehrszeichen_2  : 19|8@1+ (1.000000,0.000000) [1.000000|255.000000] "" Vector__XXX
 SG_ VZE_Verkehrszeichen_3  : 27|8@1+ (1.000000,0.000000) [1.000000|255.000000] "" Vector__XXX
 SG_ VZE_Warnung_Verkehrszeichen_1  : 35|1@1+ (1.000000,0.000000) [0.000000|1.000000] "" Vector__XXX
 SG_ VZE_Warnung_Verkehrszeichen_2  : 36|1@1+ (1.000000,0.000000) [0.000000|1.000000] "" Vector__XXX
 SG_ VZE_Warnung_Verkehrszeichen_3  : 37|1@1+ (1.000000,0.000000) [0.000000|1.000000] "" Vector__XXX
 SG_ VZE_Zusatzschild_1  : 38|4@1+ (1.000000,0.000000) [1.000000|15.000000] "" Vector__XXX
 SG_ VZE_Zusatzschild_2  : 42|4@1+ (1.000000,0.000000) [1.000000|15.000000] "" Vector__XXX
 SG_ VZE_Zusatzschild_3  : 46|4@1+ (1.000000,0.000000) [1.000000|15.000000] "" Vector__XXX
 SG_ VZE_Anzeigeunterdrueck_Zeichen_1  : 50|1@1+ (1.000000,0.000000) [0.000000|1.000000] "" Vector__XXX
 SG_ VZE_Zeichen_01_KameraWied  : 51|1@1+ (1.000000,0.000000) [0.000000|1.000000] "" Motor_BEV
 SG_ VZE_Zeichen_02_KameraWied  : 52|1@1+ (1.000000,0.000000) [0.000000|1.000000] "" Vector__XXX
 SG_ VZE_Zeichen_03_KameraWied  : 53|1@1+ (1.000000,0.000000) [0.000000|1.000000] "" Vector__XXX
 SG_ VZE_Zeichen_01_Kamera  : 54|1@1+ (1.000000,0.000000) [0.000000|1.000000] "" Motor_BEV
 SG_ VZE_Zeichen_01_Karte  : 55|1@1+ (1.000000,0.000000) [0.000000|1.000000] "" Vector__XXX
 SG_ VZE_Zeichen_01_Gesetz  : 56|1@1+ (1.000000,0.000000) [0.000000|1.000000] "" Vector__XXX
 SG_ VZE_Zeichen_02_Kamera  : 57|1@1+ (1.000000,0.000000) [0.000000|1.000000] "" Vector__XXX
 SG_ VZE_Zeichen_02_Karte  : 58|1@1+ (1.000000,0.000000) [0.000000|1.000000] "" Vector__XXX
 SG_ VZE_Zeichen_02_Gesetz  : 59|1@1+ (1.000000,0.000000) [0.000000|1.000000] "" Vector__XXX
 SG_ VZE_Zeichen_03_Kamera  : 60|1@1+ (1.000000,0.000000) [0.000000|1.000000] "" Vector__XXX
 SG_ VZE_Zeichen_03_Karte  : 61|1@1+ (1.000000,0.000000) [0.000000|1.000000] "" Vector__XXX
 SG_ VZE_Zeichen_03_Gesetz  : 62|1@1+ (1.000000,0.000000) [0.000000|1.000000] "" Vector__XXX
 SG_ VZE_Gong  : 63|1@1+ (1.000000,0.000000) [0.000000|1.000000] "" Vector__XXX
 SG_ VZE_Anzeigeunterdrueck_Zeichen_5  : 72|1@1+ (1.000000,0.000000) [0.000000|1.000000] "" Vector__XXX
 SG_ VZE_Zeichen_05_KameraWied  : 73|1@1+ (1.000000,0.000000) [0.000000|1.000000] "" Vector__XXX
 SG_ VZE_Zeichen_05_Kamera  : 74|1@1+ (1.000000,0.000000) [0.000000|1.000000] "" Vector__XXX
 SG_ VZE_Verkehrszeichen_4  : 75|8@1+ (1.000000,0.000000) [1.000000|255.000000] "" Motor_BEV
 SG_ VZE_Verkehrszeichen_5  : 83|8@1+ (1.000000,0.000000) [1.000000|255.000000] "" Motor_BEV
 SG_ VZE_Anhaenger_Vmax  : 91|4@1+ (10.000000,10.000000) [10.000000|140.000000] "Unit_KiloMeterPerHour" Vector__XXX
 SG_ VZE_Zeichen_04_Gesetz  : 95|1@1+ (1.000000,0.000000) [0.000000|1.000000] "" Vector__XXX
 SG_ VZE_Zeichen_04_Kamera  : 96|1@1+ (1.000000,0.000000) [0.000000|1.000000] "" Vector__XXX
 SG_ VZE_Zeichen_04_KameraWied  : 97|1@1+ (1.000000,0.000000) [0.000000|1.000000] "" Vector__XXX
 SG_ VZE_Zeichen_04_Karte  : 98|1@1+ (1.000000,0.000000) [0.000000|1.000000] "" Vector__XXX
 SG_ VZE_Warnung_Verkehrszeichen_4  : 99|1@1+ (1.000000,0.000000) [0.000000|1.000000] "" Vector__XXX
 SG_ VZE_Warnung_Verkehrszeichen_5  : 100|1@1+ (1.000000,0.000000) [0.000000|1.000000] "" Vector__XXX
 SG_ VZE_Zeichen_05_Gesetz  : 101|1@1+ (1.000000,0.000000) [0.000000|1.000000] "" Vector__XXX
 SG_ VZE_Zusatzschild_4  : 102|4@1+ (1.000000,0.000000) [1.000000|15.000000] "" Vector__XXX
 SG_ VZE_Zusatzschild_5  : 106|4@1+ (1.000000,0.000000) [1.000000|15.000000] "" Vector__XXX
 SG_ VZE_Baustelle  : 110|2@1+ (1.000000,0.000000) [0.000000|3.000000] "" Vector__XXX
 SG_ VZE_Zeichen_05_Karte  : 112|1@1+ (1.000000,0.000000) [0.000000|1.000000] "" Vector__XXX
 SG_ VZE_Zeichen_05_Entfernung  : 113|7@1+ (1.000000,0.000000) [1.000000|127.000000] "Unit_Meter" Motor_BEV
 SG_ VZE_Zeichen_05_Entfernung_StdA  : 120|7@1+ (1.000000,0.000000) [1.000000|127.000000] "Unit_Meter" Motor_BEV
 SG_ VZE_Anzeigeunterdrueck_Zeichen_4  : 127|1@1+ (1.000000,0.000000) [0.000000|1.000000] "" Vector__XXX
 SG_ VZE_Verkehrszeichen_6  : 128|8@1+ (1.000000,0.000000) [1.000000|255.000000] "Unit_None" Motor_BEV
 SG_ VZE_Zusatzschild_6  : 136|4@1+ (1.000000,0.000000) [1.000000|15.000000] "" Vector__XXX
 SG_ VZE_Zeichen_06_Entfernung  : 140|7@1+ (1.000000,0.000000) [1.000000|127.000000] "Unit_Meter" Motor_BEV
 SG_ VZE_Zeichen_06_Entfernung_StdA  : 147|7@1+ (1.000000,0.000000) [1.000000|127.000000] "Unit_Meter" Motor_BEV
 SG_ VZE_Umweltinfo_Naesse  : 154|1@1+ (1.000000,0.000000) [0.000000|1.000000] "" Motor_BEV
 SG_ VZE_Umweltinfo_Nebel  : 155|1@1+ (1.000000,0.000000) [0.000000|1.000000] "" Motor_BEV
 SG_ VZE_Umweltinfo_Anhaengerbetrieb  : 156|1@1+ (1.000000,0.000000) [0.000000|1.000000] "" Vector__XXX
 SG_ VZE_Erweiterte_Information  : 157|8@1+ (1.000000,0.000000) [1.000000|255.000000] "Unit_None" Vector__XXX
 SG_ VZE_Tempowarnung_Status  : 165|1@1+ (1.000000,0.000000) [0.000000|1.000000] "" Vector__XXX
 SG_ VZE_Tempowarnung_Einheit  : 166|1@1+ (1.000000,0.000000) [0.000000|1.000000] "" Vector__XXX
 SG_ VZE_Tempowarnung_Offset  : 167|5@1+ (1.000000,0.000000) [1.000000|31.000000] "" Vector__XXX
 SG_ VZE_FoD_Status  : 206|2@1+ (1.000000,0.000000) [0.000000|3.000000] "" Vector__XXX
 SG_ VZE_Anzeige_ZS_1  : 208|4@1+ (1.000000,0.000000) [1.000000|15.000000] "Unit_None" Vector__XXX
 SG_ VZE_Anzeige_ZS_2  : 212|4@1+ (1.000000,0.000000) [1.000000|15.000000] "Unit_None" Vector__XXX
 SG_ VZE_Anzeige_ZS_3  : 216|4@1+ (1.000000,0.000000) [1.000000|15.000000] "Unit_None" Vector__XXX
 SG_ VZE_Hinweistext_03  : 220|4@1+ (1.000000,0.000000) [1.000000|15.000000] "" Vector__XXX
 SG_ VZE_Land  : 224|5@1+ (1.000000,0.000000) [1.000000|31.000000] "" Vector__XXX
 SG_ VZE_Warnung_VZ_1  : 229|1@1+ (1.000000,0.000000) [0.000000|1.000000] "" Vector__XXX
 SG_ VZE_Warnung_VZ_2  : 230|1@1+ (1.000000,0.000000) [0.000000|1.000000] "" Vector__XXX
 SG_ VZE_Warnung_VZ_3  : 231|1@1+ (1.000000,0.000000) [0.000000|1.000000] "" Vector__XXX
 SG_ VZE_Anzeige_VZ_1  : 232|8@1+ (1.000000,0.000000) [1.000000|255.000000] "" Vector__XXX
 SG_ VZE_Anzeige_VZ_2  : 240|8@1+ (1.000000,0.000000) [1.000000|255.000000] "Unit_None" Vector__XXX
 SG_ VZE_Anzeige_VZ_3  : 248|8@1+ (1.000000,0.000000) [1.000000|255.000000] "Unit_None" Vector__XXX

BO_ 181 Waehlhebel_04: 8 ICAS1_Gateway
 SG_ Waehlhebel_04_CRC  : 0|8@1+ (1.000000,0.000000) [0.000000|255.000000] "" Motor_BEV
 SG_ Waehlhebel_04_BZ  : 8|4@1+ (1.000000,0.000000) [0.000000|15.000000] "" Motor_BEV
 SG_ WH_gespeicherte_Fahrstufe  : 12|3@1+ (1.000000,0.000000) [0.000000|7.000000] "" Vector__XXX
 SG_ WH_Initialisierung  : 15|1@1+ (1.000000,0.000000) [0.000000|1.000000] "" Motor_BEV
 SG_ WH_SensorPos_roh  : 16|4@1+ (1.000000,0.000000) [0.000000|15.000000] "" Motor_BEV
 SG_ WH_SensorPos_roh_inv  : 20|4@1+ (1.000000,0.000000) [0.000000|15.000000] "" Motor_BEV
 SG_ WH_Testergebnis  : 24|8@1+ (1.000000,0.000000) [0.000000|255.000000] "" Vector__XXX
 SG_ WH_Test_Aktiv  : 32|1@1+ (1.000000,0.000000) [0.000000|1.000000] "" Vector__XXX
 SG_ WH_Ist_Haltemagnet  : 33|2@1+ (1.000000,0.000000) [0.000000|3.000000] "" Motor_BEV
 SG_ WH_Variante  : 35|4@1+ (1.000000,0.000000) [0.000000|15.000000] "" Motor_BEV
 SG_ WH_Entsperrtaste_02  : 39|2@1+ (1.000000,0.000000) [0.000000|3.000000] "" Motor_BEV
 SG_ WH_P_Taste  : 41|2@1+ (1.000000,0.000000) [0.000000|3.000000] "" Motor_BEV
 SG_ WH_Ende_N_Haltephase  : 43|1@1+ (1.000000,0.000000) [0.000000|1.000000] "" Vector__XXX
 SG_ WH_Fahrstufe  : 44|4@1+ (1.000000,0.000000) [0.000000|15.000000] "" Motor_BEV
 SG_ WH_Status_Shiftlock  : 48|3@1+ (1.000000,0.000000) [0.000000|7.000000] "" Motor_BEV
 SG_ WH_Zustand_N_Haltephase  : 51|2@1+ (1.000000,0.000000) [0.000000|3.000000] "" Vector__XXX

BO_ 2463978687 Waehlhebel_06: 8 ICAS1_Gateway
 SG_ WH_Fehler_Haltemagnet_Status  : 41|1@1+ (1.000000,0.000000) [0.000000|1.000000] "" Motor_BEV
 SG_ WH_Fehler_CRC_SBM  : 42|1@1+ (1.000000,0.000000) [0.000000|1.000000] "" Motor_BEV
 SG_ WH_Fehler_CRC_SBM_Status  : 43|1@1+ (1.000000,0.000000) [0.000000|1.000000] "" Motor_BEV
 SG_ WH_Fehler_Timeout_SBM  : 44|1@1+ (1.000000,0.000000) [0.000000|1.000000] "" Motor_BEV
 SG_ WH_Fehler_Timeout_SBM_Status  : 45|1@1+ (1.000000,0.000000) [0.000000|1.000000] "" Motor_BEV
 SG_ WH_Fehler_Ueberspannung  : 46|1@1+ (1.000000,0.000000) [0.000000|1.000000] "" Motor_BEV
 SG_ WH_Fehler_Ueberspannung_Status  : 47|1@1+ (1.000000,0.000000) [0.000000|1.000000] "" Motor_BEV
 SG_ WH_Fehler_BZ_SBM  : 48|1@1+ (1.000000,0.000000) [0.000000|1.000000] "" Motor_BEV
 SG_ WH_Fehler_BZ_SBM_Status  : 49|1@1+ (1.000000,0.000000) [0.000000|1.000000] "" Motor_BEV
 SG_ WH_Fehler_Unterspannung  : 50|1@1+ (1.000000,0.000000) [0.000000|1.000000] "" Motor_BEV
 SG_ WH_Fehler_Unterspannung_Status  : 51|1@1+ (1.000000,0.000000) [0.000000|1.000000] "" Motor_BEV
 SG_ WH_Fehler_Ausleuchtung  : 52|1@1+ (1.000000,0.000000) [0.000000|1.000000] "" Motor_BEV
 SG_ WH_Fehler_Ausleuchtung_Status  : 53|1@1+ (1.000000,0.000000) [0.000000|1.000000] "" Motor_BEV
 SG_ WH_Fehler_Entsperrtaste  : 54|1@1+ (1.000000,0.000000) [0.000000|1.000000] "" Motor_BEV
 SG_ WH_Fehler_Entsperrtaste_Status  : 55|1@1+ (1.000000,0.000000) [0.000000|1.000000] "" Motor_BEV
 SG_ WH_Fehler_P_Taste  : 56|1@1+ (1.000000,0.000000) [0.000000|1.000000] "" Motor_BEV
 SG_ WH_Fehler_P_Taste_Status  : 57|1@1+ (1.000000,0.000000) [0.000000|1.000000] "" Motor_BEV
 SG_ WH_Fehler_Sensor_einfach  : 58|1@1+ (1.000000,0.000000) [0.000000|1.000000] "" Motor_BEV
 SG_ WH_Fehler_Sensor_einfach_Status  : 59|1@1+ (1.000000,0.000000) [0.000000|1.000000] "" Motor_BEV
 SG_ WH_Fehler_Sensor_mehrfach  : 60|1@1+ (1.000000,0.000000) [0.000000|1.000000] "" Motor_BEV
 SG_ WH_Fehler_Sensor_mehrfach_Status  : 61|1@1+ (1.000000,0.000000) [0.000000|1.000000] "" Motor_BEV
 SG_ WH_Fehler_Shiftlock  : 62|1@1+ (1.000000,0.000000) [0.000000|1.000000] "" Motor_BEV
 SG_ WH_Fehler_Shiftlock_Status  : 63|1@1+ (1.000000,0.000000) [0.000000|1.000000] "" Motor_BEV

BO_ 916 WBA_03: 8 Motor_BEV
 SG_ WBA_03_CRC  : 0|8@1+ (1.000000,0.000000) [0.000000|255.000000] "" ICAS1_Gateway
 SG_ WBA_03_BZ  : 8|4@1+ (1.000000,0.000000) [0.000000|15.000000] "" ICAS1_Gateway
 SG_ WBA_Fahrstufe_02  : 12|4@1+ (1.000000,0.000000) [0.000000|15.000000] "" ICAS1_Gateway ICAS1_KommunikationsServer
 SG_ WBA_ZielFahrstufe  : 16|4@1+ (1.000000,0.000000) [0.000000|15.000000] "" ICAS1_Gateway
 SG_ WBA_GE_Warnung_02  : 20|4@1+ (1.000000,0.000000) [0.000000|15.000000] "" ICAS1_Gateway
 SG_ WBA_eing_Gang_02  : 24|4@1+ (1.000000,0.000000) [0.000000|15.000000] "" ICAS1_Gateway
 SG_ WBA_GE_Texte  : 28|3@1+ (1.000000,0.000000) [0.000000|7.000000] "" ICAS1_Gateway
 SG_ WBA_Segeln_aktiv  : 31|1@1+ (1.000000,0.000000) [0.000000|1.000000] "" ICAS1_Gateway
 SG_ WBA_Schaltschema_02  : 32|3@1+ (1.000000,0.000000) [0.000000|7.000000] "" ICAS1_Gateway
 SG_ WBA_Schaltschema_FS_inaktiv  : 35|2@1+ (1.000000,0.000000) [0.000000|3.000000] "" ICAS1_Gateway
 SG_ WBA_GE_Zusatzwarnungen  : 37|3@1+ (1.000000,0.000000) [0.000000|7.000000] "" ICAS1_Gateway
 SG_ GE_Sollgang  : 40|4@1+ (1.000000,0.000000) [0.000000|15.000000] "" ICAS1_Gateway
 SG_ GE_Tipschaltempf_verfuegbar  : 44|1@1+ (1.000000,0.000000) [0.000000|1.000000] "" ICAS1_Gateway
 SG_ WBA_GE_Texte_02  : 45|3@1+ (1.000000,0.000000) [0.000000|7.000000] "" ICAS1_Gateway
 SG_ WBA_Schaltschema_Tippgasse  : 48|1@1+ (1.000000,0.000000) [0.000000|1.000000] "" ICAS1_Gateway
 SG_ WBA_Schaltschema_Fahreraktion  : 49|1@1+ (1.000000,0.000000) [0.000000|1.000000] "" ICAS1_Gateway
 SG_ WBA_Schaltschema_FS_vorwaerts  : 50|2@1+ (1.000000,0.000000) [0.000000|3.000000] "" ICAS1_Gateway
 SG_ WBA_Shiftlock_Lampe  : 52|1@1+ (1.000000,0.000000) [0.000000|1.000000] "" ICAS1_Gateway
 SG_ WBA_Anforderung_Akustik  : 53|1@1+ (1.000000,0.000000) [0.000000|1.000000] "" ICAS1_Gateway
 SG_ WBA_Blinken  : 54|1@1+ (1.000000,0.000000) [0.000000|1.000000] "" ICAS1_Gateway
 SG_ GE_Wiederstart_Anz_Std  : 55|1@1+ (1.000000,0.000000) [0.000000|1.000000] "" ICAS1_Gateway
 SG_ GE_Stoppverbot_Anz_01  : 56|1@1+ (1.000000,0.000000) [0.000000|1.000000] "" ICAS1_Gateway
 SG_ GE_Stoppverbot_Anz_02  : 57|1@1+ (1.000000,0.000000) [0.000000|1.000000] "" ICAS1_Gateway
 SG_ GE_Stoppverbot_Anz_03  : 58|1@1+ (1.000000,0.000000) [0.000000|1.000000] "" ICAS1_Gateway
 SG_ GE_Stoppverbot_Anz_04  : 59|1@1+ (1.000000,0.000000) [0.000000|1.000000] "" ICAS1_Gateway
 SG_ GE_Stoppverbot_Anz_05  : 60|1@1+ (1.000000,0.000000) [0.000000|1.000000] "" ICAS1_Gateway
 SG_ GE_Stoppverbot_Anz_06  : 61|1@1+ (1.000000,0.000000) [0.000000|1.000000] "" ICAS1_Gateway
 SG_ GE_Stoppverbot_Anz_07  : 62|1@1+ (1.000000,0.000000) [0.000000|1.000000] "" ICAS1_Gateway
 SG_ GE_Stoppverbot_Anz_Std  : 63|1@1+ (1.000000,0.000000) [0.000000|1.000000] "" ICAS1_Gateway

BO_ 1361 WFS_01: 8 ICAS1_Gateway
 SG_ WFS_Schluessel_Fahrberecht  : 0|4@1+ (1.000000,0.000000) [0.000000|15.000000] "" Vector__XXX
 SG_ WFS_Verbauinfo_ELV  : 4|1@1+ (1.000000,0.000000) [0.000000|1.000000] "" Vector__XXX
 SG_ WFS_ID_Geb_autorisiert  : 5|1@1+ (1.000000,0.000000) [0.000000|1.000000] "" Vector__XXX
 SG_ WFS_ID_Geb_autorisiert_in_Kl15  : 6|1@1+ (1.000000,0.000000) [0.000000|1.000000] "" Vector__XXX
 SG_ WFS_ID_Geb_steckt  : 7|1@1+ (1.000000,0.000000) [0.000000|1.000000] "" Vector__XXX
 SG_ WFS_Schluessel_Soll  : 8|4@1+ (1.000000,0.000000) [0.000000|15.000000] "" Vector__XXX
 SG_ WFS_Schluessel_Ist  : 12|4@1+ (1.000000,0.000000) [0.000000|15.000000] "" Vector__XXX
 SG_ WFS_Safe  : 16|1@1+ (1.000000,0.000000) [0.000000|1.000000] "" Vector__XXX
 SG_ WFS_LZ  : 17|2@1+ (1.000000,0.000000) [0.000000|3.000000] "" Vector__XXX
 SG_ WFS_ELV_authorisiert  : 19|1@1+ (1.000000,0.000000) [0.000000|1.000000] "" Vector__XXX
 SG_ WFS_LF_Aktiv  : 20|1@1+ (1.000000,0.000000) [0.000000|1.000000] "" Vector__XXX
 SG_ WFS_Betrieb_Lesespule  : 21|1@1+ (1.000000,0.000000) [0.000000|1.000000] "" Vector__XXX
 SG_ WFS_Klemmenfreigabe  : 22|1@1+ (1.000000,0.000000) [0.000000|1.000000] "" Motor_BEV
 SG_ WFS_Klemmenfreigabe_Signatur  : 23|11@1+ (1.000000,0.000000) [0.000000|2047.000000] "" Vector__XXX
 SG_ WFS_Fahrerhinweise  : 34|2@1+ (1.000000,0.000000) [0.000000|3.000000] "" Vector__XXX
 SG_ WFS_Parken_Status  : 36|2@1+ (1.000000,0.000000) [0.000000|3.000000] "" Vector__XXX

BO_ 2617028096 XCP_Airbag_CRO_01: 64 Vector__XXX
 SG_ XCP_Airbag_CRO_01_Data  : 0|512@1+ (1.000000,0.000000) [0.000000|13407807929942597099574024998205846127479365820592393377723561443721764030073546976801874298166903427690031858186486050853753882811946569946433649006084096.000000] "" Airbag

BO_ 2617028097 XCP_Airbag_DTO_01: 64 Airbag
 SG_ XCP_Airbag_DTO_01_Data  : 0|512@1+ (1.000000,0.000000) [0.000000|13407807929942597099574024998205846127479365820592393377723561443721764030073546976801874298166903427690031858186486050853753882811946569946433649006084096.000000] "" Vector__XXX

BO_ 2617239040 XCP_EMotor_01_CRO_01: 64 Vector__XXX
 SG_ XCP_EMotor_01_CRO_01_Data  : 0|64@1+ (1.000000,0.000000) [0.000000|18446744073709551616.000000] "" LE1

BO_ 2617239041 XCP_EMotor_01_DTO_01: 64 LE1
 SG_ XCP_EMotor_01_DTO_01_Data  : 0|64@1+ (1.000000,0.000000) [0.000000|18446744073709551616.000000] "" Vector__XXX

BO_ 2617239042 XCP_EMotor_01_DTO_02: 64 LE1
 SG_ XCP_EMotor_01_DTO_02_Data  : 0|64@1+ (1.000000,0.000000) [0.000000|18446744073709551616.000000] "" Vector__XXX

BO_ 2617239043 XCP_EMotor_01_DTO_03: 64 LE1
 SG_ XCP_EMotor_01_DTO_03_Data  : 0|64@1+ (1.000000,0.000000) [0.000000|18446744073709551616.000000] "" Vector__XXX

BO_ 2617239044 XCP_EMotor_01_DTO_04: 64 LE1
 SG_ XCP_EMotor_01_DTO_04_Data  : 0|64@1+ (1.000000,0.000000) [0.000000|18446744073709551616.000000] "" Vector__XXX

BO_ 2617122304 XCP_EMotor_02_CRO_01: 64 Vector__XXX
 SG_ XCP_EMotor_02_CRO_01_Data  : 0|64@1+ (1.000000,0.000000) [0.000000|18446744073709551616.000000] "" LE2

BO_ 2617122305 XCP_EMotor_02_DTO_01: 64 LE2
 SG_ XCP_EMotor_02_DTO_01_Data  : 0|64@1+ (1.000000,0.000000) [0.000000|18446744073709551616.000000] "" Vector__XXX

BO_ 2617122306 XCP_EMotor_02_DTO_02: 64 LE2
 SG_ XCP_EMotor_02_DTO_02_Data  : 0|64@1+ (1.000000,0.000000) [0.000000|18446744073709551616.000000] "" Vector__XXX

BO_ 2617122307 XCP_EMotor_02_DTO_03: 64 LE2
 SG_ XCP_EMotor_02_DTO_03_Data  : 0|64@1+ (1.000000,0.000000) [0.000000|18446744073709551616.000000] "" Vector__XXX

BO_ 2617122308 XCP_EMotor_02_DTO_04: 64 LE2
 SG_ XCP_EMotor_02_DTO_04_Data  : 0|64@1+ (1.000000,0.000000) [0.000000|18446744073709551616.000000] "" Vector__XXX

BO_ 2617226768 XCP_Motor_CRO_01: 64 Vector__XXX
 SG_ XCP_Motor_CRO_01_Data  : 0|64@1+ (1.000000,0.000000) [0.000000|18446744073709551616.000000] "" Motor_BEV

BO_ 2617226769 XCP_Motor_DTO_01: 64 Motor_BEV
 SG_ XCP_Motor_DTO_01_Data  : 0|64@1+ (1.000000,0.000000) [0.000000|18446744073709551616.000000] "" Vector__XXX

BO_ 1411 ZV_02: 8 ICAS1_Gateway
 SG_ ZV_verriegeln_Anf  : 0|1@1+ (1.000000,0.000000) [0.000000|1.000000] "" Vector__XXX
 SG_ ZV_STSG_HFS_Anf  : 1|1@1+ (1.000000,0.000000) [0.000000|1.000000] "" Vector__XXX
 SG_ ZV_STSG_HBFS_Anf  : 2|1@1+ (1.000000,0.000000) [0.000000|1.000000] "" Vector__XXX
 SG_ ZV_Anf_Challenge_Auth  : 3|1@1+ (1.000000,0.000000) [0.000000|1.000000] "" Vector__XXX
 SG_ BCM_FH_Freigabe  : 12|1@1+ (1.000000,0.000000) [0.000000|1.000000] "" Vector__XXX
 SG_ BCM_Komfortfkt_Freigabe  : 13|1@1+ (1.000000,0.000000) [0.000000|1.000000] "" Vector__XXX
 SG_ BCM_HSK_Freigabe  : 14|1@1+ (1.000000,0.000000) [0.000000|1.000000] "" Vector__XXX
 SG_ BCM_Verdeck_Freigabe  : 15|1@1+ (1.000000,0.000000) [0.000000|1.000000] "" Vector__XXX
 SG_ ZV_verriegelt_intern_ist  : 16|1@1+ (1.000000,0.000000) [0.000000|1.000000] "" Vector__XXX
 SG_ ZV_verriegelt_extern_ist  : 17|1@1+ (1.000000,0.000000) [0.000000|1.000000] "" Airbag
 SG_ ZV_verriegelt_intern_soll  : 18|1@1+ (1.000000,0.000000) [0.000000|1.000000] "" Vector__XXX
 SG_ ZV_verriegelt_extern_soll  : 19|1@1+ (1.000000,0.000000) [0.000000|1.000000] "" Airbag
 SG_ ZV_gesafet_extern_ist  : 20|1@1+ (1.000000,0.000000) [0.000000|1.000000] "" Vector__XXX
 SG_ ZV_gesafet_extern_soll  : 21|1@1+ (1.000000,0.000000) [0.000000|1.000000] "" Vector__XXX
 SG_ ZV_Einzeltuerentriegelung  : 22|1@1+ (1.000000,0.000000) [0.000000|1.000000] "" Vector__XXX
 SG_ ZV_Heckeinzelentriegelung  : 23|1@1+ (1.000000,0.000000) [0.000000|1.000000] "" Vector__XXX
 SG_ ZV_FT_offen  : 24|1@1+ (1.000000,0.000000) [0.000000|1.000000] "" Motor_BEV
 SG_ ZV_BT_offen  : 25|1@1+ (1.000000,0.000000) [0.000000|1.000000] "" Motor_BEV
 SG_ ZV_HFS_offen  : 26|1@1+ (1.000000,0.000000) [0.000000|1.000000] "" Motor_BEV
 SG_ ZV_HBFS_offen  : 27|1@1+ (1.000000,0.000000) [0.000000|1.000000] "" Motor_BEV
 SG_ ZV_HD_offen  : 28|1@1+ (1.000000,0.000000) [0.000000|1.000000] "" Motor_BEV
 SG_ ZV_HS_offen  : 29|1@1+ (1.000000,0.000000) [0.000000|1.000000] "" Vector__XXX
 SG_ IRUE_aktiv  : 30|1@1+ (1.000000,0.000000) [0.000000|1.000000] "" Vector__XXX
 SG_ DWA_aktiv  : 31|1@1+ (1.000000,0.000000) [0.000000|1.000000] "" Vector__XXX
 SG_ FFB_HDF_Taste  : 34|1@1+ (1.000000,0.000000) [0.000000|1.000000] "" Vector__XXX
 SG_ FFB_Panik_Taste  : 35|1@1+ (1.000000,0.000000) [0.000000|1.000000] "" Vector__XXX
 SG_ FFB_Auf_Taste  : 36|1@1+ (1.000000,0.000000) [0.000000|1.000000] "" Vector__XXX
 SG_ FFB_Zu_Taste  : 37|1@1+ (1.000000,0.000000) [0.000000|1.000000] "" Vector__XXX
 SG_ FFB_CarFinder  : 38|1@1+ (1.000000,0.000000) [0.000000|1.000000] "" Vector__XXX
 SG_ FFB_Komfortoeffnen  : 39|1@1+ (1.000000,0.000000) [0.000000|1.000000] "" Vector__XXX
 SG_ FFB_Komfortschliessen  : 40|1@1+ (1.000000,0.000000) [0.000000|1.000000] "" Vector__XXX
 SG_ FBS_IDG_in_Reichweite  : 41|1@1+ (1.000000,0.000000) [0.000000|1.000000] "" Vector__XXX
 SG_ ZV_Schluessel_Zugang  : 42|4@1+ (1.000000,0.000000) [0.000000|15.000000] "" Vector__XXX
 SG_ ZV_SafeFunktion_aktiv  : 46|1@1+ (1.000000,0.000000) [0.000000|1.000000] "" Vector__XXX
 SG_ FBS_Warn_Schluessel_Batt  : 47|1@1+ (1.000000,0.000000) [0.000000|1.000000] "" Vector__XXX
 SG_ ZV_Oeffnungsmodus  : 48|2@1+ (1.000000,0.000000) [0.000000|3.000000] "" Vector__XXX
 SG_ ZV_ist_Zustand_verfuegbar  : 54|1@1+ (1.000000,0.000000) [0.000000|1.000000] "" Vector__XXX
 SG_ IRUE_Taster_Fkts_LED  : 55|1@1+ (1.000000,0.000000) [0.000000|1.000000] "" Vector__XXX
 SG_ ZV_Tankklappe_offen  : 56|1@1+ (1.000000,0.000000) [0.000000|1.000000] "" Vector__XXX
 SG_ ZV_Rollo_auf  : 57|1@1+ (1.000000,0.000000) [0.000000|1.000000] "" Vector__XXX
 SG_ ZV_Rollo_zu  : 58|1@1+ (1.000000,0.000000) [0.000000|1.000000] "" Vector__XXX
 SG_ ZV_SAD_auf  : 59|1@1+ (1.000000,0.000000) [0.000000|1.000000] "" Vector__XXX
 SG_ ZV_SAD_zu  : 60|1@1+ (1.000000,0.000000) [0.000000|1.000000] "" Vector__XXX
 SG_ ZV_verriegelt_soll  : 62|2@1+ (1.000000,0.000000) [0.000000|3.000000] "" Vector__XXX

BU_:  Airbag BAP_Tester ICAS1_Gateway ICAS1_KommunikationsServer LE1 LE2 Motor_BEV Schaltbetaetigung

BO_ 2463978663 VZE_04: 32 ICAS1_Gateway
 SG_ VZE_Anzeigemodus  : 0|2@1+ (1.000000,0.000000) [0.000000|3.000000] "" Vector__XXX
 SG_ VZE_Hinweistext  : 2|3@1+ (1.000000,0.000000) [1.000000|7.000000] "" Motor_BEV
 SG_ VZE_Verkehrszeichen_Einheit  : 8|1@1+ (1.000000,0.000000) [0.000000|1.000000] "" Vector__XXX
 SG_ VZE_Anzeigeunterdrueck_Zeichen_3  : 9|1@1+ (1.000000,0.000000) [0.000000|1.000000] "" Vector__XXX
 SG_ VZE_Anzeigeunterdrueck_Zeichen_2  : 10|1@1+ (1.000000,0.000000) [0.000000|1.000000] "" Vector__XXX
 SG_ VZE_Verkehrszeichen_1  : 11|8@1+ (1.000000,0.000000) [1.000000|255.000000] "" Motor_BEV
 SG_ VZE_Verkehrszeichen_2  : 19|8@1+ (1.000000,0.000000) [1.000000|255.000000] "" Vector__XXX
 SG_ VZE_Verkehrszeichen_3  : 27|8@1+ (1.000000,0.000000) [1.000000|255.000000] "" Vector__XXX
 SG_ VZE_Warnung_Verkehrszeichen_1  : 35|1@1+ (1.000000,0.000000) [0.000000|1.000000] "" Vector__XXX
 SG_ VZE_Warnung_Verkehrszeichen_2  : 36|1@1+ (1.000000,0.000000) [0.000000|1.000000] "" Vector__XXX
 SG_ VZE_Warnung_Verkehrszeichen_3  : 37|1@1+ (1.000000,0.000000) [0.000000|1.000000] "" Vector__XXX
 SG_ VZE_Zusatzschild_1  : 38|4@1+ (1.000000,0.000000) [1.000000|15.000000] "" Vector__XXX
 SG_ VZE_Zusatzschild_2  : 42|4@1+ (1.000000,0.000000) [1.000000|15.000000] "" Vector__XXX
 SG_ VZE_Zusatzschild_3  : 46|4@1+ (1.000000,0.000000) [1.000000|15.000000] "" Vector__XXX
 SG_ VZE_Anzeigeunterdrueck_Zeichen_1  : 50|1@1+ (1.000000,0.000000) [0.000000|1.000000] "" Vector__XXX
 SG_ VZE_Zeichen_01_KameraWied  : 51|1@1+ (1.000000,0.000000) [0.000000|1.000000] "" Motor_BEV
 SG_ VZE_Zeichen_02_KameraWied  : 52|1@1+ (1.000000,0.000000) [0.000000|1.000000] "" Vector__XXX
 SG_ VZE_Zeichen_03_KameraWied  : 53|1@1+ (1.000000,0.000000) [0.000000|1.000000] "" Vector__XXX
 SG_ VZE_Zeichen_01_Kamera  : 54|1@1+ (1.000000,0.000000) [0.000000|1.000000] "" Motor_BEV
 SG_ VZE_Zeichen_01_Karte  : 55|1@1+ (1.000000,0.000000) [0.000000|1.000000] "" Vector__XXX
 SG_ VZE_Zeichen_01_Gesetz  : 56|1@1+ (1.000000,0.000000) [0.000000|1.000000] "" Vector__XXX
 SG_ VZE_Zeichen_02_Kamera  : 57|1@1+ (1.000000,0.000000) [0.000000|1.000000] "" Vector__XXX
 SG_ VZE_Zeichen_02_Karte  : 58|1@1+ (1.000000,0.000000) [0.000000|1.000000] "" Vector__XXX
 SG_ VZE_Zeichen_02_Gesetz  : 59|1@1+ (1.000000,0.000000) [0.000000|1.000000] "" Vector__XXX
 SG_ VZE_Zeichen_03_Kamera  : 60|1@1+ (1.000000,0.000000) [0.000000|1.000000] "" Vector__XXX
 SG_ VZE_Zeichen_03_Karte  : 61|1@1+ (1.000000,0.000000) [0.000000|1.000000] "" Vector__XXX
 SG_ VZE_Zeichen_03_Gesetz  : 62|1@1+ (1.000000,0.000000) [0.000000|1.000000] "" Vector__XXX
 SG_ VZE_Gong  : 63|1@1+ (1.000000,0.000000) [0.000000|1.000000] "" Vector__XXX
 SG_ VZE_Anzeigeunterdrueck_Zeichen_5  : 72|1@1+ (1.000000,0.000000) [0.000000|1.000000] "" Vector__XXX
 SG_ VZE_Zeichen_05_KameraWied  : 73|1@1+ (1.000000,0.000000) [0.000000|1.000000] "" Vector__XXX
 SG_ VZE_Zeichen_05_Kamera  : 74|1@1+ (1.000000,0.000000) [0.000000|1.000000] "" Vector__XXX
 SG_ VZE_Verkehrszeichen_4  : 75|8@1+ (1.000000,0.000000) [1.000000|255.000000] "" Motor_BEV
 SG_ VZE_Verkehrszeichen_5  : 83|8@1+ (1.000000,0.000000) [1.000000|255.000000] "" Motor_BEV
 SG_ VZE_Anhaenger_Vmax  : 91|4@1+ (10.000000,10.000000) [10.000000|140.000000] "Unit_KiloMeterPerHour" Vector__XXX
 SG_ VZE_Zeichen_04_Gesetz  : 95|1@1+ (1.000000,0.000000) [0.000000|1.000000] "" Vector__XXX
 SG_ VZE_Zeichen_04_Kamera  : 96|1@1+ (1.000000,0.000000) [0.000000|1.000000] "" Vector__XXX
 SG_ VZE_Zeichen_04_KameraWied  : 97|1@1+ (1.000000,0.000000) [0.000000|1.000000] "" Vector__XXX
 SG_ VZE_Zeichen_04_Karte  : 98|1@1+ (1.000000,0.000000) [0.000000|1.000000] "" Vector__XXX
 SG_ VZE_Warnung_Verkehrszeichen_4  : 99|1@1+ (1.000000,0.000000) [0.000000|1.000000] "" Vector__XXX
 SG_ VZE_Warnung_Verkehrszeichen_5  : 100|1@1+ (1.000000,0.000000) [0.000000|1.000000] "" Vector__XXX
 SG_ VZE_Zeichen_05_Gesetz  : 101|1@1+ (1.000000,0.000000) [0.000000|1.000000] "" Vector__XXX
 SG_ VZE_Zusatzschild_4  : 102|4@1+ (1.000000,0.000000) [1.000000|15.000000] "" Vector__XXX
 SG_ VZE_Zusatzschild_5  : 106|4@1+ (1.000000,0.000000) [1.000000|15.000000] "" Vector__XXX
 SG_ VZE_Baustelle  : 110|2@1+ (1.000000,0.000000) [0.000000|3.000000] "" Vector__XXX
 SG_ VZE_Zeichen_05_Karte  : 112|1@1+ (1.000000,0.000000) [0.000000|1.000000] "" Vector__XXX
 SG_ VZE_Zeichen_05_Entfernung  : 113|7@1+ (1.000000,0.000000) [1.000000|127.000000] "Unit_Meter" Motor_BEV
 SG_ VZE_Zeichen_05_Entfernung_StdA  : 120|7@1+ (1.000000,0.000000) [1.000000|127.000000] "Unit_Meter" Motor_BEV
 SG_ VZE_Anzeigeunterdrueck_Zeichen_4  : 127|1@1+ (1.000000,0.000000) [0.000000|1.000000] "" Vector__XXX
 SG_ VZE_Verkehrszeichen_6  : 128|8@1+ (1.000000,0.000000) [1.000000|255.000000] "Unit_None" Motor_BEV
 SG_ VZE_Zusatzschild_6  : 136|4@1+ (1.000000,0.000000) [1.000000|15.000000] "" Vector__XXX
 SG_ VZE_Zeichen_06_Entfernung  : 140|7@1+ (1.000000,0.000000) [1.000000|127.000000] "Unit_Meter" Motor_BEV
 SG_ VZE_Zeichen_06_Entfernung_StdA  : 147|7@1+ (1.000000,0.000000) [1.000000|127.000000] "Unit_Meter" Motor_BEV
 SG_ VZE_Umweltinfo_Naesse  : 154|1@1+ (1.000000,0.000000) [0.000000|1.000000] "" Motor_BEV
 SG_ VZE_Umweltinfo_Nebel  : 155|1@1+ (1.000000,0.000000) [0.000000|1.000000] "" Motor_BEV
 SG_ VZE_Umweltinfo_Anhaengerbetrieb  : 156|1@1+ (1.000000,0.000000) [0.000000|1.000000] "" Vector__XXX
 SG_ VZE_Erweiterte_Information  : 157|8@1+ (1.000000,0.000000) [1.000000|255.000000] "Unit_None" Vector__XXX
 SG_ VZE_Tempowarnung_Status  : 165|1@1+ (1.000000,0.000000) [0.000000|1.000000] "" Vector__XXX
 SG_ VZE_Tempowarnung_Einheit  : 166|1@1+ (1.000000,0.000000) [0.000000|1.000000] "" Vector__XXX
 SG_ VZE_Tempowarnung_Offset  : 167|5@1+ (1.000000,0.000000) [1.000000|31.000000] "" Vector__XXX
 SG_ VZE_FoD_Status  : 206|2@1+ (1.000000,0.000000) [0.000000|3.000000] "" Vector__XXX
 SG_ VZE_Anzeige_ZS_1  : 208|4@1+ (1.000000,0.000000) [1.000000|15.000000] "Unit_None" Vector__XXX
 SG_ VZE_Anzeige_ZS_2  : 212|4@1+ (1.000000,0.000000) [1.000000|15.000000] "Unit_None" Vector__XXX
 SG_ VZE_Anzeige_ZS_3  : 216|4@1+ (1.000000,0.000000) [1.000000|15.000000] "Unit_None" Vector__XXX
 SG_ VZE_Hinweistext_03  : 220|4@1+ (1.000000,0.000000) [1.000000|15.000000] "" Vector__XXX
 SG_ VZE_Land  : 224|5@1+ (1.000000,0.000000) [1.000000|31.000000] "" Vector__XXX
 SG_ VZE_Warnung_VZ_1  : 229|1@1+ (1.000000,0.000000) [0.000000|1.000000] "" Vector__XXX
 SG_ VZE_Warnung_VZ_2  : 230|1@1+ (1.000000,0.000000) [0.000000|1.000000] "" Vector__XXX
 SG_ VZE_Warnung_VZ_3  : 231|1@1+ (1.000000,0.000000) [0.000000|1.000000] "" Vector__XXX
 SG_ VZE_Anzeige_VZ_1  : 232|8@1+ (1.000000,0.000000) [1.000000|255.000000] "" Vector__XXX
 SG_ VZE_Anzeige_VZ_2  : 240|8@1+ (1.000000,0.000000) [1.000000|255.000000] "Unit_None" Vector__XXX
 SG_ VZE_Anzeige_VZ_3  : 248|8@1+ (1.000000,0.000000) [1.000000|255.000000] "Unit_None" Vector__XXX

BO_ 181 Waehlhebel_04: 8 ICAS1_Gateway
 SG_ Waehlhebel_04_CRC  : 0|8@1+ (1.000000,0.000000) [0.000000|255.000000] "" Motor_BEV
 SG_ Waehlhebel_04_BZ  : 8|4@1+ (1.000000,0.000000) [0.000000|15.000000] "" Motor_BEV
 SG_ WH_gespeicherte_Fahrstufe  : 12|3@1+ (1.000000,0.000000) [0.000000|7.000000] "" Vector__XXX
 SG_ WH_Initialisierung  : 15|1@1+ (1.000000,0.000000) [0.000000|1.000000] "" Motor_BEV
 SG_ WH_SensorPos_roh  : 16|4@1+ (1.000000,0.000000) [0.000000|15.000000] "" Motor_BEV
 SG_ WH_SensorPos_roh_inv  : 20|4@1+ (1.000000,0.000000) [0.000000|15.000000] "" Motor_BEV
 SG_ WH_Testergebnis  : 24|8@1+ (1.000000,0.000000) [0.000000|255.000000] "" Vector__XXX
 SG_ WH_Test_Aktiv  : 32|1@1+ (1.000000,0.000000) [0.000000|1.000000] "" Vector__XXX
 SG_ WH_Ist_Haltemagnet  : 33|2@1+ (1.000000,0.000000) [0.000000|3.000000] "" Motor_BEV
 SG_ WH_Variante  : 35|4@1+ (1.000000,0.000000) [0.000000|15.000000] "" Motor_BEV
 SG_ WH_Entsperrtaste_02  : 39|2@1+ (1.000000,0.000000) [0.000000|3.000000] "" Motor_BEV
 SG_ WH_P_Taste  : 41|2@1+ (1.000000,0.000000) [0.000000|3.000000] "" Motor_BEV
 SG_ WH_Ende_N_Haltephase  : 43|1@1+ (1.000000,0.000000) [0.000000|1.000000] "" Vector__XXX
 SG_ WH_Fahrstufe  : 44|4@1+ (1.000000,0.000000) [0.000000|15.000000] "" Motor_BEV
 SG_ WH_Status_Shiftlock  : 48|3@1+ (1.000000,0.000000) [0.000000|7.000000] "" Motor_BEV
 SG_ WH_Zustand_N_Haltephase  : 51|2@1+ (1.000000,0.000000) [0.000000|3.000000] "" Vector__XXX

BO_ 2463978687 Waehlhebel_06: 8 ICAS1_Gateway
 SG_ WH_Fehler_Haltemagnet_Status  : 41|1@1+ (1.000000,0.000000) [0.000000|1.000000] "" Motor_BEV
 SG_ WH_Fehler_CRC_SBM  : 42|1@1+ (1.000000,0.000000) [0.000000|1.000000] "" Motor_BEV
 SG_ WH_Fehler_CRC_SBM_Status  : 43|1@1+ (1.000000,0.000000) [0.000000|1.000000] "" Motor_BEV
 SG_ WH_Fehler_Timeout_SBM  : 44|1@1+ (1.000000,0.000000) [0.000000|1.000000] "" Motor_BEV
 SG_ WH_Fehler_Timeout_SBM_Status  : 45|1@1+ (1.000000,0.000000) [0.000000|1.000000] "" Motor_BEV
 SG_ WH_Fehler_Ueberspannung  : 46|1@1+ (1.000000,0.000000) [0.000000|1.000000] "" Motor_BEV
 SG_ WH_Fehler_Ueberspannung_Status  : 47|1@1+ (1.000000,0.000000) [0.000000|1.000000] "" Motor_BEV
 SG_ WH_Fehler_BZ_SBM  : 48|1@1+ (1.000000,0.000000) [0.000000|1.000000] "" Motor_BEV
 SG_ WH_Fehler_BZ_SBM_Status  : 49|1@1+ (1.000000,0.000000) [0.000000|1.000000] "" Motor_BEV
 SG_ WH_Fehler_Unterspannung  : 50|1@1+ (1.000000,0.000000) [0.000000|1.000000] "" Motor_BEV
 SG_ WH_Fehler_Unterspannung_Status  : 51|1@1+ (1.000000,0.000000) [0.000000|1.000000] "" Motor_BEV
 SG_ WH_Fehler_Ausleuchtung  : 52|1@1+ (1.000000,0.000000) [0.000000|1.000000] "" Motor_BEV
 SG_ WH_Fehler_Ausleuchtung_Status  : 53|1@1+ (1.000000,0.000000) [0.000000|1.000000] "" Motor_BEV
 SG_ WH_Fehler_Entsperrtaste  : 54|1@1+ (1.000000,0.000000) [0.000000|1.000000] "" Motor_BEV
 SG_ WH_Fehler_Entsperrtaste_Status  : 55|1@1+ (1.000000,0.000000) [0.000000|1.000000] "" Motor_BEV
 SG_ WH_Fehler_P_Taste  : 56|1@1+ (1.000000,0.000000) [0.000000|1.000000] "" Motor_BEV
 SG_ WH_Fehler_P_Taste_Status  : 57|1@1+ (1.000000,0.000000) [0.000000|1.000000] "" Motor_BEV
 SG_ WH_Fehler_Sensor_einfach  : 58|1@1+ (1.000000,0.000000) [0.000000|1.000000] "" Motor_BEV
 SG_ WH_Fehler_Sensor_einfach_Status  : 59|1@1+ (1.000000,0.000000) [0.000000|1.000000] "" Motor_BEV
 SG_ WH_Fehler_Sensor_mehrfach  : 60|1@1+ (1.000000,0.000000) [0.000000|1.000000] "" Motor_BEV
 SG_ WH_Fehler_Sensor_mehrfach_Status  : 61|1@1+ (1.000000,0.000000) [0.000000|1.000000] "" Motor_BEV
 SG_ WH_Fehler_Shiftlock  : 62|1@1+ (1.000000,0.000000) [0.000000|1.000000] "" Motor_BEV
 SG_ WH_Fehler_Shiftlock_Status  : 63|1@1+ (1.000000,0.000000) [0.000000|1.000000] "" Motor_BEV

BO_ 916 WBA_03: 8 Motor_BEV
 SG_ WBA_03_CRC  : 0|8@1+ (1.000000,0.000000) [0.000000|255.000000] "" ICAS1_Gateway
 SG_ WBA_03_BZ  : 8|4@1+ (1.000000,0.000000) [0.000000|15.000000] "" ICAS1_Gateway
 SG_ WBA_Fahrstufe_02  : 12|4@1+ (1.000000,0.000000) [0.000000|15.000000] "" ICAS1_Gateway ICAS1_KommunikationsServer
 SG_ WBA_ZielFahrstufe  : 16|4@1+ (1.000000,0.000000) [0.000000|15.000000] "" ICAS1_Gateway
 SG_ WBA_GE_Warnung_02  : 20|4@1+ (1.000000,0.000000) [0.000000|15.000000] "" ICAS1_Gateway
 SG_ WBA_eing_Gang_02  : 24|4@1+ (1.000000,0.000000) [0.000000|15.000000] "" ICAS1_Gateway
 SG_ WBA_GE_Texte  : 28|3@1+ (1.000000,0.000000) [0.000000|7.000000] "" ICAS1_Gateway
 SG_ WBA_Segeln_aktiv  : 31|1@1+ (1.000000,0.000000) [0.000000|1.000000] "" ICAS1_Gateway
 SG_ WBA_Schaltschema_02  : 32|3@1+ (1.000000,0.000000) [0.000000|7.000000] "" ICAS1_Gateway
 SG_ WBA_Schaltschema_FS_inaktiv  : 35|2@1+ (1.000000,0.000000) [0.000000|3.000000] "" ICAS1_Gateway
 SG_ WBA_GE_Zusatzwarnungen  : 37|3@1+ (1.000000,0.000000) [0.000000|7.000000] "" ICAS1_Gateway
 SG_ GE_Sollgang  : 40|4@1+ (1.000000,0.000000) [0.000000|15.000000] "" ICAS1_Gateway
 SG_ GE_Tipschaltempf_verfuegbar  : 44|1@1+ (1.000000,0.000000) [0.000000|1.000000] "" ICAS1_Gateway
 SG_ WBA_GE_Texte_02  : 45|3@1+ (1.000000,0.000000) [0.000000|7.000000] "" ICAS1_Gateway
 SG_ WBA_Schaltschema_Tippgasse  : 48|1@1+ (1.000000,0.000000) [0.000000|1.000000] "" ICAS1_Gateway
 SG_ WBA_Schaltschema_Fahreraktion  : 49|1@1+ (1.000000,0.000000) [0.000000|1.000000] "" ICAS1_Gateway
 SG_ WBA_Schaltschema_FS_vorwaerts  : 50|2@1+ (1.000000,0.000000) [0.000000|3.000000] "" ICAS1_Gateway
 SG_ WBA_Shiftlock_Lampe  : 52|1@1+ (1.000000,0.000000) [0.000000|1.000000] "" ICAS1_Gateway
 SG_ WBA_Anforderung_Akustik  : 53|1@1+ (1.000000,0.000000) [0.000000|1.000000] "" ICAS1_Gateway
 SG_ WBA_Blinken  : 54|1@1+ (1.000000,0.000000) [0.000000|1.000000] "" ICAS1_Gateway
 SG_ GE_Wiederstart_Anz_Std  : 55|1@1+ (1.000000,0.000000) [0.000000|1.000000] "" ICAS1_Gateway
 SG_ GE_Stoppverbot_Anz_01  : 56|1@1+ (1.000000,0.000000) [0.000000|1.000000] "" ICAS1_Gateway
 SG_ GE_Stoppverbot_Anz_02  : 57|1@1+ (1.000000,0.000000) [0.000000|1.000000] "" ICAS1_Gateway
 SG_ GE_Stoppverbot_Anz_03  : 58|1@1+ (1.000000,0.000000) [0.000000|1.000000] "" ICAS1_Gateway
 SG_ GE_Stoppverbot_Anz_04  : 59|1@1+ (1.000000,0.000000) [0.000000|1.000000] "" ICAS1_Gateway
 SG_ GE_Stoppverbot_Anz_05  : 60|1@1+ (1.000000,0.000000) [0.000000|1.000000] "" ICAS1_Gateway
 SG_ GE_Stoppverbot_Anz_06  : 61|1@1+ (1.000000,0.000000) [0.000000|1.000000] "" ICAS1_Gateway
 SG_ GE_Stoppverbot_Anz_07  : 62|1@1+ (1.000000,0.000000) [0.000000|1.000000] "" ICAS1_Gateway
 SG_ GE_Stoppverbot_Anz_Std  : 63|1@1+ (1.000000,0.000000) [0.000000|1.000000] "" ICAS1_Gateway

BO_ 1361 WFS_01: 8 ICAS1_Gateway
 SG_ WFS_Schluessel_Fahrberecht  : 0|4@1+ (1.000000,0.000000) [0.000000|15.000000] "" Vector__XXX
 SG_ WFS_Verbauinfo_ELV  : 4|1@1+ (1.000000,0.000000) [0.000000|1.000000] "" Vector__XXX
 SG_ WFS_ID_Geb_autorisiert  : 5|1@1+ (1.000000,0.000000) [0.000000|1.000000] "" Vector__XXX
 SG_ WFS_ID_Geb_autorisiert_in_Kl15  : 6|1@1+ (1.000000,0.000000) [0.000000|1.000000] "" Vector__XXX
 SG_ WFS_ID_Geb_steckt  : 7|1@1+ (1.000000,0.000000) [0.000000|1.000000] "" Vector__XXX
 SG_ WFS_Schluessel_Soll  : 8|4@1+ (1.000000,0.000000) [0.000000|15.000000] "" Vector__XXX
 SG_ WFS_Schluessel_Ist  : 12|4@1+ (1.000000,0.000000) [0.000000|15.000000] "" Vector__XXX
 SG_ WFS_Safe  : 16|1@1+ (1.000000,0.000000) [0.000000|1.000000] "" Vector__XXX
 SG_ WFS_LZ  : 17|2@1+ (1.000000,0.000000) [0.000000|3.000000] "" Vector__XXX
 SG_ WFS_ELV_authorisiert  : 19|1@1+ (1.000000,0.000000) [0.000000|1.000000] "" Vector__XXX
 SG_ WFS_LF_Aktiv  : 20|1@1+ (1.000000,0.000000) [0.000000|1.000000] "" Vector__XXX
 SG_ WFS_Betrieb_Lesespule  : 21|1@1+ (1.000000,0.000000) [0.000000|1.000000] "" Vector__XXX
 SG_ WFS_Klemmenfreigabe  : 22|1@1+ (1.000000,0.000000) [0.000000|1.000000] "" Motor_BEV
 SG_ WFS_Klemmenfreigabe_Signatur  : 23|11@1+ (1.000000,0.000000) [0.000000|2047.000000] "" Vector__XXX
 SG_ WFS_Fahrerhinweise  : 34|2@1+ (1.000000,0.000000) [0.000000|3.000000] "" Vector__XXX
 SG_ WFS_Parken_Status  : 36|2@1+ (1.000000,0.000000) [0.000000|3.000000] "" Vector__XXX

BO_ 2617028096 XCP_Airbag_CRO_01: 64 Vector__XXX
 SG_ XCP_Airbag_CRO_01_Data  : 0|512@1+ (1.000000,0.000000) [0.000000|13407807929942597099574024998205846127479365820592393377723561443721764030073546976801874298166903427690031858186486050853753882811946569946433649006084096.000000] "" Airbag

BO_ 2617028097 XCP_Airbag_DTO_01: 64 Airbag
 SG_ XCP_Airbag_DTO_01_Data  : 0|512@1+ (1.000000,0.000000) [0.000000|13407807929942597099574024998205846127479365820592393377723561443721764030073546976801874298166903427690031858186486050853753882811946569946433649006084096.000000] "" Vector__XXX

BO_ 2617239040 XCP_EMotor_01_CRO_01: 64 Vector__XXX
 SG_ XCP_EMotor_01_CRO_01_Data  : 0|64@1+ (1.000000,0.000000) [0.000000|18446744073709551616.000000] "" LE1

BO_ 2617239041 XCP_EMotor_01_DTO_01: 64 LE1
 SG_ XCP_EMotor_01_DTO_01_Data  : 0|64@1+ (1.000000,0.000000) [0.000000|18446744073709551616.000000] "" Vector__XXX

BO_ 2617239042 XCP_EMotor_01_DTO_02: 64 LE1
 SG_ XCP_EMotor_01_DTO_02_Data  : 0|64@1+ (1.000000,0.000000) [0.000000|18446744073709551616.000000] "" Vector__XXX

BO_ 2617239043 XCP_EMotor_01_DTO_03: 64 LE1
 SG_ XCP_EMotor_01_DTO_03_Data  : 0|64@1+ (1.000000,0.000000) [0.000000|18446744073709551616.000000] "" Vector__XXX

BO_ 2617239044 XCP_EMotor_01_DTO_04: 64 LE1
 SG_ XCP_EMotor_01_DTO_04_Data  : 0|64@1+ (1.000000,0.000000) [0.000000|18446744073709551616.000000] "" Vector__XXX

BO_ 2617122304 XCP_EMotor_02_CRO_01: 64 Vector__XXX
 SG_ XCP_EMotor_02_CRO_01_Data  : 0|64@1+ (1.000000,0.000000) [0.000000|18446744073709551616.000000] "" LE2

BO_ 2617122305 XCP_EMotor_02_DTO_01: 64 LE2
 SG_ XCP_EMotor_02_DTO_01_Data  : 0|64@1+ (1.000000,0.000000) [0.000000|18446744073709551616.000000] "" Vector__XXX

BO_ 2617122306 XCP_EMotor_02_DTO_02: 64 LE2
 SG_ XCP_EMotor_02_DTO_02_Data  : 0|64@1+ (1.000000,0.000000) [0.000000|18446744073709551616.000000] "" Vector__XXX

BO_ 2617122307 XCP_EMotor_02_DTO_03: 64 LE2
 SG_ XCP_EMotor_02_DTO_03_Data  : 0|64@1+ (1.000000,0.000000) [0.000000|18446744073709551616.000000] "" Vector__XXX

BO_ 2617122308 XCP_EMotor_02_DTO_04: 64 LE2
 SG_ XCP_EMotor_02_DTO_04_Data  : 0|64@1+ (1.000000,0.000000) [0.000000|18446744073709551616.000000] "" Vector__XXX

BO_ 2617226768 XCP_Motor_CRO_01: 64 Vector__XXX
 SG_ XCP_Motor_CRO_01_Data  : 0|64@1+ (1.000000,0.000000) [0.000000|18446744073709551616.000000] "" Motor_BEV

BO_ 2617226769 XCP_Motor_DTO_01: 64 Motor_BEV
 SG_ XCP_Motor_DTO_01_Data  : 0|64@1+ (1.000000,0.000000) [0.000000|18446744073709551616.000000] "" Vector__XXX

BO_ 1411 ZV_02: 8 ICAS1_Gateway
 SG_ ZV_verriegeln_Anf  : 0|1@1+ (1.000000,0.000000) [0.000000|1.000000] "" Vector__XXX
 SG_ ZV_STSG_HFS_Anf  : 1|1@1+ (1.000000,0.000000) [0.000000|1.000000] "" Vector__XXX
 SG_ ZV_STSG_HBFS_Anf  : 2|1@1+ (1.000000,0.000000) [0.000000|1.000000] "" Vector__XXX
 SG_ ZV_Anf_Challenge_Auth  : 3|1@1+ (1.000000,0.000000) [0.000000|1.000000] "" Vector__XXX
 SG_ BCM_FH_Freigabe  : 12|1@1+ (1.000000,0.000000) [0.000000|1.000000] "" Vector__XXX
 SG_ BCM_Komfortfkt_Freigabe  : 13|1@1+ (1.000000,0.000000) [0.000000|1.000000] "" Vector__XXX
 SG_ BCM_HSK_Freigabe  : 14|1@1+ (1.000000,0.000000) [0.000000|1.000000] "" Vector__XXX
 SG_ BCM_Verdeck_Freigabe  : 15|1@1+ (1.000000,0.000000) [0.000000|1.000000] "" Vector__XXX
 SG_ ZV_verriegelt_intern_ist  : 16|1@1+ (1.000000,0.000000) [0.000000|1.000000] "" Vector__XXX
 SG_ ZV_verriegelt_extern_ist  : 17|1@1+ (1.000000,0.000000) [0.000000|1.000000] "" Airbag
 SG_ ZV_verriegelt_intern_soll  : 18|1@1+ (1.000000,0.000000) [0.000000|1.000000] "" Vector__XXX
 SG_ ZV_verriegelt_extern_soll  : 19|1@1+ (1.000000,0.000000) [0.000000|1.000000] "" Airbag
 SG_ ZV_gesafet_extern_ist  : 20|1@1+ (1.000000,0.000000) [0.000000|1.000000] "" Vector__XXX
 SG_ ZV_gesafet_extern_soll  : 21|1@1+ (1.000000,0.000000) [0.000000|1.000000] "" Vector__XXX
 SG_ ZV_Einzeltuerentriegelung  : 22|1@1+ (1.000000,0.000000) [0.000000|1.000000] "" Vector__XXX
 SG_ ZV_Heckeinzelentriegelung  : 23|1@1+ (1.000000,0.000000) [0.000000|1.000000] "" Vector__XXX
 SG_ ZV_FT_offen  : 24|1@1+ (1.000000,0.000000) [0.000000|1.000000] "" Motor_BEV
 SG_ ZV_BT_offen  : 25|1@1+ (1.000000,0.000000) [0.000000|1.000000] "" Motor_BEV
 SG_ ZV_HFS_offen  : 26|1@1+ (1.000000,0.000000) [0.000000|1.000000] "" Motor_BEV
 SG_ ZV_HBFS_offen  : 27|1@1+ (1.000000,0.000000) [0.000000|1.000000] "" Motor_BEV
 SG_ ZV_HD_offen  : 28|1@1+ (1.000000,0.000000) [0.000000|1.000000] "" Motor_BEV
 SG_ ZV_HS_offen  : 29|1@1+ (1.000000,0.000000) [0.000000|1.000000] "" Vector__XXX
 SG_ IRUE_aktiv  : 30|1@1+ (1.000000,0.000000) [0.000000|1.000000] "" Vector__XXX
 SG_ DWA_aktiv  : 31|1@1+ (1.000000,0.000000) [0.000000|1.000000] "" Vector__XXX
 SG_ FFB_HDF_Taste  : 34|1@1+ (1.000000,0.000000) [0.000000|1.000000] "" Vector__XXX
 SG_ FFB_Panik_Taste  : 35|1@1+ (1.000000,0.000000) [0.000000|1.000000] "" Vector__XXX
 SG_ FFB_Auf_Taste  : 36|1@1+ (1.000000,0.000000) [0.000000|1.000000] "" Vector__XXX
 SG_ FFB_Zu_Taste  : 37|1@1+ (1.000000,0.000000) [0.000000|1.000000] "" Vector__XXX
 SG_ FFB_CarFinder  : 38|1@1+ (1.000000,0.000000) [0.000000|1.000000] "" Vector__XXX
 SG_ FFB_Komfortoeffnen  : 39|1@1+ (1.000000,0.000000) [0.000000|1.000000] "" Vector__XXX
 SG_ FFB_Komfortschliessen  : 40|1@1+ (1.000000,0.000000) [0.000000|1.000000] "" Vector__XXX
 SG_ FBS_IDG_in_Reichweite  : 41|1@1+ (1.000000,0.000000) [0.000000|1.000000] "" Vector__XXX
 SG_ ZV_Schluessel_Zugang  : 42|4@1+ (1.000000,0.000000) [0.000000|15.000000] "" Vector__XXX
 SG_ ZV_SafeFunktion_aktiv  : 46|1@1+ (1.000000,0.000000) [0.000000|1.000000] "" Vector__XXX
 SG_ FBS_Warn_Schluessel_Batt  : 47|1@1+ (1.000000,0.000000) [0.000000|1.000000] "" Vector__XXX
 SG_ ZV_Oeffnungsmodus  : 48|2@1+ (1.000000,0.000000) [0.000000|3.000000] "" Vector__XXX
 SG_ ZV_ist_Zustand_verfuegbar  : 54|1@1+ (1.000000,0.000000) [0.000000|1.000000] "" Vector__XXX
 SG_ IRUE_Taster_Fkts_LED  : 55|1@1+ (1.000000,0.000000) [0.000000|1.000000] "" Vector__XXX
 SG_ ZV_Tankklappe_offen  : 56|1@1+ (1.000000,0.000000) [0.000000|1.000000] "" Vector__XXX
 SG_ ZV_Rollo_auf  : 57|1@1+ (1.000000,0.000000) [0.000000|1.000000] "" Vector__XXX
 SG_ ZV_Rollo_zu  : 58|1@1+ (1.000000,0.000000) [0.000000|1.000000] "" Vector__XXX
 SG_ ZV_SAD_auf  : 59|1@1+ (1.000000,0.000000) [0.000000|1.000000] "" Vector__XXX
 SG_ ZV_SAD_zu  : 60|1@1+ (1.000000,0.000000) [0.000000|1.000000] "" Vector__XXX
 SG_ ZV_verriegelt_soll  : 62|2@1+ (1.000000,0.000000) [0.000000|3.000000] "" Vector__XXX
